VERSION ""

NS_ :

BS_:

BU_: Vector__XXX

BO_ 2566588414 NTEHV: 68 Vector__XXX
SG_ NOxTrackValdNOxLifetmEgRnTmBin1 : 0|32@1+ (1,0) [0|4211081215] "s" Vector__XXX
SG_ NOxTrackValdNOxLifetmEgRnTmBin2 : 32|32@1+ (1,0) [0|4211081215] "s" Vector__XXX
SG_ NOxTrackValdNOxLifetmEgRnTmBin3 : 64|32@1+ (1,0) [0|4211081215] "s" Vector__XXX
SG_ NOxTrackValdNOxLifetmEgRnTmBin4 : 96|32@1+ (1,0) [0|4211081215] "s" Vector__XXX
SG_ NOxTrackValdNOxLifetmEgRnTmBin5 : 128|32@1+ (1,0) [0|4211081215] "s" Vector__XXX
SG_ NOxTrackValdNOxLifetmEgRnTmBin6 : 160|32@1+ (1,0) [0|4211081215] "s" Vector__XXX
SG_ NOxTrackValdNOxLifetmEgRnTmBin7 : 192|32@1+ (1,0) [0|4211081215] "s" Vector__XXX
SG_ NOxTrackValdNOxLifetmEgRnTmBin8 : 224|32@1+ (1,0) [0|4211081215] "s" Vector__XXX
SG_ NOxTrackValdNOxLifetmEgRnTmBin9 : 256|32@1+ (1,0) [0|4211081215] "s" Vector__XXX
SG_ NOxTrackValdNOxLifetmEgRnTmBin10 : 288|32@1+ (1,0) [0|4211081215] "s" Vector__XXX
SG_ NOxTrackValdNOxLifetmEgRnTmBin11 : 320|32@1+ (1,0) [0|4211081215] "s" Vector__XXX
SG_ NOxTrackValdNOxLifetmEgRnTmBin12 : 352|32@1+ (1,0) [0|4211081215] "s" Vector__XXX
SG_ NOxTrackValdNOxLifetmEgRnTmBin13 : 384|32@1+ (1,0) [0|4211081215] "s" Vector__XXX
SG_ NOxTrackValdNOxLifetmEgRnTmBin14 : 416|32@1+ (1,0) [0|4211081215] "s" Vector__XXX
SG_ NOxTrackValdNOxLifetmEgRnTmBin15 : 448|32@1+ (1,0) [0|4211081215] "s" Vector__XXX
SG_ NOxTrackValdNOxLifetmEgRnTmBin16 : 480|32@1+ (1,0) [0|4211081215] "s" Vector__XXX
SG_ NOxTrackValdNOxLifetmEgRnTmBin17 : 512|32@1+ (1,0) [0|4211081215] "s" Vector__XXX

BO_ 2566588670 NTVMV: 68 Vector__XXX
SG_ NOxTrackValdNOxLifetmVhclDstBin1 : 0|32@1+ (5,0) [0|21055406075] "m" Vector__XXX
SG_ NOxTrackValdNOxLifetmVhclDstBin2 : 32|32@1+ (5,0) [0|21055406075] "m" Vector__XXX
SG_ NOxTrackValdNOxLifetmVhclDstBin3 : 64|32@1+ (5,0) [0|21055406075] "m" Vector__XXX
SG_ NOxTrackValdNOxLifetmVhclDstBin4 : 96|32@1+ (5,0) [0|21055406075] "m" Vector__XXX
SG_ NOxTrackValdNOxLifetmVhclDstBin5 : 128|32@1+ (5,0) [0|21055406075] "m" Vector__XXX
SG_ NOxTrackValdNOxLifetmVhclDstBin6 : 160|32@1+ (5,0) [0|21055406075] "m" Vector__XXX
SG_ NOxTrackValdNOxLifetmVhclDstBin7 : 192|32@1+ (5,0) [0|21055406075] "m" Vector__XXX
SG_ NOxTrackValdNOxLifetmVhclDstBin8 : 224|32@1+ (5,0) [0|21055406075] "m" Vector__XXX
SG_ NOxTrackValdNOxLifetmVhclDstBin9 : 256|32@1+ (5,0) [0|21055406075] "m" Vector__XXX
SG_ NOxTrackValNOxLifetmVhclDstBin10 : 288|32@1+ (5,0) [0|21055406075] "m" Vector__XXX
SG_ NOxTrackValNOxLifetmVhclDstBin11 : 320|32@1+ (5,0) [0|21055406075] "m" Vector__XXX
SG_ NOxTrackValNOxLifetmVhclDstBin12 : 352|32@1+ (5,0) [0|21055406075] "m" Vector__XXX
SG_ NOxTrackValNOxLifetmVhclDstBin13 : 384|32@1+ (5,0) [0|21055406075] "m" Vector__XXX
SG_ NOxTrackValNOxLifetmVhclDstBin14 : 416|32@1+ (5,0) [0|21055406075] "m" Vector__XXX
SG_ NOxTrackValNOxLifetmVhclDstBin15 : 448|32@1+ (5,0) [0|21055406075] "m" Vector__XXX
SG_ NOxTrackValNOxLifetmVhclDstBin16 : 480|32@1+ (5,0) [0|21055406075] "m" Vector__XXX
SG_ NOxTrackValNOxLifetmVhclDstBin17 : 512|32@1+ (5,0) [0|21055406075] "m" Vector__XXX

BO_ 2566588926 NTEEV: 68 Vector__XXX
SG_ NOxTrackValNOxLifetmEgOutEgyBin1 : 0|32@1+ (1,0) [0|4211081215] "kWh" Vector__XXX
SG_ NOxTrackValNOxLifetmEgOutEgyBin2 : 32|32@1+ (1,0) [0|4211081215] "kWh" Vector__XXX
SG_ NOxTrackValNOxLifetmEgOutEgyBin3 : 64|32@1+ (1,0) [0|4211081215] "kWh" Vector__XXX
SG_ NOxTrackValNOxLifetmEgOutEgyBin4 : 96|32@1+ (1,0) [0|4211081215] "kWh" Vector__XXX
SG_ NOxTrackValNOxLifetmEgOutEgyBin5 : 128|32@1+ (1,0) [0|4211081215] "kWh" Vector__XXX
SG_ NOxTrackValNOxLifetmEgOutEgyBin6 : 160|32@1+ (1,0) [0|4211081215] "kWh" Vector__XXX
SG_ NOxTrackValNOxLifetmEgOutEgyBin7 : 192|32@1+ (1,0) [0|4211081215] "kWh" Vector__XXX
SG_ NOxTrackValNOxLifetmEgOutEgyBin8 : 224|32@1+ (1,0) [0|4211081215] "kWh" Vector__XXX
SG_ NOxTrackValNOxLifetmEgOutEgyBin9 : 256|32@1+ (1,0) [0|4211081215] "kWh" Vector__XXX
SG_ NOxTrackValNOxLftmEgOutEgyBin10 : 288|32@1+ (1,0) [0|4211081215] "kWh" Vector__XXX
SG_ NOxTrackValNOxLftmEgOutEgyBin11 : 320|32@1+ (1,0) [0|4211081215] "kWh" Vector__XXX
SG_ NOxTrackValNOxLftmEgOutEgyBin12 : 352|32@1+ (1,0) [0|4211081215] "kWh" Vector__XXX
SG_ NOxTrackValNOxLftmEgOutEgyBin13 : 384|32@1+ (1,0) [0|4211081215] "kWh" Vector__XXX
SG_ NOxTrackValNOxLftmEgOutEgyBin14 : 416|32@1+ (1,0) [0|4211081215] "kWh" Vector__XXX
SG_ NOxTrackValNOxLftmEgOutEgyBin15 : 448|32@1+ (1,0) [0|4211081215] "kWh" Vector__XXX
SG_ NOxTrackValNOxLftmEgOutEgyBin16 : 480|32@1+ (1,0) [0|4211081215] "kWh" Vector__XXX
SG_ NOxTrackValNOxLftmEgOutEgyBin17 : 512|32@1+ (1,0) [0|4211081215] "kWh" Vector__XXX

BO_ 2566589182 NTENV: 68 Vector__XXX
SG_ NOxTrckValNOxLftEgOutNOxMassBin1 : 0|32@1+ (1,0) [0|4211081215] "g" Vector__XXX
SG_ NOxTrckValNOxLftEgOutNOxMassBin2 : 32|32@1+ (1,0) [0|4211081215] "g" Vector__XXX
SG_ NOxTrckValNOxLftEgOutNOxMassBin3 : 64|32@1+ (1,0) [0|4211081215] "g" Vector__XXX
SG_ NOxTrckValNOxLftEgOutNOxMassBin4 : 96|32@1+ (1,0) [0|4211081215] "g" Vector__XXX
SG_ NOxTrckValNOxLftEgOutNOxMassBin5 : 128|32@1+ (1,0) [0|4211081215] "g" Vector__XXX
SG_ NOxTrckValNOxLftEgOutNOxMassBin6 : 160|32@1+ (1,0) [0|4211081215] "g" Vector__XXX
SG_ NOxTrckValNOxLftEgOutNOxMassBin7 : 192|32@1+ (1,0) [0|4211081215] "g" Vector__XXX
SG_ NOxTrckValNOxLftEgOutNOxMassBin8 : 224|32@1+ (1,0) [0|4211081215] "g" Vector__XXX
SG_ NOxTrckValNOxLftEgOutNOxMassBin9 : 256|32@1+ (1,0) [0|4211081215] "g" Vector__XXX
SG_ NOxTrckValNOxLftmEgOutNOxMssBn10 : 288|32@1+ (1,0) [0|4211081215] "g" Vector__XXX
SG_ NOxTrckValNOxLftmEgOutNOxMssBn11 : 320|32@1+ (1,0) [0|4211081215] "g" Vector__XXX
SG_ NOxTrckValNOxLftmEgOutNOxMssBn12 : 352|32@1+ (1,0) [0|4211081215] "g" Vector__XXX
SG_ NOxTrckValNOxLftmEgOutNOxMssBn13 : 384|32@1+ (1,0) [0|4211081215] "g" Vector__XXX
SG_ NOxTrckValNOxLftmEgOutNOxMssBn14 : 416|32@1+ (1,0) [0|4211081215] "g" Vector__XXX
SG_ NOxTrckValNOxLftmEgOutNOxMssBn15 : 448|32@1+ (1,0) [0|4211081215] "g" Vector__XXX
SG_ NOxTrckValNOxLftmEgOutNOxMssBn16 : 480|32@1+ (1,0) [0|4211081215] "g" Vector__XXX
SG_ NOxTrckValNOxLftmEgOutNOxMssBn17 : 512|32@1+ (1,0) [0|4211081215] "g" Vector__XXX

BO_ 2566589438 NTSNV: 68 Vector__XXX
SG_ NOxTrckValNOxLftmSysOutNOxMssBn1 : 0|32@1+ (1,0) [0|4211081215] "g" Vector__XXX
SG_ NOxTrckValNOxLftmSysOutNOxMssBn2 : 32|32@1+ (1,0) [0|4211081215] "g" Vector__XXX
SG_ NOxTrckValNOxLftmSysOutNOxMssBn3 : 64|32@1+ (1,0) [0|4211081215] "g" Vector__XXX
SG_ NOxTrckValNOxLftmSysOutNOxMssBn4 : 96|32@1+ (1,0) [0|4211081215] "g" Vector__XXX
SG_ NOxTrckValNOxLftmSysOutNOxMssBn5 : 128|32@1+ (1,0) [0|4211081215] "g" Vector__XXX
SG_ NOxTrckValNOxLftmSysOutNOxMssBn6 : 160|32@1+ (1,0) [0|4211081215] "g" Vector__XXX
SG_ NOxTrckValNOxLftmSysOutNOxMssBn7 : 192|32@1+ (1,0) [0|4211081215] "g" Vector__XXX
SG_ NOxTrckValNOxLftmSysOutNOxMssBn8 : 224|32@1+ (1,0) [0|4211081215] "g" Vector__XXX
SG_ NOxTrckValNOxLftmSysOutNOxMssBn9 : 256|32@1+ (1,0) [0|4211081215] "g" Vector__XXX
SG_ NOxTrckValNOxLftSysOutNOxMssBn10 : 288|32@1+ (1,0) [0|4211081215] "g" Vector__XXX
SG_ NOxTrckValNOxLftSysOutNOxMssBn11 : 320|32@1+ (1,0) [0|4211081215] "g" Vector__XXX
SG_ NOxTrckValNOxLftSysOutNOxMssBn12 : 352|32@1+ (1,0) [0|4211081215] "g" Vector__XXX
SG_ NOxTrckValNOxLftSysOutNOxMssBn13 : 384|32@1+ (1,0) [0|4211081215] "g" Vector__XXX
SG_ NOxTrckValNOxLftSysOutNOxMssBn14 : 416|32@1+ (1,0) [0|4211081215] "g" Vector__XXX
SG_ NOxTrckValNOxLftSysOutNOxMssBn15 : 448|32@1+ (1,0) [0|4211081215] "g" Vector__XXX
SG_ NOxTrckValNOxLftSysOutNOxMssBn16 : 480|32@1+ (1,0) [0|4211081215] "g" Vector__XXX
SG_ NOxTrckValNOxLftSysOutNOxMssBn17 : 512|32@1+ (1,0) [0|4211081215] "g" Vector__XXX

BO_ 2566589694 NTFCS: 34 Vector__XXX
SG_ NOxTrackngStord100HrFlCnsmptnBn1 : 0|16@1+ (0.5,0) [0|32127.5] "l" Vector__XXX
SG_ NOxTrackngStord100HrFlCnsmptnBn2 : 16|16@1+ (0.5,0) [0|32127.5] "l" Vector__XXX
SG_ NOxTrackngStord100HrFlCnsmptnBn3 : 32|16@1+ (0.5,0) [0|32127.5] "l" Vector__XXX
SG_ NOxTrackngStord100HrFlCnsmptnBn4 : 48|16@1+ (0.5,0) [0|32127.5] "l" Vector__XXX
SG_ NOxTrackngStord100HrFlCnsmptnBn5 : 64|16@1+ (0.5,0) [0|32127.5] "l" Vector__XXX
SG_ NOxTrackngStord100HrFlCnsmptnBn6 : 80|16@1+ (0.5,0) [0|32127.5] "l" Vector__XXX
SG_ NOxTrackngStord100HrFlCnsmptnBn7 : 96|16@1+ (0.5,0) [0|32127.5] "l" Vector__XXX
SG_ NOxTrackngStord100HrFlCnsmptnBn8 : 112|16@1+ (0.5,0) [0|32127.5] "l" Vector__XXX
SG_ NOxTrackngStord100HrFlCnsmptnBn9 : 128|16@1+ (0.5,0) [0|32127.5] "l" Vector__XXX
SG_ NOxTrackngStord100HrFlCnsBn10 : 144|16@1+ (0.5,0) [0|32127.5] "l" Vector__XXX
SG_ NOxTrackngStord100HrFlCnsBn11 : 160|16@1+ (0.5,0) [0|32127.5] "l" Vector__XXX
SG_ NOxTrackngStord100HrFlCnsBn12 : 176|16@1+ (0.5,0) [0|32127.5] "l" Vector__XXX
SG_ NOxTrackngStord100HrFlCnsBn13 : 192|16@1+ (0.5,0) [0|32127.5] "l" Vector__XXX
SG_ NOxTrackngStord100HrFlCnsBn14 : 208|16@1+ (0.5,0) [0|32127.5] "l" Vector__XXX
SG_ NOxTrackngStord100HrFlCnsBn15 : 224|16@1+ (0.5,0) [0|32127.5] "l" Vector__XXX
SG_ NOxTrackngStord100HrFlCnsBn16 : 240|16@1+ (0.5,0) [0|32127.5] "l" Vector__XXX
SG_ NOxTrackngStord100HrFlCnsBn17 : 256|16@1+ (0.5,0) [0|32127.5] "l" Vector__XXX

BO_ 2566589950 NTEHS: 34 Vector__XXX
SG_ NOxTrackingStord100HrEngRnTmeBn1 : 0|16@1+ (10,0) [0|642550] "s" Vector__XXX
SG_ NOxTrackingStord100HrEngRnTmeBn2 : 16|16@1+ (10,0) [0|642550] "s" Vector__XXX
SG_ NOxTrackingStord100HrEngRnTmeBn3 : 32|16@1+ (10,0) [0|642550] "s" Vector__XXX
SG_ NOxTrackingStord100HrEngRnTmeBn4 : 48|16@1+ (10,0) [0|642550] "s" Vector__XXX
SG_ NOxTrackingStord100HrEngRnTmeBn5 : 64|16@1+ (10,0) [0|642550] "s" Vector__XXX
SG_ NOxTrackingStord100HrEngRnTmeBn6 : 80|16@1+ (10,0) [0|642550] "s" Vector__XXX
SG_ NOxTrackingStord100HrEngRnTmeBn7 : 96|16@1+ (10,0) [0|642550] "s" Vector__XXX
SG_ NOxTrackingStord100HrEngRnTmeBn8 : 112|16@1+ (10,0) [0|642550] "s" Vector__XXX
SG_ NOxTrackingStord100HrEngRnTmeBn9 : 128|16@1+ (10,0) [0|642550] "s" Vector__XXX
SG_ NOxTrackngStord100HrEngRnTmeBn10 : 144|16@1+ (10,0) [0|642550] "s" Vector__XXX
SG_ NOxTrackngStord100HrEngRnTmeBn11 : 160|16@1+ (10,0) [0|642550] "s" Vector__XXX
SG_ NOxTrackngStord100HrEngRnTmeBn12 : 176|16@1+ (10,0) [0|642550] "s" Vector__XXX
SG_ NOxTrackngStord100HrEngRnTmeBn13 : 192|16@1+ (10,0) [0|642550] "s" Vector__XXX
SG_ NOxTrackngStord100HrEngRnTmeBn14 : 208|16@1+ (10,0) [0|642550] "s" Vector__XXX
SG_ NOxTrackngStord100HrEngRnTmeBn15 : 224|16@1+ (10,0) [0|642550] "s" Vector__XXX
SG_ NOxTrackngStord100HrEngRnTmeBn16 : 240|16@1+ (10,0) [0|642550] "s" Vector__XXX
SG_ NOxTrackngStord100HrEngRnTmeBn17 : 256|16@1+ (10,0) [0|642550] "s" Vector__XXX

BO_ 2566590206 NTVMS: 34 Vector__XXX
SG_ NOxTrackngStord100HrVhclDistBn1 : 0|16@1+ (0.25,0) [0|16063.75] "km" Vector__XXX
SG_ NOxTrackngStord100HrVhclDistBn2 : 16|16@1+ (0.25,0) [0|16063.75] "km" Vector__XXX
SG_ NOxTrackngStord100HrVhclDistBn3 : 32|16@1+ (0.25,0) [0|16063.75] "km" Vector__XXX
SG_ NOxTrackngStord100HrVhclDistBn4 : 48|16@1+ (0.25,0) [0|16063.75] "km" Vector__XXX
SG_ NOxTrackngStord100HrVhclDistBn5 : 64|16@1+ (0.25,0) [0|16063.75] "km" Vector__XXX
SG_ NOxTrackngStord100HrVhclDistBn6 : 80|16@1+ (0.25,0) [0|16063.75] "km" Vector__XXX
SG_ NOxTrackngStord100HrVhclDistBn7 : 96|16@1+ (0.25,0) [0|16063.75] "km" Vector__XXX
SG_ NOxTrackngStord100HrVhclDistBn8 : 112|16@1+ (0.25,0) [0|16063.75] "km" Vector__XXX
SG_ NOxTrackngStord100HrVhclDistBn9 : 128|16@1+ (0.25,0) [0|16063.75] "km" Vector__XXX
SG_ NOxTrackngStord100HrVhclDistBn10 : 144|16@1+ (0.25,0) [0|16063.75] "km" Vector__XXX
SG_ NOxTrackngStord100HrVhclDistBn11 : 160|16@1+ (0.25,0) [0|16063.75] "km" Vector__XXX
SG_ NOxTrackngStord100HrVhclDistBn12 : 176|16@1+ (0.25,0) [0|16063.75] "km" Vector__XXX
SG_ NOxTrackngStord100HrVhclDistBn13 : 192|16@1+ (0.25,0) [0|16063.75] "km" Vector__XXX
SG_ NOxTrackngStord100HrVhclDistBn14 : 208|16@1+ (0.25,0) [0|16063.75] "km" Vector__XXX
SG_ NOxTrackngStord100HrVhclDistBn15 : 224|16@1+ (0.25,0) [0|16063.75] "km" Vector__XXX
SG_ NOxTrackngStord100HrVhclDistBn16 : 240|16@1+ (0.25,0) [0|16063.75] "km" Vector__XXX
SG_ NOxTrackngStord100HrVhclDistBn17 : 256|16@1+ (0.25,0) [0|16063.75] "km" Vector__XXX

BO_ 2566590462 NTEES: 34 Vector__XXX
SG_ NOxTrackngStord100HrEgOutEgyBn1 : 0|16@1+ (1,0) [0|64255] "kWh" Vector__XXX
SG_ NOxTrackngStord100HrEgOutEgyBn2 : 16|16@1+ (1,0) [0|64255] "kWh" Vector__XXX
SG_ NOxTrackngStord100HrEgOutEgyBn3 : 32|16@1+ (1,0) [0|64255] "kWh" Vector__XXX
SG_ NOxTrackngStord100HrEgOutEgyBn4 : 48|16@1+ (1,0) [0|64255] "kWh" Vector__XXX
SG_ NOxTrackngStord100HrEgOutEgyBn5 : 64|16@1+ (1,0) [0|64255] "kWh" Vector__XXX
SG_ NOxTrackngStord100HrEgOutEgyBn6 : 80|16@1+ (1,0) [0|64255] "kWh" Vector__XXX
SG_ NOxTrackngStord100HrEgOutEgyBn7 : 96|16@1+ (1,0) [0|64255] "kWh" Vector__XXX
SG_ NOxTrackngStord100HrEgOutEgyBn8 : 112|16@1+ (1,0) [0|64255] "kWh" Vector__XXX
SG_ NOxTrackngStord100HrEgOutEgyBn9 : 128|16@1+ (1,0) [0|64255] "kWh" Vector__XXX
SG_ NOxTrackngStord100HrEgOutEgyBn10 : 144|16@1+ (1,0) [0|64255] "kWh" Vector__XXX
SG_ NOxTrackngStord100HrEgOutEgyBn11 : 160|16@1+ (1,0) [0|64255] "kWh" Vector__XXX
SG_ NOxTrackngStord100HrEgOutEgyBn12 : 176|16@1+ (1,0) [0|64255] "kWh" Vector__XXX
SG_ NOxTrackngStord100HrEgOutEgyBn13 : 192|16@1+ (1,0) [0|64255] "kWh" Vector__XXX
SG_ NOxTrackngStord100HrEgOutEgyBn14 : 208|16@1+ (1,0) [0|64255] "kWh" Vector__XXX
SG_ NOxTrackngStord100HrEgOutEgyBn15 : 224|16@1+ (1,0) [0|64255] "kWh" Vector__XXX
SG_ NOxTrackngStord100HrEgOutEgyBn16 : 240|16@1+ (1,0) [0|64255] "kWh" Vector__XXX
SG_ NOxTrackngStord100HrEgOutEgyBn17 : 256|16@1+ (1,0) [0|64255] "kWh" Vector__XXX

BO_ 2566590718 NTENS: 68 Vector__XXX
SG_ NOxTrackStrd100HrEgOutNOxMssBn1 : 0|32@1+ (0.0005,0) [0|2105540.6075] "g" Vector__XXX
SG_ NOxTrackStrd100HrEgOutNOxMssBn2 : 32|32@1+ (0.0005,0) [0|2105540.6075] "g" Vector__XXX
SG_ NOxTrackStrd100HrEgOutNOxMssBn3 : 64|32@1+ (0.0005,0) [0|2105540.6075] "g" Vector__XXX
SG_ NOxTrackStrd100HrEgOutNOxMssBn4 : 96|32@1+ (0.0005,0) [0|2105540.6075] "g" Vector__XXX
SG_ NOxTrackStrd100HrEgOutNOxMssBn5 : 128|32@1+ (0.0005,0) [0|2105540.6075] "g" Vector__XXX
SG_ NOxTrackStrd100HrEgOutNOxMssBn6 : 160|32@1+ (0.0005,0) [0|2105540.6075] "g" Vector__XXX
SG_ NOxTrackStrd100HrEgOutNOxMssBn7 : 192|32@1+ (0.0005,0) [0|2105540.6075] "g" Vector__XXX
SG_ NOxTrackStrd100HrEgOutNOxMssBn8 : 224|32@1+ (0.0005,0) [0|2105540.6075] "g" Vector__XXX
SG_ NOxTrackStrd100HrEgOutNOxMssBn9 : 256|32@1+ (0.0005,0) [0|2105540.6075] "g" Vector__XXX
SG_ NOxTrackStrd100HrEgOutNOxMssBn10 : 288|32@1+ (0.0005,0) [0|2105540.6075] "g" Vector__XXX
SG_ NOxTrackStrd100HrEgOutNOxMssBn11 : 320|32@1+ (0.0005,0) [0|2105540.6075] "g" Vector__XXX
SG_ NOxTrackStrd100HrEgOutNOxMssBn12 : 352|32@1+ (0.0005,0) [0|2105540.6075] "g" Vector__XXX
SG_ NOxTrackStrd100HrEgOutNOxMssBn13 : 384|32@1+ (0.0005,0) [0|2105540.6075] "g" Vector__XXX
SG_ NOxTrackStrd100HrEgOutNOxMssBn14 : 416|32@1+ (0.0005,0) [0|2105540.6075] "g" Vector__XXX
SG_ NOxTrackStrd100HrEgOutNOxMssBn15 : 448|32@1+ (0.0005,0) [0|2105540.6075] "g" Vector__XXX
SG_ NOxTrackStrd100HrEgOutNOxMssBn16 : 480|32@1+ (0.0005,0) [0|2105540.6075] "g" Vector__XXX
SG_ NOxTrackStrd100HrEgOutNOxMssBn17 : 512|32@1+ (0.0005,0) [0|2105540.6075] "g" Vector__XXX

BO_ 2566590974 NTSNS: 68 Vector__XXX
SG_ NOxTrackStrd100HrSysOutNOxMssBn1 : 0|32@1+ (0.0002,0) [0|842216.243] "g" Vector__XXX
SG_ NOxTrackStrd100HrSysOutNOxMssBn2 : 32|32@1+ (0.0002,0) [0|842216.243] "g" Vector__XXX
SG_ NOxTrackStrd100HrSysOutNOxMssBn3 : 64|32@1+ (0.0002,0) [0|842216.243] "g" Vector__XXX
SG_ NOxTrackStrd100HrSysOutNOxMssBn4 : 96|32@1+ (0.0002,0) [0|842216.243] "g" Vector__XXX
SG_ NOxTrackStrd100HrSysOutNOxMssBn5 : 128|32@1+ (0.0002,0) [0|842216.243] "g" Vector__XXX
SG_ NOxTrackStrd100HrSysOutNOxMssBn6 : 160|32@1+ (0.0002,0) [0|842216.243] "g" Vector__XXX
SG_ NOxTrackStrd100HrSysOutNOxMssBn7 : 192|32@1+ (0.0002,0) [0|842216.243] "g" Vector__XXX
SG_ NOxTrackStrd100HrSysOutNOxMssBn8 : 224|32@1+ (0.0002,0) [0|842216.243] "g" Vector__XXX
SG_ NOxTrackStrd100HrSysOutNOxMssBn9 : 256|32@1+ (0.0002,0) [0|842216.243] "g" Vector__XXX
SG_ NOxTrckStrd100HrSysOutNOxMssBn10 : 288|32@1+ (0.0002,0) [0|842216.243] "g" Vector__XXX
SG_ NOxTrckStrd100HrSysOutNOxMssBn11 : 320|32@1+ (0.0002,0) [0|842216.243] "g" Vector__XXX
SG_ NOxTrckStrd100HrSysOutNOxMssBn12 : 352|32@1+ (0.0002,0) [0|842216.243] "g" Vector__XXX
SG_ NOxTrckStrd100HrSysOutNOxMssBn13 : 384|32@1+ (0.0002,0) [0|842216.243] "g" Vector__XXX
SG_ NOxTrckStrd100HrSysOutNOxMssBn14 : 416|32@1+ (0.0002,0) [0|842216.243] "g" Vector__XXX
SG_ NOxTrckStrd100HrSysOutNOxMssBn15 : 448|32@1+ (0.0002,0) [0|842216.243] "g" Vector__XXX
SG_ NOxTrckStrd100HrSysOutNOxMssBn16 : 480|32@1+ (0.0002,0) [0|842216.243] "g" Vector__XXX
SG_ NOxTrckStrd100HrSysOutNOxMssBn17 : 512|32@1+ (0.0002,0) [0|842216.243] "g" Vector__XXX

BO_ 2566591230 NTFCA: 34 Vector__XXX
SG_ NOxTrackingActv100HrFlCnsmptnBn1 : 0|16@1+ (0.5,0) [0|32127.5] "l" Vector__XXX
SG_ NOxTrackingActv100HrFlCnsmptnBn2 : 16|16@1+ (0.5,0) [0|32127.5] "l" Vector__XXX
SG_ NOxTrackingActv100HrFlCnsmptnBn3 : 32|16@1+ (0.5,0) [0|32127.5] "l" Vector__XXX
SG_ NOxTrackingActv100HrFlCnsmptnBn4 : 48|16@1+ (0.5,0) [0|32127.5] "l" Vector__XXX
SG_ NOxTrackingActv100HrFlCnsmptnBn5 : 64|16@1+ (0.5,0) [0|32127.5] "l" Vector__XXX
SG_ NOxTrackingActv100HrFlCnsmptnBn6 : 80|16@1+ (0.5,0) [0|32127.5] "l" Vector__XXX
SG_ NOxTrackingActv100HrFlCnsmptnBn7 : 96|16@1+ (0.5,0) [0|32127.5] "l" Vector__XXX
SG_ NOxTrackingActv100HrFlCnsmptnBn8 : 112|16@1+ (0.5,0) [0|32127.5] "l" Vector__XXX
SG_ NOxTrackingActv100HrFlCnsmptnBn9 : 128|16@1+ (0.5,0) [0|32127.5] "l" Vector__XXX
SG_ NOxTrackngActv100HrFlCnsmptnBn10 : 144|16@1+ (0.5,0) [0|32127.5] "l" Vector__XXX
SG_ NOxTrackngActv100HrFlCnsmptnBn11 : 160|16@1+ (0.5,0) [0|32127.5] "l" Vector__XXX
SG_ NOxTrackngActv100HrFlCnsmptnBn12 : 176|16@1+ (0.5,0) [0|32127.5] "l" Vector__XXX
SG_ NOxTrackngActv100HrFlCnsmptnBn13 : 192|16@1+ (0.5,0) [0|32127.5] "l" Vector__XXX
SG_ NOxTrackngActv100HrFlCnsmptnBn14 : 208|16@1+ (0.5,0) [0|32127.5] "l" Vector__XXX
SG_ NOxTrackngActv100HrFlCnsmptnBn15 : 224|16@1+ (0.5,0) [0|32127.5] "l" Vector__XXX
SG_ NOxTrackngActv100HrFlCnsmptnBn16 : 240|16@1+ (0.5,0) [0|32127.5] "l" Vector__XXX
SG_ NOxTrackngActv100HrFlCnsmptnBn17 : 256|16@1+ (0.5,0) [0|32127.5] "l" Vector__XXX

BO_ 2566591486 NTEHA: 34 Vector__XXX
SG_ NOxTrackingActv100HrEngRnTimeBn1 : 0|16@1+ (10,0) [0|642550] "s" Vector__XXX
SG_ NOxTrackingActv100HrEngRnTimeBn2 : 16|16@1+ (10,0) [0|642550] "s" Vector__XXX
SG_ NOxTrackingActv100HrEngRnTimeBn3 : 32|16@1+ (10,0) [0|642550] "s" Vector__XXX
SG_ NOxTrackingActv100HrEngRnTimeBn4 : 48|16@1+ (10,0) [0|642550] "s" Vector__XXX
SG_ NOxTrackingActv100HrEngRnTimeBn5 : 64|16@1+ (10,0) [0|642550] "s" Vector__XXX
SG_ NOxTrackingActv100HrEngRnTimeBn6 : 80|16@1+ (10,0) [0|642550] "s" Vector__XXX
SG_ NOxTrackingActv100HrEngRnTimeBn7 : 96|16@1+ (10,0) [0|642550] "s" Vector__XXX
SG_ NOxTrackingActv100HrEngRnTimeBn8 : 112|16@1+ (10,0) [0|642550] "s" Vector__XXX
SG_ NOxTrackingActv100HrEngRnTimeBn9 : 128|16@1+ (10,0) [0|642550] "s" Vector__XXX
SG_ NOxTrackingActv100HrEngRnTmeBn10 : 144|16@1+ (10,0) [0|642550] "s" Vector__XXX
SG_ NOxTrackingActv100HrEngRnTmeBn11 : 160|16@1+ (10,0) [0|642550] "s" Vector__XXX
SG_ NOxTrackingActv100HrEngRnTmeBn12 : 176|16@1+ (10,0) [0|642550] "s" Vector__XXX
SG_ NOxTrackingActv100HrEngRnTmeBn13 : 192|16@1+ (10,0) [0|642550] "s" Vector__XXX
SG_ NOxTrackingActv100HrEngRnTmeBn14 : 208|16@1+ (10,0) [0|642550] "s" Vector__XXX
SG_ NOxTrackingActv100HrEngRnTmeBn15 : 224|16@1+ (10,0) [0|642550] "s" Vector__XXX
SG_ NOxTrackingActv100HrEngRnTmeBn16 : 240|16@1+ (10,0) [0|642550] "s" Vector__XXX
SG_ NOxTrackingActv100HrEngRnTmeBn17 : 256|16@1+ (10,0) [0|642550] "s" Vector__XXX

BO_ 2566591742 NTVMA: 34 Vector__XXX
SG_ NOxTrackngActv100HrVhclDistBn1 : 0|16@1+ (0.25,0) [0|16063.75] "km" Vector__XXX
SG_ NOxTrackngActv100HrVhclDistBn2 : 16|16@1+ (0.25,0) [0|16063.75] "km" Vector__XXX
SG_ NOxTrackngActv100HrVhclDistBn3 : 32|16@1+ (0.25,0) [0|16063.75] "km" Vector__XXX
SG_ NOxTrackngActv100HrVhclDistBn4 : 48|16@1+ (0.25,0) [0|16063.75] "km" Vector__XXX
SG_ NOxTrackngActv100HrVhclDistBn5 : 64|16@1+ (0.25,0) [0|16063.75] "km" Vector__XXX
SG_ NOxTrackngActv100HrVhclDistBn6 : 80|16@1+ (0.25,0) [0|16063.75] "km" Vector__XXX
SG_ NOxTrackngActv100HrVhclDistBn7 : 96|16@1+ (0.25,0) [0|16063.75] "km" Vector__XXX
SG_ NOxTrackngActv100HrVhclDistBn8 : 112|16@1+ (0.25,0) [0|16063.75] "km" Vector__XXX
SG_ NOxTrackngActv100HrVhclDistBn9 : 128|16@1+ (0.25,0) [0|16063.75] "km" Vector__XXX
SG_ NOxTrackngActv100HrVhclDistBn10 : 144|16@1+ (0.25,0) [0|16063.75] "km" Vector__XXX
SG_ NOxTrackngActv100HrVhclDistBn11 : 160|16@1+ (0.25,0) [0|16063.75] "km" Vector__XXX
SG_ NOxTrackngActv100HrVhclDistBn12 : 176|16@1+ (0.25,0) [0|16063.75] "km" Vector__XXX
SG_ NOxTrackngActv100HrVhclDistBn13 : 192|16@1+ (0.25,0) [0|16063.75] "km" Vector__XXX
SG_ NOxTrackngActv100HrVhclDistBn14 : 208|16@1+ (0.25,0) [0|16063.75] "km" Vector__XXX
SG_ NOxTrackngActv100HrVhclDistBn15 : 224|16@1+ (0.25,0) [0|16063.75] "km" Vector__XXX
SG_ NOxTrackngActv100HrVhclDistBn16 : 240|16@1+ (0.25,0) [0|16063.75] "km" Vector__XXX
SG_ NOxTrackngActv100HrVhclDistBn17 : 256|16@1+ (0.25,0) [0|16063.75] "km" Vector__XXX

BO_ 2566591998 NTEEA: 34 Vector__XXX
SG_ NOxTrackngAct100HrEgOutptEngyBn1 : 0|16@1+ (1,0) [0|64255] "kWh" Vector__XXX
SG_ NOxTrackngAct100HrEgOutptEngyBn2 : 16|16@1+ (1,0) [0|64255] "kWh" Vector__XXX
SG_ NOxTrackngAct100HrEgOutptEngyBn3 : 32|16@1+ (1,0) [0|64255] "kWh" Vector__XXX
SG_ NOxTrackngAct100HrEgOutptEngyBn4 : 48|16@1+ (1,0) [0|64255] "kWh" Vector__XXX
SG_ NOxTrackngAct100HrEgOutptEngyBn5 : 64|16@1+ (1,0) [0|64255] "kWh" Vector__XXX
SG_ NOxTrackngAct100HrEgOutptEngyBn6 : 80|16@1+ (1,0) [0|64255] "kWh" Vector__XXX
SG_ NOxTrackngAct100HrEgOutptEngyBn7 : 96|16@1+ (1,0) [0|64255] "kWh" Vector__XXX
SG_ NOxTrackngAct100HrEgOutptEngyBn8 : 112|16@1+ (1,0) [0|64255] "kWh" Vector__XXX
SG_ NOxTrackngAct100HrEgOutptEngyBn9 : 128|16@1+ (1,0) [0|64255] "kWh" Vector__XXX
SG_ NOxTrackngAct100HrEgOutptEgyBn10 : 144|16@1+ (1,0) [0|64255] "kWh" Vector__XXX
SG_ NOxTrackngAct100HrEgOutptEgyBn11 : 160|16@1+ (1,0) [0|64255] "kWh" Vector__XXX
SG_ NOxTrackngAct100HrEgOutptEgyBn12 : 176|16@1+ (1,0) [0|64255] "kWh" Vector__XXX
SG_ NOxTrackngAct100HrEgOutptEgyBn13 : 192|16@1+ (1,0) [0|64255] "kWh" Vector__XXX
SG_ NOxTrackngAct100HrEgOutptEgyBn14 : 208|16@1+ (1,0) [0|64255] "kWh" Vector__XXX
SG_ NOxTrackngAct100HrEgOutptEgyBn15 : 224|16@1+ (1,0) [0|64255] "kWh" Vector__XXX
SG_ NOxTrackngAct100HrEgOutptEgyBn16 : 240|16@1+ (1,0) [0|64255] "kWh" Vector__XXX
SG_ NOxTrackngAct100HrEgOutptEgyBn17 : 256|16@1+ (1,0) [0|64255] "kWh" Vector__XXX

BO_ 2566592254 NTENA: 68 Vector__XXX
SG_ NOxTrackngAct100HrEgOutNOxMssBn1 : 0|32@1+ (0.0005,0) [0|2105540.6075] "g" Vector__XXX
SG_ NOxTrackngAct100HrEgOutNOxMssBn2 : 32|32@1+ (0.0005,0) [0|2105540.6075] "g" Vector__XXX
SG_ NOxTrackngAct100HrEgOutNOxMssBn3 : 64|32@1+ (0.0005,0) [0|2105540.6075] "g" Vector__XXX
SG_ NOxTrackngAct100HrEgOutNOxMssBn4 : 96|32@1+ (0.0005,0) [0|2105540.6075] "g" Vector__XXX
SG_ NOxTrackngAct100HrEgOutNOxMssBn5 : 128|32@1+ (0.0005,0) [0|2105540.6075] "g" Vector__XXX
SG_ NOxTrackngAct100HrEgOutNOxMssBn6 : 160|32@1+ (0.0005,0) [0|2105540.6075] "g" Vector__XXX
SG_ NOxTrackngAct100HrEgOutNOxMssBn7 : 192|32@1+ (0.0005,0) [0|2105540.6075] "g" Vector__XXX
SG_ NOxTrackngAct100HrEgOutNOxMssBn8 : 224|32@1+ (0.0005,0) [0|2105540.6075] "g" Vector__XXX
SG_ NOxTrackngAct100HrEgOutNOxMssBn9 : 256|32@1+ (0.0005,0) [0|2105540.6075] "g" Vector__XXX
SG_ NOxTrackAct100HrEgOutNOxMssBn10 : 288|32@1+ (0.0005,0) [0|2105540.6075] "g" Vector__XXX
SG_ NOxTrackAct100HrEgOutNOxMssBn11 : 320|32@1+ (0.0005,0) [0|2105540.6075] "g" Vector__XXX
SG_ NOxTrackAct100HrEgOutNOxMssBn12 : 352|32@1+ (0.0005,0) [0|2105540.6075] "g" Vector__XXX
SG_ NOxTrackAct100HrEgOutNOxMssBn13 : 384|32@1+ (0.0005,0) [0|2105540.6075] "g" Vector__XXX
SG_ NOxTrackAct100HrEgOutNOxMssBn14 : 416|32@1+ (0.0005,0) [0|2105540.6075] "g" Vector__XXX
SG_ NOxTrackAct100HrEgOutNOxMssBn15 : 448|32@1+ (0.0005,0) [0|2105540.6075] "g" Vector__XXX
SG_ NOxTrackAct100HrEgOutNOxMssBn16 : 480|32@1+ (0.0005,0) [0|2105540.6075] "g" Vector__XXX
SG_ NOxTrackAct100HrEgOutNOxMssBn17 : 512|32@1+ (0.0005,0) [0|2105540.6075] "g" Vector__XXX

BO_ 2566592510 NTSNA: 68 Vector__XXX
SG_ NOxTrackAct100HrSysOutNOxMssBn1 : 0|32@1+ (0.0002,0) [0|842216.243] "g" Vector__XXX
SG_ NOxTrackAct100HrSysOutNOxMssBn2 : 32|32@1+ (0.0002,0) [0|842216.243] "g" Vector__XXX
SG_ NOxTrackAct100HrSysOutNOxMssBn3 : 64|32@1+ (0.0002,0) [0|842216.243] "g" Vector__XXX
SG_ NOxTrackAct100HrSysOutNOxMssBn4 : 96|32@1+ (0.0002,0) [0|842216.243] "g" Vector__XXX
SG_ NOxTrackAct100HrSysOutNOxMssBn5 : 128|32@1+ (0.0002,0) [0|842216.243] "g" Vector__XXX
SG_ NOxTrackAct100HrSysOutNOxMssBn6 : 160|32@1+ (0.0002,0) [0|842216.243] "g" Vector__XXX
SG_ NOxTrackAct100HrSysOutNOxMssBn7 : 192|32@1+ (0.0002,0) [0|842216.243] "g" Vector__XXX
SG_ NOxTrackAct100HrSysOutNOxMssBn8 : 224|32@1+ (0.0002,0) [0|842216.243] "g" Vector__XXX
SG_ NOxTrackAct100HrSysOutNOxMssBn9 : 256|32@1+ (0.0002,0) [0|842216.243] "g" Vector__XXX
SG_ NOxTrackAct100HrSysOutNOxMssBn10 : 288|32@1+ (0.0002,0) [0|842216.243] "g" Vector__XXX
SG_ NOxTrackAct100HrSysOutNOxMssBn11 : 320|32@1+ (0.0002,0) [0|842216.243] "g" Vector__XXX
SG_ NOxTrackAct100HrSysOutNOxMssBn12 : 352|32@1+ (0.0002,0) [0|842216.243] "g" Vector__XXX
SG_ NOxTrackAct100HrSysOutNOxMssBn13 : 384|32@1+ (0.0002,0) [0|842216.243] "g" Vector__XXX
SG_ NOxTrackAct100HrSysOutNOxMssBn14 : 416|32@1+ (0.0002,0) [0|842216.243] "g" Vector__XXX
SG_ NOxTrackAct100HrSysOutNOxMssBn15 : 448|32@1+ (0.0002,0) [0|842216.243] "g" Vector__XXX
SG_ NOxTrackAct100HrSysOutNOxMssBn16 : 480|32@1+ (0.0002,0) [0|842216.243] "g" Vector__XXX
SG_ NOxTrackAct100HrSysOutNOxMssBn17 : 512|32@1+ (0.0002,0) [0|842216.243] "g" Vector__XXX

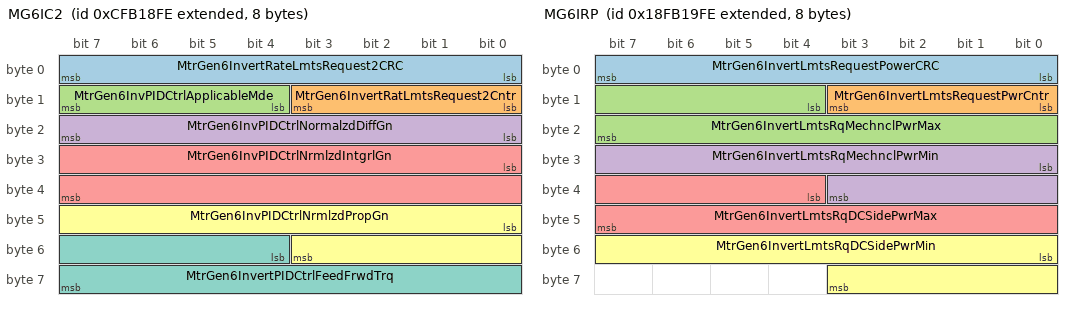
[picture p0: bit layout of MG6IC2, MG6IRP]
BO_ 2365266174 MG6IC2: 8 Vector__XXX
SG_ MtrGen6InvertRateLmtsRequest2CRC : 0|8@1+ (1,0) [0|255] "" Vector__XXX
SG_ MtrGen6InvertRatLmtsRequest2Cntr : 8|4@1+ (1,0) [0|15] "" Vector__XXX
SG_ MtrGen6InvPIDCtrlApplicableMde : 12|4@1+ (1,0) [0|15] "" Vector__XXX
SG_ MtrGen6InvPIDCtrlNormalzdDiffGn : 16|8@1+ (0.03125,0) [0|7.8125] "%/(%/s)" Vector__XXX
SG_ MtrGen6InvPIDCtrlNrmlzdIntgrlGn : 24|16@1+ (0.015625,0) [0|1003.984375] "%/(%*s)" Vector__XXX
SG_ MtrGen6InvPIDCtrlNrmlzdPropGn : 40|12@1+ (0.0625,0) [0|250.9375] "%/%" Vector__XXX
SG_ MtrGen6InvertPIDCtrlFeedFrwdTrq : 52|12@1+ (0.0625,-125) [-125|125.9375] "%" Vector__XXX

BO_ 2566593022 MG6IRP: 8 Vector__XXX
SG_ MtrGen6InvertLmtsRequestPowerCRC : 0|8@1+ (1,0) [0|255] "" Vector__XXX
SG_ MtrGen6InvertLmtsRequestPwrCntr : 8|4@1+ (1,0) [0|15] "" Vector__XXX
SG_ MtrGen6InvertLmtsRqMechnclPwrMax : 12|12@1+ (0.0625,-125) [-125|125.9375] "%" Vector__XXX
SG_ MtrGen6InvertLmtsRqMechnclPwrMin : 24|12@1+ (0.0625,-125) [-125|125.9375] "%" Vector__XXX
SG_ MtrGen6InvertLmtsRqDCSidePwrMax : 36|12@1+ (0.0625,-125) [-125|125.9375] "%" Vector__XXX
SG_ MtrGen6InvertLmtsRqDCSidePwrMin : 48|12@1+ (0.0625,-125) [-125|125.9375] "%" Vector__XXX

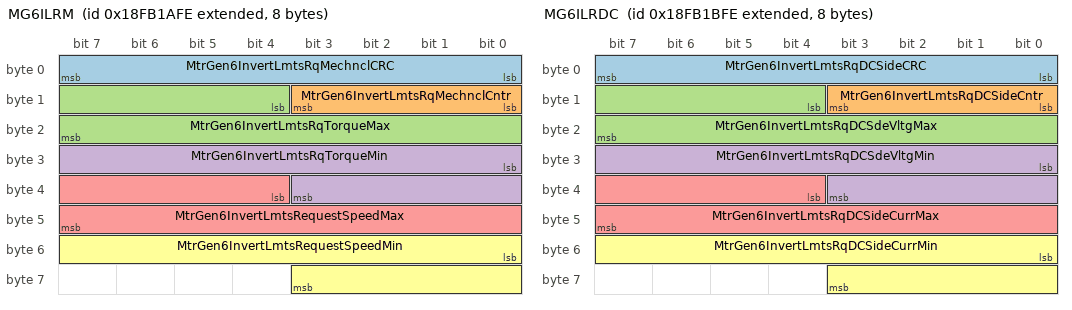
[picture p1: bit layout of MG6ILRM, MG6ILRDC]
BO_ 2566593278 MG6ILRM: 8 Vector__XXX
SG_ MtrGen6InvertLmtsRqMechnclCRC : 0|8@1+ (1,0) [0|255] "" Vector__XXX
SG_ MtrGen6InvertLmtsRqMechnclCntr : 8|4@1+ (1,0) [0|15] "" Vector__XXX
SG_ MtrGen6InvertLmtsRqTorqueMax : 12|12@1+ (0.0625,-125) [-125|125.9375] "%" Vector__XXX
SG_ MtrGen6InvertLmtsRqTorqueMin : 24|12@1+ (0.0625,-125) [-125|125.9375] "%" Vector__XXX
SG_ MtrGen6InvertLmtsRequestSpeedMax : 36|12@1+ (0.0625,-125) [-125|125.9375] "%" Vector__XXX
SG_ MtrGen6InvertLmtsRequestSpeedMin : 48|12@1+ (0.0625,-125) [-125|125.9375] "%" Vector__XXX

BO_ 2566593534 MG6ILRDC: 8 Vector__XXX
SG_ MtrGen6InvertLmtsRqDCSideCRC : 0|8@1+ (1,0) [0|255] "" Vector__XXX
SG_ MtrGen6InvertLmtsRqDCSideCntr : 8|4@1+ (1,0) [0|15] "" Vector__XXX
SG_ MtrGen6InvertLmtsRqDCSdeVltgMax : 12|12@1+ (0.0625,-125) [-125|125.9375] "%" Vector__XXX
SG_ MtrGen6InvertLmtsRqDCSdeVltgMin : 24|12@1+ (0.0625,-125) [-125|125.9375] "%" Vector__XXX
SG_ MtrGen6InvertLmtsRqDCSideCurrMax : 36|12@1+ (0.0625,-125) [-125|125.9375] "%" Vector__XXX
SG_ MtrGen6InvertLmtsRqDCSideCurrMin : 48|12@1+ (0.0625,-125) [-125|125.9375] "%" Vector__XXX

BO_ 2566593790 MG6IIR: 8 Vector__XXX
SG_ MtrGen6InvHiVBusActIsoltnTtCmd : 0|2@1+ (1,0) [0|3] "" Vector__XXX
SG_ MtrGen6InvHiVBusPassIsoltnTtCmd : 2|2@1+ (1,0) [0|3] "" Vector__XXX
SG_ MtrGen6InvHVBusHiSdeRsstrCnnctRq : 4|2@1+ (1,0) [0|3] "" Vector__XXX
SG_ MtrGen6InvHVBusLoSdeRsstrCnnctRq : 6|2@1+ (1,0) [0|3] "" Vector__XXX

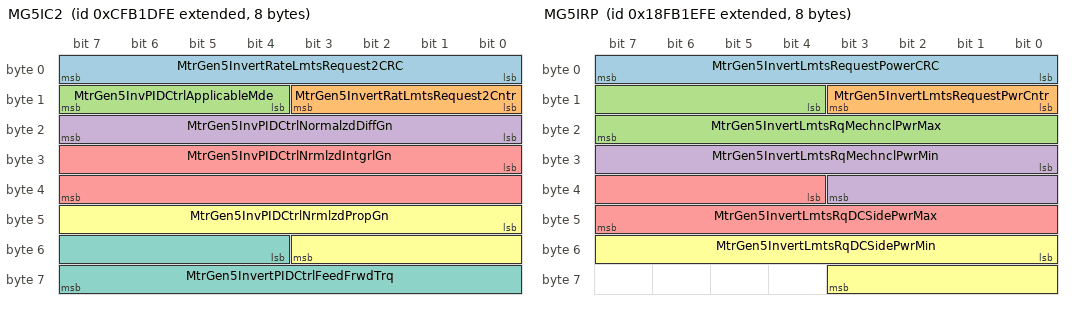
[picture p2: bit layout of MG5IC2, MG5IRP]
BO_ 2365267454 MG5IC2: 8 Vector__XXX
SG_ MtrGen5InvertRateLmtsRequest2CRC : 0|8@1+ (1,0) [0|255] "" Vector__XXX
SG_ MtrGen5InvertRatLmtsRequest2Cntr : 8|4@1+ (1,0) [0|15] "" Vector__XXX
SG_ MtrGen5InvPIDCtrlApplicableMde : 12|4@1+ (1,0) [0|15] "" Vector__XXX
SG_ MtrGen5InvPIDCtrlNormalzdDiffGn : 16|8@1+ (0.03125,0) [0|7.8125] "%/(%/s)" Vector__XXX
SG_ MtrGen5InvPIDCtrlNrmlzdIntgrlGn : 24|16@1+ (0.015625,0) [0|1003.984375] "%/(%*s)" Vector__XXX
SG_ MtrGen5InvPIDCtrlNrmlzdPropGn : 40|12@1+ (0.0625,0) [0|250.9375] "%/%" Vector__XXX
SG_ MtrGen5InvertPIDCtrlFeedFrwdTrq : 52|12@1+ (0.0625,-125) [-125|125.9375] "%" Vector__XXX

BO_ 2566594302 MG5IRP: 8 Vector__XXX
SG_ MtrGen5InvertLmtsRequestPowerCRC : 0|8@1+ (1,0) [0|255] "" Vector__XXX
SG_ MtrGen5InvertLmtsRequestPwrCntr : 8|4@1+ (1,0) [0|15] "" Vector__XXX
SG_ MtrGen5InvertLmtsRqMechnclPwrMax : 12|12@1+ (0.0625,-125) [-125|125.9375] "%" Vector__XXX
SG_ MtrGen5InvertLmtsRqMechnclPwrMin : 24|12@1+ (0.0625,-125) [-125|125.9375] "%" Vector__XXX
SG_ MtrGen5InvertLmtsRqDCSidePwrMax : 36|12@1+ (0.0625,-125) [-125|125.9375] "%" Vector__XXX
SG_ MtrGen5InvertLmtsRqDCSidePwrMin : 48|12@1+ (0.0625,-125) [-125|125.9375] "%" Vector__XXX

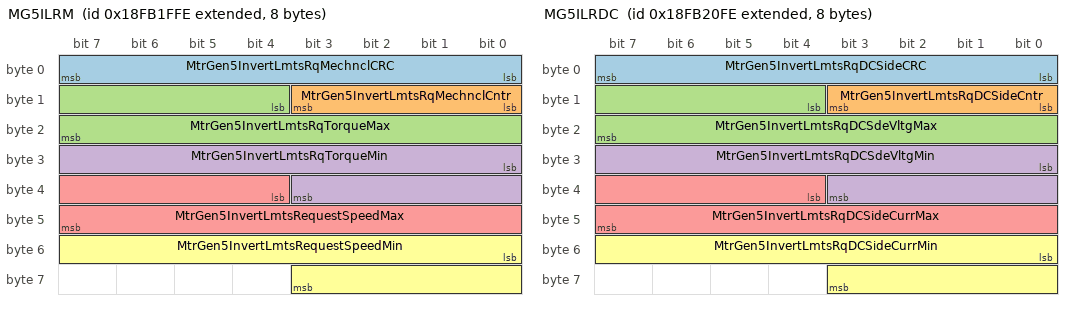
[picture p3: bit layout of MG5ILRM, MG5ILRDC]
BO_ 2566594558 MG5ILRM: 8 Vector__XXX
SG_ MtrGen5InvertLmtsRqMechnclCRC : 0|8@1+ (1,0) [0|255] "" Vector__XXX
SG_ MtrGen5InvertLmtsRqMechnclCntr : 8|4@1+ (1,0) [0|15] "" Vector__XXX
SG_ MtrGen5InvertLmtsRqTorqueMax : 12|12@1+ (0.0625,-125) [-125|125.9375] "%" Vector__XXX
SG_ MtrGen5InvertLmtsRqTorqueMin : 24|12@1+ (0.0625,-125) [-125|125.9375] "%" Vector__XXX
SG_ MtrGen5InvertLmtsRequestSpeedMax : 36|12@1+ (0.0625,-125) [-125|125.9375] "%" Vector__XXX
SG_ MtrGen5InvertLmtsRequestSpeedMin : 48|12@1+ (0.0625,-125) [-125|125.9375] "%" Vector__XXX

BO_ 2566594814 MG5ILRDC: 8 Vector__XXX
SG_ MtrGen5InvertLmtsRqDCSideCRC : 0|8@1+ (1,0) [0|255] "" Vector__XXX
SG_ MtrGen5InvertLmtsRqDCSideCntr : 8|4@1+ (1,0) [0|15] "" Vector__XXX
SG_ MtrGen5InvertLmtsRqDCSdeVltgMax : 12|12@1+ (0.0625,-125) [-125|125.9375] "%" Vector__XXX
SG_ MtrGen5InvertLmtsRqDCSdeVltgMin : 24|12@1+ (0.0625,-125) [-125|125.9375] "%" Vector__XXX
SG_ MtrGen5InvertLmtsRqDCSideCurrMax : 36|12@1+ (0.0625,-125) [-125|125.9375] "%" Vector__XXX
SG_ MtrGen5InvertLmtsRqDCSideCurrMin : 48|12@1+ (0.0625,-125) [-125|125.9375] "%" Vector__XXX

BO_ 2566595070 MG5IIR: 8 Vector__XXX
SG_ MtrGen5InvHiVBusActIsoltnTtCmd : 0|2@1+ (1,0) [0|3] "" Vector__XXX
SG_ MtrGen5InvHiVBusPassIsoltnTtCmd : 2|2@1+ (1,0) [0|3] "" Vector__XXX
SG_ MtrGen5InvHVBusHiSdeRsstrCnnctRq : 4|2@1+ (1,0) [0|3] "" Vector__XXX
SG_ MtrGen5InvHVBusLoSdeRsstrCnnctRq : 6|2@1+ (1,0) [0|3] "" Vector__XXX

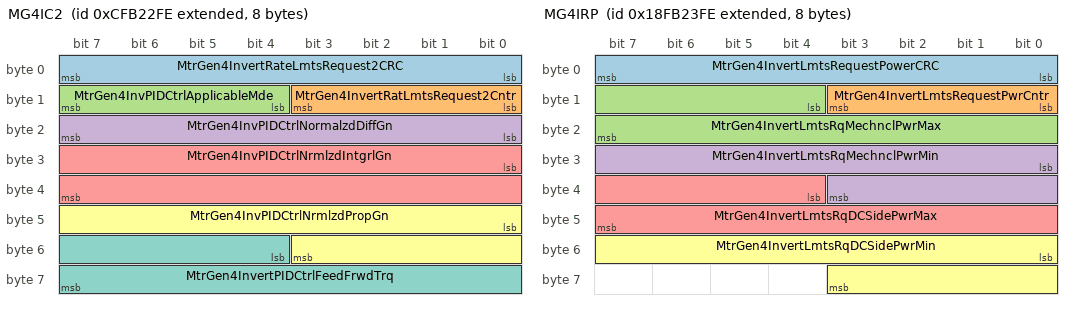
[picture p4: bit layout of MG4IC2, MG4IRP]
BO_ 2365268734 MG4IC2: 8 Vector__XXX
SG_ MtrGen4InvertRateLmtsRequest2CRC : 0|8@1+ (1,0) [0|255] "" Vector__XXX
SG_ MtrGen4InvertRatLmtsRequest2Cntr : 8|4@1+ (1,0) [0|15] "" Vector__XXX
SG_ MtrGen4InvPIDCtrlApplicableMde : 12|4@1+ (1,0) [0|15] "" Vector__XXX
SG_ MtrGen4InvPIDCtrlNormalzdDiffGn : 16|8@1+ (0.03125,0) [0|7.8125] "%/(%/s)" Vector__XXX
SG_ MtrGen4InvPIDCtrlNrmlzdIntgrlGn : 24|16@1+ (0.015625,0) [0|1003.984375] "%/(%*s)" Vector__XXX
SG_ MtrGen4InvPIDCtrlNrmlzdPropGn : 40|12@1+ (0.0625,0) [0|250.9375] "%/%" Vector__XXX
SG_ MtrGen4InvertPIDCtrlFeedFrwdTrq : 52|12@1+ (0.0625,-125) [-125|125.9375] "%" Vector__XXX

BO_ 2566595582 MG4IRP: 8 Vector__XXX
SG_ MtrGen4InvertLmtsRequestPowerCRC : 0|8@1+ (1,0) [0|255] "" Vector__XXX
SG_ MtrGen4InvertLmtsRequestPwrCntr : 8|4@1+ (1,0) [0|15] "" Vector__XXX
SG_ MtrGen4InvertLmtsRqMechnclPwrMax : 12|12@1+ (0.0625,-125) [-125|125.9375] "%" Vector__XXX
SG_ MtrGen4InvertLmtsRqMechnclPwrMin : 24|12@1+ (0.0625,-125) [-125|125.9375] "%" Vector__XXX
SG_ MtrGen4InvertLmtsRqDCSidePwrMax : 36|12@1+ (0.0625,-125) [-125|125.9375] "%" Vector__XXX
SG_ MtrGen4InvertLmtsRqDCSidePwrMin : 48|12@1+ (0.0625,-125) [-125|125.9375] "%" Vector__XXX

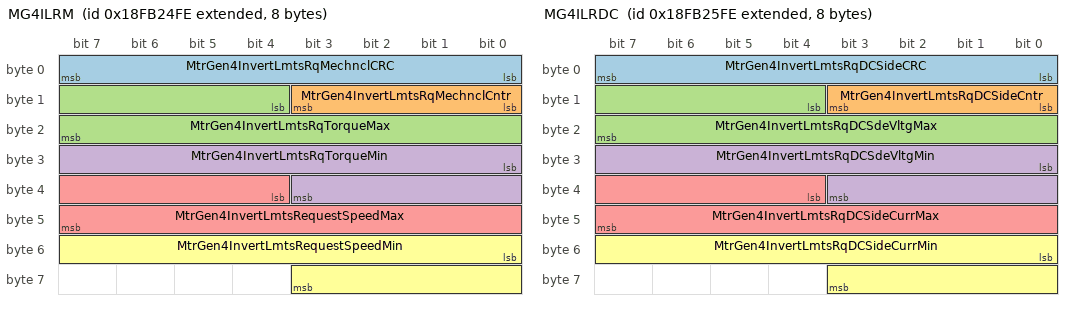
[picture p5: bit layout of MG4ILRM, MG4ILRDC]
BO_ 2566595838 MG4ILRM: 8 Vector__XXX
SG_ MtrGen4InvertLmtsRqMechnclCRC : 0|8@1+ (1,0) [0|255] "" Vector__XXX
SG_ MtrGen4InvertLmtsRqMechnclCntr : 8|4@1+ (1,0) [0|15] "" Vector__XXX
SG_ MtrGen4InvertLmtsRqTorqueMax : 12|12@1+ (0.0625,-125) [-125|125.9375] "%" Vector__XXX
SG_ MtrGen4InvertLmtsRqTorqueMin : 24|12@1+ (0.0625,-125) [-125|125.9375] "%" Vector__XXX
SG_ MtrGen4InvertLmtsRequestSpeedMax : 36|12@1+ (0.0625,-125) [-125|125.9375] "%" Vector__XXX
SG_ MtrGen4InvertLmtsRequestSpeedMin : 48|12@1+ (0.0625,-125) [-125|125.9375] "%" Vector__XXX

BO_ 2566596094 MG4ILRDC: 8 Vector__XXX
SG_ MtrGen4InvertLmtsRqDCSideCRC : 0|8@1+ (1,0) [0|255] "" Vector__XXX
SG_ MtrGen4InvertLmtsRqDCSideCntr : 8|4@1+ (1,0) [0|15] "" Vector__XXX
SG_ MtrGen4InvertLmtsRqDCSdeVltgMax : 12|12@1+ (0.0625,-125) [-125|125.9375] "%" Vector__XXX
SG_ MtrGen4InvertLmtsRqDCSdeVltgMin : 24|12@1+ (0.0625,-125) [-125|125.9375] "%" Vector__XXX
SG_ MtrGen4InvertLmtsRqDCSideCurrMax : 36|12@1+ (0.0625,-125) [-125|125.9375] "%" Vector__XXX
SG_ MtrGen4InvertLmtsRqDCSideCurrMin : 48|12@1+ (0.0625,-125) [-125|125.9375] "%" Vector__XXX

BO_ 2566596350 MG4IIR: 8 Vector__XXX
SG_ MtrGen4InvHiVBusActIsoltnTtCmd : 0|2@1+ (1,0) [0|3] "" Vector__XXX
SG_ MtrGen4InvHiVBusPassIsoltnTtCmd : 2|2@1+ (1,0) [0|3] "" Vector__XXX
SG_ MtrGen4InvHVBusHiSdeRsstrCnnctRq : 4|2@1+ (1,0) [0|3] "" Vector__XXX
SG_ MtrGen4InvHVBusLoSdeRsstrCnnctRq : 6|2@1+ (1,0) [0|3] "" Vector__XXX

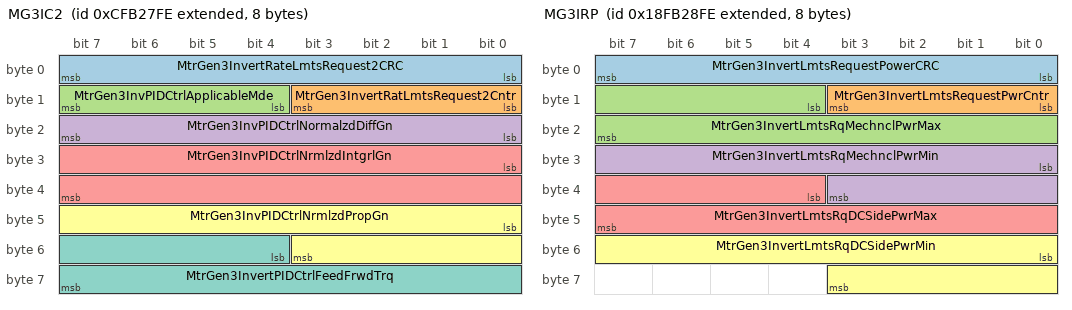
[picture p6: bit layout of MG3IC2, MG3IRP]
BO_ 2365270014 MG3IC2: 8 Vector__XXX
SG_ MtrGen3InvertRateLmtsRequest2CRC : 0|8@1+ (1,0) [0|255] "" Vector__XXX
SG_ MtrGen3InvertRatLmtsRequest2Cntr : 8|4@1+ (1,0) [0|15] "" Vector__XXX
SG_ MtrGen3InvPIDCtrlApplicableMde : 12|4@1+ (1,0) [0|15] "" Vector__XXX
SG_ MtrGen3InvPIDCtrlNormalzdDiffGn : 16|8@1+ (0.03125,0) [0|7.8125] "%/(%/s)" Vector__XXX
SG_ MtrGen3InvPIDCtrlNrmlzdIntgrlGn : 24|16@1+ (0.015625,0) [0|1003.984375] "%/(%*s)" Vector__XXX
SG_ MtrGen3InvPIDCtrlNrmlzdPropGn : 40|12@1+ (0.0625,0) [0|250.9375] "%/%" Vector__XXX
SG_ MtrGen3InvertPIDCtrlFeedFrwdTrq : 52|12@1+ (0.0625,-125) [-125|125.9375] "%" Vector__XXX

BO_ 2566596862 MG3IRP: 8 Vector__XXX
SG_ MtrGen3InvertLmtsRequestPowerCRC : 0|8@1+ (1,0) [0|255] "" Vector__XXX
SG_ MtrGen3InvertLmtsRequestPwrCntr : 8|4@1+ (1,0) [0|15] "" Vector__XXX
SG_ MtrGen3InvertLmtsRqMechnclPwrMax : 12|12@1+ (0.0625,-125) [-125|125.9375] "%" Vector__XXX
SG_ MtrGen3InvertLmtsRqMechnclPwrMin : 24|12@1+ (0.0625,-125) [-125|125.9375] "%" Vector__XXX
SG_ MtrGen3InvertLmtsRqDCSidePwrMax : 36|12@1+ (0.0625,-125) [-125|125.9375] "%" Vector__XXX
SG_ MtrGen3InvertLmtsRqDCSidePwrMin : 48|12@1+ (0.0625,-125) [-125|125.9375] "%" Vector__XXX

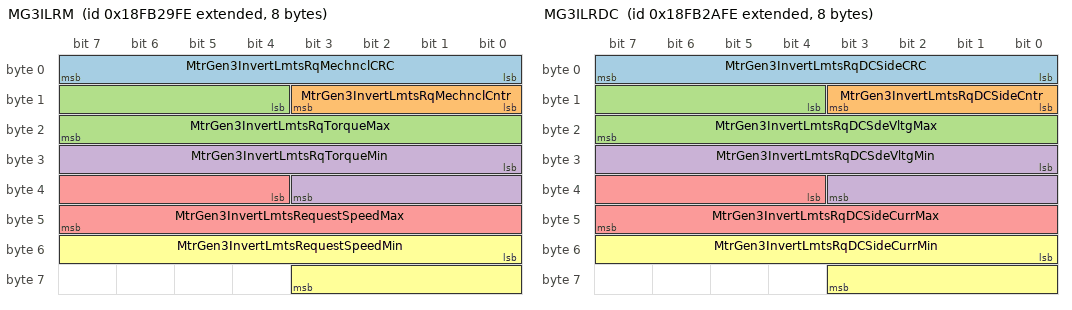
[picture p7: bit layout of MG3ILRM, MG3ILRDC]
BO_ 2566597118 MG3ILRM: 8 Vector__XXX
SG_ MtrGen3InvertLmtsRqMechnclCRC : 0|8@1+ (1,0) [0|255] "" Vector__XXX
SG_ MtrGen3InvertLmtsRqMechnclCntr : 8|4@1+ (1,0) [0|15] "" Vector__XXX
SG_ MtrGen3InvertLmtsRqTorqueMax : 12|12@1+ (0.0625,-125) [-125|125.9375] "%" Vector__XXX
SG_ MtrGen3InvertLmtsRqTorqueMin : 24|12@1+ (0.0625,-125) [-125|125.9375] "%" Vector__XXX
SG_ MtrGen3InvertLmtsRequestSpeedMax : 36|12@1+ (0.0625,-125) [-125|125.9375] "%" Vector__XXX
SG_ MtrGen3InvertLmtsRequestSpeedMin : 48|12@1+ (0.0625,-125) [-125|125.9375] "%" Vector__XXX

BO_ 2566597374 MG3ILRDC: 8 Vector__XXX
SG_ MtrGen3InvertLmtsRqDCSideCRC : 0|8@1+ (1,0) [0|255] "" Vector__XXX
SG_ MtrGen3InvertLmtsRqDCSideCntr : 8|4@1+ (1,0) [0|15] "" Vector__XXX
SG_ MtrGen3InvertLmtsRqDCSdeVltgMax : 12|12@1+ (0.0625,-125) [-125|125.9375] "%" Vector__XXX
SG_ MtrGen3InvertLmtsRqDCSdeVltgMin : 24|12@1+ (0.0625,-125) [-125|125.9375] "%" Vector__XXX
SG_ MtrGen3InvertLmtsRqDCSideCurrMax : 36|12@1+ (0.0625,-125) [-125|125.9375] "%" Vector__XXX
SG_ MtrGen3InvertLmtsRqDCSideCurrMin : 48|12@1+ (0.0625,-125) [-125|125.9375] "%" Vector__XXX

BO_ 2566597630 MG3IIR: 8 Vector__XXX
SG_ MtrGen3InvHiVBusActIsoltnTtCmd : 0|2@1+ (1,0) [0|3] "" Vector__XXX
SG_ MtrGen3InvHiVBusPassIsoltnTtCmd : 2|2@1+ (1,0) [0|3] "" Vector__XXX
SG_ MtrGen3InvHVBusHiSdeRsstrCnnctRq : 4|2@1+ (1,0) [0|3] "" Vector__XXX
SG_ MtrGen3InvHVBusLoSdeRsstrCnnctRq : 6|2@1+ (1,0) [0|3] "" Vector__XXX

BO_ 2566597886 DM59: 0 Vector__XXX

BO_ 2566598142 TCI8: 8 Vector__XXX
SG_ EngineTurbocharger5Speed : 0|16@1+ (4,0) [0|257020] "rpm" Vector__XXX
SG_ EngineTurbocharger6Speed : 16|16@1+ (4,0) [0|257020] "rpm" Vector__XXX
SG_ EngTurbo5CmprssorIntkPress : 32|16@1+ (0.0078125,-250) [-250|251.99] "kPa" Vector__XXX
SG_ EngTurbo6CmprssorIntkPress : 48|16@1+ (0.0078125,-250) [-250|251.99] "kPa" Vector__XXX

BO_ 2566598398 WINCH2: 8 Vector__XXX
SG_ WinchLifetimeRevolutionCounter : 0|32@1+ (1,0) [0|4211081215] "" Vector__XXX

BO_ 2365272062 MG6IR1: 8 Vector__XXX
SG_ MotorGen6InverterReference1CRC : 0|8@1+ (1,0) [0|255] "" Vector__XXX
SG_ MotorGen6InverterReference1Cntr : 8|4@1+ (1,0) [0|15] "" Vector__XXX
SG_ MotorGen6InverterReferenceTorque : 16|16@1+ (0.5,0) [0|32127.5] "Nm" Vector__XXX
SG_ MotorGen6InverterReferenceSpeed : 32|16@1+ (4,0) [0|257020] "rpm" Vector__XXX
SG_ MotorGen6InverterReferencePower : 48|16@1+ (0.0625,0) [0|4015.9375] "kW" Vector__XXX

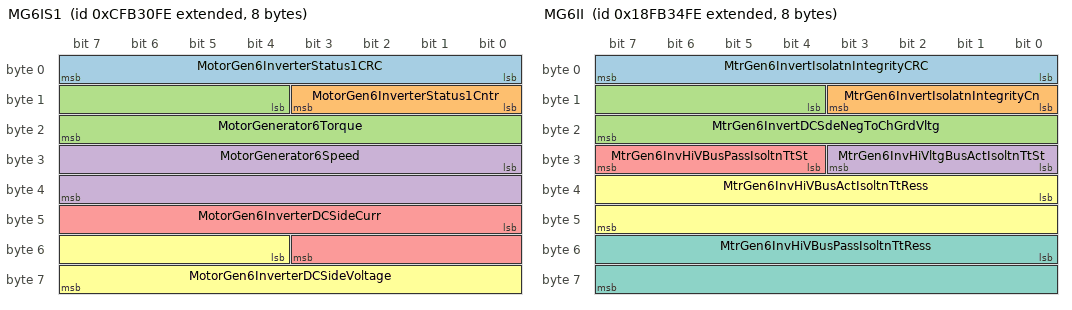
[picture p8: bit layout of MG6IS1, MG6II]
BO_ 2365272318 MG6IS1: 8 Vector__XXX
SG_ MotorGen6InverterStatus1CRC : 0|8@1+ (1,0) [0|255] "" Vector__XXX
SG_ MotorGen6InverterStatus1Cntr : 8|4@1+ (1,0) [0|15] "" Vector__XXX
SG_ MotorGenerator6Torque : 12|12@1+ (0.0625,-125) [-125|125.9375] "%" Vector__XXX
SG_ MotorGenerator6Speed : 24|16@1+ (0.00390625,-125) [-125|125.99609375] "%" Vector__XXX
SG_ MotorGen6InverterDCSideCurr : 40|12@1+ (0.0625,-125) [-125|125.9375] "%" Vector__XXX
SG_ MotorGen6InverterDCSideVoltage : 52|12@1+ (0.0625,-125) [-125|125.9375] "%" Vector__XXX

BO_ 2365272574 MG6IR2: 8 Vector__XXX
SG_ MotorGen6InverterReference2CRC : 0|8@1+ (1,0) [0|255] "" Vector__XXX
SG_ MotorGen6InverterReference2Cntr : 8|4@1+ (1,0) [0|15] "" Vector__XXX
SG_ MotorGen6InverterReferenceCurr : 32|16@1+ (0.125,0) [0|8031.875] "A" Vector__XXX
SG_ MotorGen6InvertReferenceVoltage : 48|16@1+ (0.125,0) [0|8031.875] "V" Vector__XXX

BO_ 2566599422 MG6IT: 8 Vector__XXX
SG_ MotorGen6InverterTemperature1 : 0|8@1+ (1,-40) [-40|210] "deg C" Vector__XXX
SG_ MotorGen6InverterTemperature2 : 8|8@1+ (1,-40) [-40|210] "deg C" Vector__XXX
SG_ MotorGen6InverterTemperature3 : 16|8@1+ (1,-40) [-40|210] "deg C" Vector__XXX
SG_ MotorGen6InverterTemperature4 : 24|8@1+ (1,-40) [-40|210] "deg C" Vector__XXX

BO_ 2566599678 MG6IMT: 8 Vector__XXX
SG_ MotorGenerator6Temperature1 : 0|8@1+ (1,-40) [-40|210] "deg C" Vector__XXX
SG_ MotorGenerator6Temperature2 : 8|8@1+ (1,-40) [-40|210] "deg C" Vector__XXX
SG_ MotorGenerator6Temperature3 : 16|8@1+ (1,-40) [-40|210] "deg C" Vector__XXX
SG_ MotorGenerator6Temperature4 : 24|8@1+ (1,-40) [-40|210] "deg C" Vector__XXX

BO_ 2566599934 MG6II: 8 Vector__XXX
SG_ MtrGen6InvertIsolatnIntegrityCRC : 0|8@1+ (1,0) [0|255] "" Vector__XXX
SG_ MtrGen6InvertIsolatnIntegrityCn : 8|4@1+ (1,0) [0|15] "" Vector__XXX
SG_ MtrGen6InvertDCSdeNegToChGrdVltg : 12|12@1+ (0.0625,-125) [-125|125.9375] "%" Vector__XXX
SG_ MtrGen6InvHiVltgBusActIsoltnTtSt : 24|4@1+ (1,0) [0|15] "" Vector__XXX
SG_ MtrGen6InvHiVBusPassIsoltnTtSt : 28|4@1+ (1,0) [0|15] "" Vector__XXX
SG_ MtrGen6InvHiVBusActIsoltnTtRess : 32|16@1+ (0.1,0) [0|6425.5] "ohm/V" Vector__XXX
SG_ MtrGen6InvHiVBusPassIsoltnTtRess : 48|16@1+ (0.1,0) [0|6425.5] "ohm/V" Vector__XXX

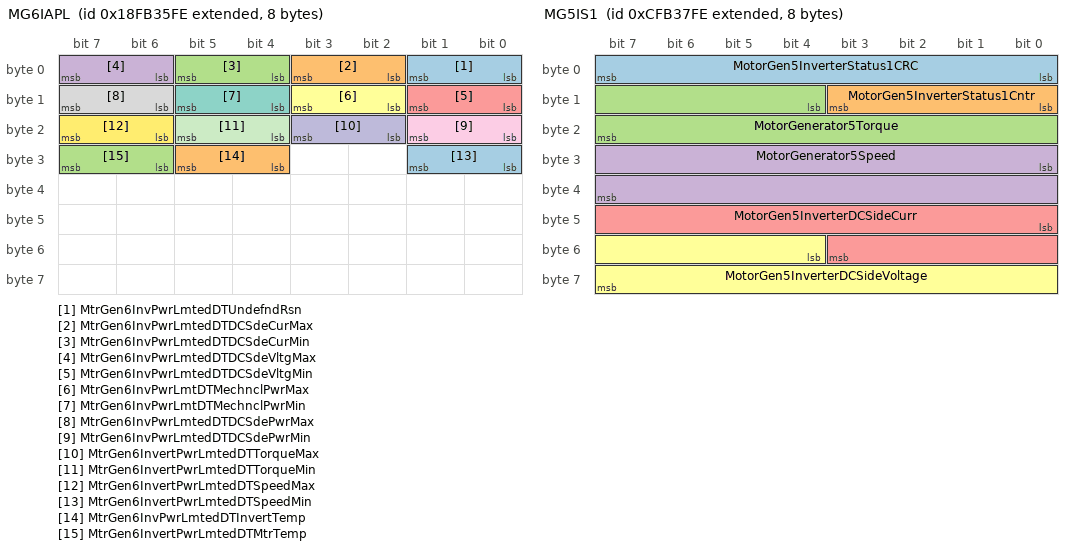
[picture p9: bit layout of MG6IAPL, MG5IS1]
BO_ 2566600190 MG6IAPL: 8 Vector__XXX
SG_ MtrGen6InvPwrLmtedDTUndefndRsn : 0|2@1+ (1,0) [0|3] "" Vector__XXX
SG_ MtrGen6InvPwrLmtedDTDCSdeCurMax : 2|2@1+ (1,0) [0|3] "" Vector__XXX
SG_ MtrGen6InvPwrLmtedDTDCSdeCurMin : 4|2@1+ (1,0) [0|3] "" Vector__XXX
SG_ MtrGen6InvPwrLmtedDTDCSdeVltgMax : 6|2@1+ (1,0) [0|3] "" Vector__XXX
SG_ MtrGen6InvPwrLmtedDTDCSdeVltgMin : 8|2@1+ (1,0) [0|3] "" Vector__XXX
SG_ MtrGen6InvPwrLmtDTMechnclPwrMax : 10|2@1+ (1,0) [0|3] "" Vector__XXX
SG_ MtrGen6InvPwrLmtDTMechnclPwrMin : 12|2@1+ (1,0) [0|3] "" Vector__XXX
SG_ MtrGen6InvPwrLmtedDTDCSdePwrMax : 14|2@1+ (1,0) [0|3] "" Vector__XXX
SG_ MtrGen6InvPwrLmtedDTDCSdePwrMin : 16|2@1+ (1,0) [0|3] "" Vector__XXX
SG_ MtrGen6InvertPwrLmtedDTTorqueMax : 18|2@1+ (1,0) [0|3] "" Vector__XXX
SG_ MtrGen6InvertPwrLmtedDTTorqueMin : 20|2@1+ (1,0) [0|3] "" Vector__XXX
SG_ MtrGen6InvertPwrLmtedDTSpeedMax : 22|2@1+ (1,0) [0|3] "" Vector__XXX
SG_ MtrGen6InvertPwrLmtedDTSpeedMin : 24|2@1+ (1,0) [0|3] "" Vector__XXX
SG_ MtrGen6InvPwrLmtedDTInvertTemp : 28|2@1+ (1,0) [0|3] "" Vector__XXX
SG_ MtrGen6InvertPwrLmtedDTMtrTemp : 30|2@1+ (1,0) [0|3] "" Vector__XXX

BO_ 2365273854 MG5IR1: 8 Vector__XXX
SG_ MotorGen5InverterReference1CRC : 0|8@1+ (1,0) [0|255] "" Vector__XXX
SG_ MotorGen5InverterReference1Cntr : 8|4@1+ (1,0) [0|15] "" Vector__XXX
SG_ MotorGen5InverterReferenceTorque : 16|16@1+ (0.5,0) [0|32127.5] "Nm" Vector__XXX
SG_ MotorGen5InverterReferenceSpeed : 32|16@1+ (4,0) [0|257020] "rpm" Vector__XXX
SG_ MotorGen5InverterReferencePower : 48|16@1+ (0.0625,0) [0|4015.9375] "kW" Vector__XXX

BO_ 2365274110 MG5IS1: 8 Vector__XXX
SG_ MotorGen5InverterStatus1CRC : 0|8@1+ (1,0) [0|255] "" Vector__XXX
SG_ MotorGen5InverterStatus1Cntr : 8|4@1+ (1,0) [0|15] "" Vector__XXX
SG_ MotorGenerator5Torque : 12|12@1+ (0.0625,-125) [-125|125.9375] "%" Vector__XXX
SG_ MotorGenerator5Speed : 24|16@1+ (0.00390625,-125) [-125|125.99609375] "%" Vector__XXX
SG_ MotorGen5InverterDCSideCurr : 40|12@1+ (0.0625,-125) [-125|125.9375] "%" Vector__XXX
SG_ MotorGen5InverterDCSideVoltage : 52|12@1+ (0.0625,-125) [-125|125.9375] "%" Vector__XXX

BO_ 2365274366 MG5IR2: 8 Vector__XXX
SG_ MotorGen5InverterReference2CRC : 0|8@1+ (1,0) [0|255] "" Vector__XXX
SG_ MotorGen5InverterReference2Cntr : 8|4@1+ (1,0) [0|15] "" Vector__XXX
SG_ MotorGen5InverterReferenceCurr : 32|16@1+ (0.125,0) [0|8031.875] "A" Vector__XXX
SG_ MotorGen5InvertReferenceVoltage : 48|16@1+ (0.125,0) [0|8031.875] "V" Vector__XXX

BO_ 2566601214 MG5IT: 8 Vector__XXX
SG_ MotorGen5InverterTemperature1 : 0|8@1+ (1,-40) [-40|210] "deg C" Vector__XXX
SG_ MotorGen5InverterTemperature2 : 8|8@1+ (1,-40) [-40|210] "deg C" Vector__XXX
SG_ MotorGen5InverterTemperature3 : 16|8@1+ (1,-40) [-40|210] "deg C" Vector__XXX
SG_ MotorGen5InverterTemperature4 : 24|8@1+ (1,-40) [-40|210] "deg C" Vector__XXX

BO_ 2566601470 MG5IMT: 8 Vector__XXX
SG_ MotorGenerator5Temperature1 : 0|8@1+ (1,-40) [-40|210] "deg C" Vector__XXX
SG_ MotorGenerator5Temperature2 : 8|8@1+ (1,-40) [-40|210] "deg C" Vector__XXX
SG_ MotorGenerator5Temperature3 : 16|8@1+ (1,-40) [-40|210] "deg C" Vector__XXX
SG_ MotorGenerator5Temperature4 : 24|8@1+ (1,-40) [-40|210] "deg C" Vector__XXX

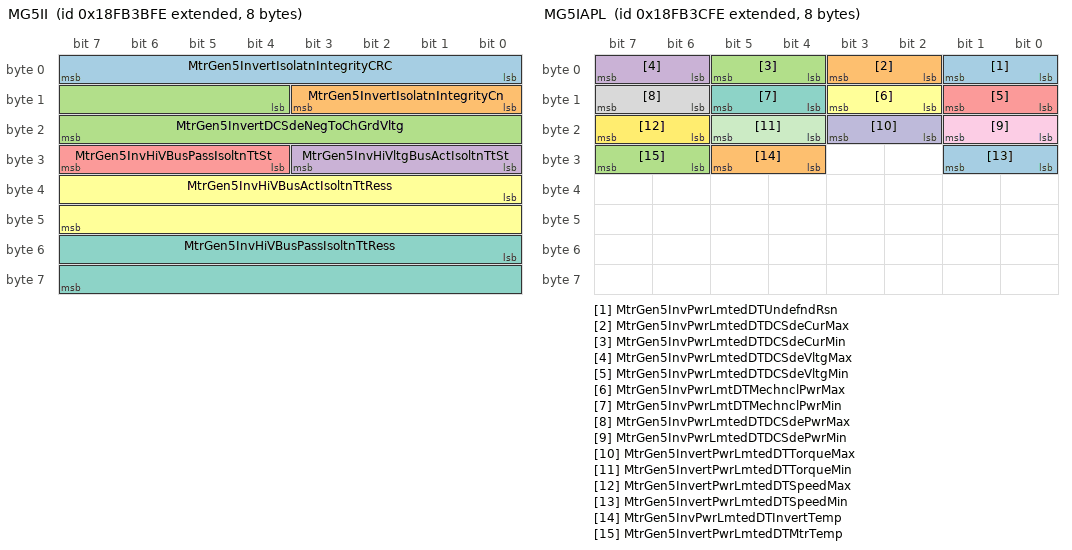
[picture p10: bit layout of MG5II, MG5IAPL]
BO_ 2566601726 MG5II: 8 Vector__XXX
SG_ MtrGen5InvertIsolatnIntegrityCRC : 0|8@1+ (1,0) [0|255] "" Vector__XXX
SG_ MtrGen5InvertIsolatnIntegrityCn : 8|4@1+ (1,0) [0|15] "" Vector__XXX
SG_ MtrGen5InvertDCSdeNegToChGrdVltg : 12|12@1+ (0.0625,-125) [-125|125.9375] "%" Vector__XXX
SG_ MtrGen5InvHiVltgBusActIsoltnTtSt : 24|4@1+ (1,0) [0|15] "" Vector__XXX
SG_ MtrGen5InvHiVBusPassIsoltnTtSt : 28|4@1+ (1,0) [0|15] "" Vector__XXX
SG_ MtrGen5InvHiVBusActIsoltnTtRess : 32|16@1+ (0.1,0) [0|6425.5] "ohm/V" Vector__XXX
SG_ MtrGen5InvHiVBusPassIsoltnTtRess : 48|16@1+ (0.1,0) [0|6425.5] "ohm/V" Vector__XXX

BO_ 2566601982 MG5IAPL: 8 Vector__XXX
SG_ MtrGen5InvPwrLmtedDTUndefndRsn : 0|2@1+ (1,0) [0|3] "" Vector__XXX
SG_ MtrGen5InvPwrLmtedDTDCSdeCurMax : 2|2@1+ (1,0) [0|3] "" Vector__XXX
SG_ MtrGen5InvPwrLmtedDTDCSdeCurMin : 4|2@1+ (1,0) [0|3] "" Vector__XXX
SG_ MtrGen5InvPwrLmtedDTDCSdeVltgMax : 6|2@1+ (1,0) [0|3] "" Vector__XXX
SG_ MtrGen5InvPwrLmtedDTDCSdeVltgMin : 8|2@1+ (1,0) [0|3] "" Vector__XXX
SG_ MtrGen5InvPwrLmtDTMechnclPwrMax : 10|2@1+ (1,0) [0|3] "" Vector__XXX
SG_ MtrGen5InvPwrLmtDTMechnclPwrMin : 12|2@1+ (1,0) [0|3] "" Vector__XXX
SG_ MtrGen5InvPwrLmtedDTDCSdePwrMax : 14|2@1+ (1,0) [0|3] "" Vector__XXX
SG_ MtrGen5InvPwrLmtedDTDCSdePwrMin : 16|2@1+ (1,0) [0|3] "" Vector__XXX
SG_ MtrGen5InvertPwrLmtedDTTorqueMax : 18|2@1+ (1,0) [0|3] "" Vector__XXX
SG_ MtrGen5InvertPwrLmtedDTTorqueMin : 20|2@1+ (1,0) [0|3] "" Vector__XXX
SG_ MtrGen5InvertPwrLmtedDTSpeedMax : 22|2@1+ (1,0) [0|3] "" Vector__XXX
SG_ MtrGen5InvertPwrLmtedDTSpeedMin : 24|2@1+ (1,0) [0|3] "" Vector__XXX
SG_ MtrGen5InvPwrLmtedDTInvertTemp : 28|2@1+ (1,0) [0|3] "" Vector__XXX
SG_ MtrGen5InvertPwrLmtedDTMtrTemp : 30|2@1+ (1,0) [0|3] "" Vector__XXX

BO_ 2365275646 MG4IR1: 8 Vector__XXX
SG_ MotorGen4InverterReference1CRC : 0|8@1+ (1,0) [0|255] "" Vector__XXX
SG_ MotorGen4InverterReference1Cntr : 8|4@1+ (1,0) [0|15] "" Vector__XXX
SG_ MotorGen4InverterReferenceTorque : 16|16@1+ (0.5,0) [0|32127.5] "Nm" Vector__XXX
SG_ MotorGen4InverterReferenceSpeed : 32|16@1+ (4,0) [0|257020] "rpm" Vector__XXX
SG_ MotorGen4InverterReferencePower : 48|16@1+ (0.0625,0) [0|4015.9375] "kW" Vector__XXX

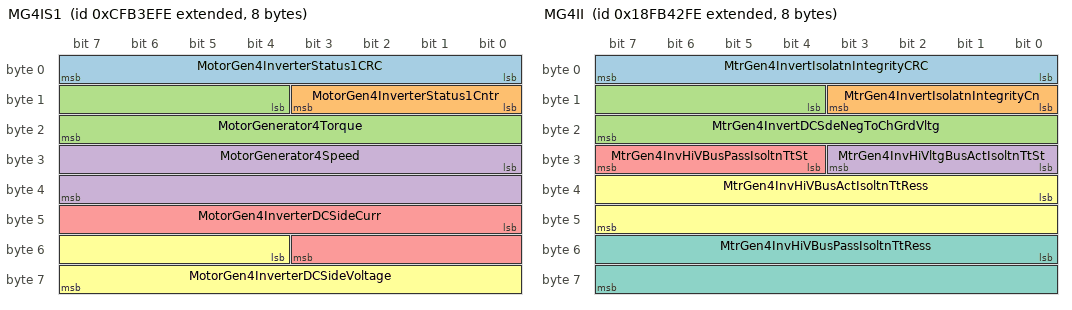
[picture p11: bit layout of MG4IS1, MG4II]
BO_ 2365275902 MG4IS1: 8 Vector__XXX
SG_ MotorGen4InverterStatus1CRC : 0|8@1+ (1,0) [0|255] "" Vector__XXX
SG_ MotorGen4InverterStatus1Cntr : 8|4@1+ (1,0) [0|15] "" Vector__XXX
SG_ MotorGenerator4Torque : 12|12@1+ (0.0625,-125) [-125|125.9375] "%" Vector__XXX
SG_ MotorGenerator4Speed : 24|16@1+ (0.00390625,-125) [-125|125.99609375] "%" Vector__XXX
SG_ MotorGen4InverterDCSideCurr : 40|12@1+ (0.0625,-125) [-125|125.9375] "%" Vector__XXX
SG_ MotorGen4InverterDCSideVoltage : 52|12@1+ (0.0625,-125) [-125|125.9375] "%" Vector__XXX

BO_ 2365276158 MG4IR2: 8 Vector__XXX
SG_ MotorGen4InverterReference2CRC : 0|8@1+ (1,0) [0|255] "" Vector__XXX
SG_ MotorGen4InverterReference2Cntr : 8|4@1+ (1,0) [0|15] "" Vector__XXX
SG_ MotorGen4InverterReferenceCurr : 32|16@1+ (0.125,0) [0|8031.875] "A" Vector__XXX
SG_ MotorGen4InvertReferenceVoltage : 48|16@1+ (0.125,0) [0|8031.875] "V" Vector__XXX

BO_ 2566603006 MG4IT: 8 Vector__XXX
SG_ MotorGen4InverterTemperature1 : 0|8@1+ (1,-40) [-40|210] "deg C" Vector__XXX
SG_ MotorGen4InverterTemperature2 : 8|8@1+ (1,-40) [-40|210] "deg C" Vector__XXX
SG_ MotorGen4InverterTemperature3 : 16|8@1+ (1,-40) [-40|210] "deg C" Vector__XXX
SG_ MotorGen4InverterTemperature4 : 24|8@1+ (1,-40) [-40|210] "deg C" Vector__XXX

BO_ 2566603262 MG4IMT: 8 Vector__XXX
SG_ MotorGenerator4Temperature1 : 0|8@1+ (1,-40) [-40|210] "deg C" Vector__XXX
SG_ MotorGenerator4Temperature2 : 8|8@1+ (1,-40) [-40|210] "deg C" Vector__XXX
SG_ MotorGenerator4Temperature3 : 16|8@1+ (1,-40) [-40|210] "deg C" Vector__XXX
SG_ MotorGenerator4Temperature4 : 24|8@1+ (1,-40) [-40|210] "deg C" Vector__XXX

BO_ 2566603518 MG4II: 8 Vector__XXX
SG_ MtrGen4InvertIsolatnIntegrityCRC : 0|8@1+ (1,0) [0|255] "" Vector__XXX
SG_ MtrGen4InvertIsolatnIntegrityCn : 8|4@1+ (1,0) [0|15] "" Vector__XXX
SG_ MtrGen4InvertDCSdeNegToChGrdVltg : 12|12@1+ (0.0625,-125) [-125|125.9375] "%" Vector__XXX
SG_ MtrGen4InvHiVltgBusActIsoltnTtSt : 24|4@1+ (1,0) [0|15] "" Vector__XXX
SG_ MtrGen4InvHiVBusPassIsoltnTtSt : 28|4@1+ (1,0) [0|15] "" Vector__XXX
SG_ MtrGen4InvHiVBusActIsoltnTtRess : 32|16@1+ (0.1,0) [0|6425.5] "ohm/V" Vector__XXX
SG_ MtrGen4InvHiVBusPassIsoltnTtRess : 48|16@1+ (0.1,0) [0|6425.5] "ohm/V" Vector__XXX

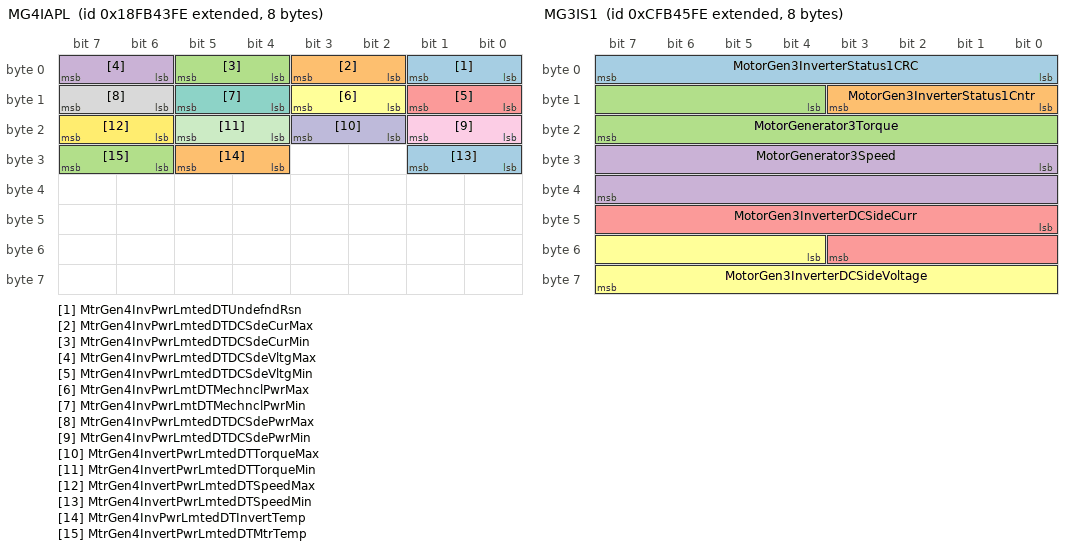
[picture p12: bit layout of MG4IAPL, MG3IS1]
BO_ 2566603774 MG4IAPL: 8 Vector__XXX
SG_ MtrGen4InvPwrLmtedDTUndefndRsn : 0|2@1+ (1,0) [0|3] "" Vector__XXX
SG_ MtrGen4InvPwrLmtedDTDCSdeCurMax : 2|2@1+ (1,0) [0|3] "" Vector__XXX
SG_ MtrGen4InvPwrLmtedDTDCSdeCurMin : 4|2@1+ (1,0) [0|3] "" Vector__XXX
SG_ MtrGen4InvPwrLmtedDTDCSdeVltgMax : 6|2@1+ (1,0) [0|3] "" Vector__XXX
SG_ MtrGen4InvPwrLmtedDTDCSdeVltgMin : 8|2@1+ (1,0) [0|3] "" Vector__XXX
SG_ MtrGen4InvPwrLmtDTMechnclPwrMax : 10|2@1+ (1,0) [0|3] "" Vector__XXX
SG_ MtrGen4InvPwrLmtDTMechnclPwrMin : 12|2@1+ (1,0) [0|3] "" Vector__XXX
SG_ MtrGen4InvPwrLmtedDTDCSdePwrMax : 14|2@1+ (1,0) [0|3] "" Vector__XXX
SG_ MtrGen4InvPwrLmtedDTDCSdePwrMin : 16|2@1+ (1,0) [0|3] "" Vector__XXX
SG_ MtrGen4InvertPwrLmtedDTTorqueMax : 18|2@1+ (1,0) [0|3] "" Vector__XXX
SG_ MtrGen4InvertPwrLmtedDTTorqueMin : 20|2@1+ (1,0) [0|3] "" Vector__XXX
SG_ MtrGen4InvertPwrLmtedDTSpeedMax : 22|2@1+ (1,0) [0|3] "" Vector__XXX
SG_ MtrGen4InvertPwrLmtedDTSpeedMin : 24|2@1+ (1,0) [0|3] "" Vector__XXX
SG_ MtrGen4InvPwrLmtedDTInvertTemp : 28|2@1+ (1,0) [0|3] "" Vector__XXX
SG_ MtrGen4InvertPwrLmtedDTMtrTemp : 30|2@1+ (1,0) [0|3] "" Vector__XXX

BO_ 2365277438 MG3IR1: 8 Vector__XXX
SG_ MotorGen3InverterReference1CRC : 0|8@1+ (1,0) [0|255] "" Vector__XXX
SG_ MotorGen3InverterReference1Cntr : 8|4@1+ (1,0) [0|15] "" Vector__XXX
SG_ MotorGen3InverterReferenceTorque : 16|16@1+ (0.5,0) [0|32127.5] "Nm" Vector__XXX
SG_ MotorGen3InverterReferenceSpeed : 32|16@1+ (4,0) [0|257020] "rpm" Vector__XXX
SG_ MotorGen3InverterReferencePower : 48|16@1+ (0.0625,0) [0|4015.9375] "kW" Vector__XXX

BO_ 2365277694 MG3IS1: 8 Vector__XXX
SG_ MotorGen3InverterStatus1CRC : 0|8@1+ (1,0) [0|255] "" Vector__XXX
SG_ MotorGen3InverterStatus1Cntr : 8|4@1+ (1,0) [0|15] "" Vector__XXX
SG_ MotorGenerator3Torque : 12|12@1+ (0.0625,-125) [-125|125.9375] "%" Vector__XXX
SG_ MotorGenerator3Speed : 24|16@1+ (0.00390625,-125) [-125|125.99609375] "%" Vector__XXX
SG_ MotorGen3InverterDCSideCurr : 40|12@1+ (0.0625,-125) [-125|125.9375] "%" Vector__XXX
SG_ MotorGen3InverterDCSideVoltage : 52|12@1+ (0.0625,-125) [-125|125.9375] "%" Vector__XXX

BO_ 2365277950 MG3IR2: 8 Vector__XXX
SG_ MotorGen3InverterReference2CRC : 0|8@1+ (1,0) [0|255] "" Vector__XXX
SG_ MotorGen3InverterReference2Cntr : 8|4@1+ (1,0) [0|15] "" Vector__XXX
SG_ MotorGen3InverterReferenceCurr : 32|16@1+ (0.125,0) [0|8031.875] "A" Vector__XXX
SG_ MotorGen3InvertReferenceVoltage : 48|16@1+ (0.125,0) [0|8031.875] "V" Vector__XXX

BO_ 2566604798 MG3IT: 8 Vector__XXX
SG_ MotorGen3InverterTemperature1 : 0|8@1+ (1,-40) [-40|210] "deg C" Vector__XXX
SG_ MotorGen3InverterTemperature2 : 8|8@1+ (1,-40) [-40|210] "deg C" Vector__XXX
SG_ MotorGen3InverterTemperature3 : 16|8@1+ (1,-40) [-40|210] "deg C" Vector__XXX
SG_ MotorGen3InverterTemperature4 : 24|8@1+ (1,-40) [-40|210] "deg C" Vector__XXX

BO_ 2566605054 MG3IMT: 8 Vector__XXX
SG_ MotorGenerator3Temperature1 : 0|8@1+ (1,-40) [-40|210] "deg C" Vector__XXX
SG_ MotorGenerator3Temperature2 : 8|8@1+ (1,-40) [-40|210] "deg C" Vector__XXX
SG_ MotorGenerator3Temperature3 : 16|8@1+ (1,-40) [-40|210] "deg C" Vector__XXX
SG_ MotorGenerator3Temperature4 : 24|8@1+ (1,-40) [-40|210] "deg C" Vector__XXX

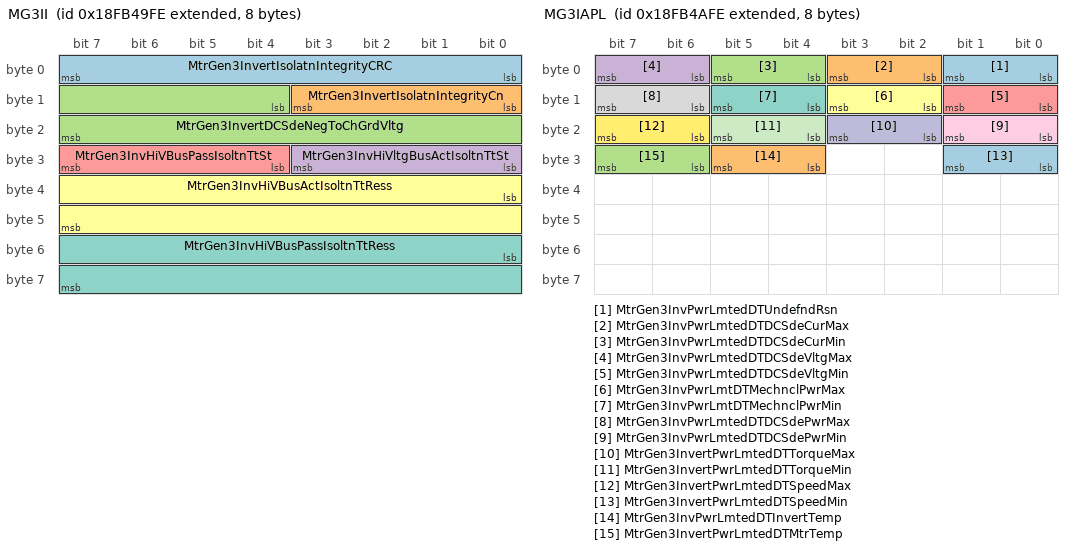
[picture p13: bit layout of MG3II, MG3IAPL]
BO_ 2566605310 MG3II: 8 Vector__XXX
SG_ MtrGen3InvertIsolatnIntegrityCRC : 0|8@1+ (1,0) [0|255] "" Vector__XXX
SG_ MtrGen3InvertIsolatnIntegrityCn : 8|4@1+ (1,0) [0|15] "" Vector__XXX
SG_ MtrGen3InvertDCSdeNegToChGrdVltg : 12|12@1+ (0.0625,-125) [-125|125.9375] "%" Vector__XXX
SG_ MtrGen3InvHiVltgBusActIsoltnTtSt : 24|4@1+ (1,0) [0|15] "" Vector__XXX
SG_ MtrGen3InvHiVBusPassIsoltnTtSt : 28|4@1+ (1,0) [0|15] "" Vector__XXX
SG_ MtrGen3InvHiVBusActIsoltnTtRess : 32|16@1+ (0.1,0) [0|6425.5] "ohm/V" Vector__XXX
SG_ MtrGen3InvHiVBusPassIsoltnTtRess : 48|16@1+ (0.1,0) [0|6425.5] "ohm/V" Vector__XXX

BO_ 2566605566 MG3IAPL: 8 Vector__XXX
SG_ MtrGen3InvPwrLmtedDTUndefndRsn : 0|2@1+ (1,0) [0|3] "" Vector__XXX
SG_ MtrGen3InvPwrLmtedDTDCSdeCurMax : 2|2@1+ (1,0) [0|3] "" Vector__XXX
SG_ MtrGen3InvPwrLmtedDTDCSdeCurMin : 4|2@1+ (1,0) [0|3] "" Vector__XXX
SG_ MtrGen3InvPwrLmtedDTDCSdeVltgMax : 6|2@1+ (1,0) [0|3] "" Vector__XXX
SG_ MtrGen3InvPwrLmtedDTDCSdeVltgMin : 8|2@1+ (1,0) [0|3] "" Vector__XXX
SG_ MtrGen3InvPwrLmtDTMechnclPwrMax : 10|2@1+ (1,0) [0|3] "" Vector__XXX
SG_ MtrGen3InvPwrLmtDTMechnclPwrMin : 12|2@1+ (1,0) [0|3] "" Vector__XXX
SG_ MtrGen3InvPwrLmtedDTDCSdePwrMax : 14|2@1+ (1,0) [0|3] "" Vector__XXX
SG_ MtrGen3InvPwrLmtedDTDCSdePwrMin : 16|2@1+ (1,0) [0|3] "" Vector__XXX
SG_ MtrGen3InvertPwrLmtedDTTorqueMax : 18|2@1+ (1,0) [0|3] "" Vector__XXX
SG_ MtrGen3InvertPwrLmtedDTTorqueMin : 20|2@1+ (1,0) [0|3] "" Vector__XXX
SG_ MtrGen3InvertPwrLmtedDTSpeedMax : 22|2@1+ (1,0) [0|3] "" Vector__XXX
SG_ MtrGen3InvertPwrLmtedDTSpeedMin : 24|2@1+ (1,0) [0|3] "" Vector__XXX
SG_ MtrGen3InvPwrLmtedDTInvertTemp : 28|2@1+ (1,0) [0|3] "" Vector__XXX
SG_ MtrGen3InvertPwrLmtedDTMtrTemp : 30|2@1+ (1,0) [0|3] "" Vector__XXX

BO_ 2566605822 ADSF: 8 Vector__XXX
SG_ SrcAddrCtlngDevTSC1CtrlPurposeP7 : 0|8@1+ (1,0) [0|255] "" Vector__XXX
SG_ TSC1CtrlPurposeP7ReadinessStatus : 8|2@1+ (1,0) [0|3] "" Vector__XXX

BO_ 2566606078 CCSI2: 8 Vector__XXX
SG_ CabHeaterPower : 0|16@1+ (2,0) [0|128510] "W" Vector__XXX

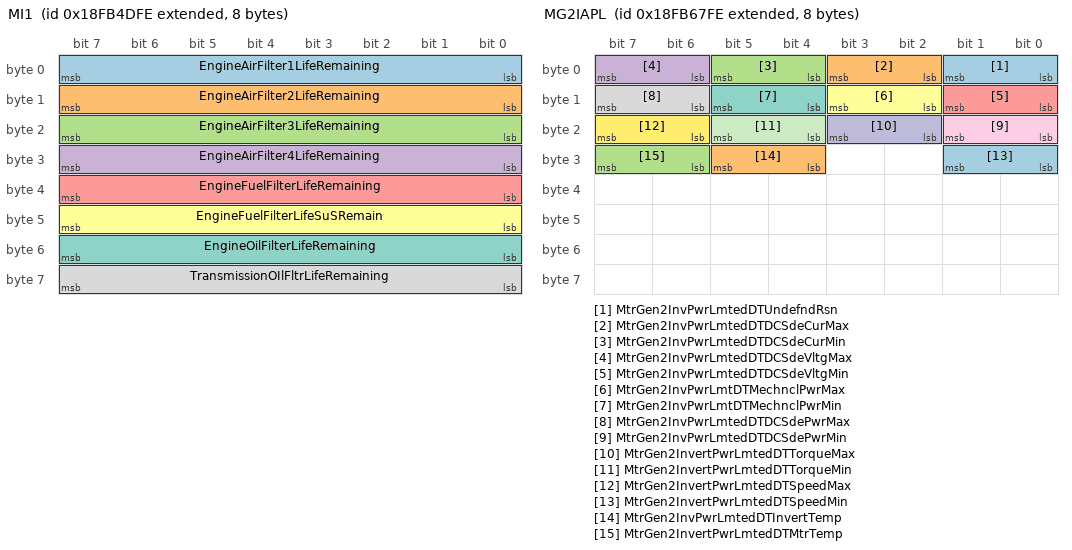
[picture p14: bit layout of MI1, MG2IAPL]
BO_ 2566606334 MI1: 8 Vector__XXX
SG_ EngineAirFilter1LifeRemaining : 0|8@1+ (0.4,0) [0|100] "%" Vector__XXX
SG_ EngineAirFilter2LifeRemaining : 8|8@1+ (0.4,0) [0|100] "%" Vector__XXX
SG_ EngineAirFilter3LifeRemaining : 16|8@1+ (0.4,0) [0|100] "%" Vector__XXX
SG_ EngineAirFilter4LifeRemaining : 24|8@1+ (0.4,0) [0|100] "%" Vector__XXX
SG_ EngineFuelFilterLifeRemaining : 32|8@1+ (0.4,0) [0|100] "%" Vector__XXX
SG_ EngineFuelFilterLifeSuSRemain : 40|8@1+ (0.4,0) [0|100] "%" Vector__XXX
SG_ EngineOilFilterLifeRemaining : 48|8@1+ (0.4,0) [0|100] "%" Vector__XXX
SG_ TransmissionOIlFltrLifeRemaining : 56|8@1+ (0.4,0) [0|100] "%" Vector__XXX

BO_ 2499497726 HCI1: 8 Vector__XXX
SG_ HoistLeverPosition : 0|16@1+ (0.005,-150) [-150|171.275] "%" Vector__XXX
SG_ HoistLeverDetentPositionStatus : 16|2@1+ (1,0) [0|3] "" Vector__XXX

BO_ 2633715710 HVESP6HIST: 11 Vector__XXX
SG_ HVESP6StateOfHealth : 0|8@1+ (0.4,0) [0|100] "%" Vector__XXX
SG_ HVESP6ContactorOpenUnderLoadCnt : 8|16@1+ (1,0) [0|64255] "" Vector__XXX
SG_ HVESP6TotalEnergyThroughput : 24|32@1+ (100,0) [0|421108121500] "Watt-hour" Vector__XXX
SG_ HVESP6TotalAccumulatedCharge : 56|32@1+ (100,0) [0|421108121500] "Ah" Vector__XXX

BO_ 2566607102 HVESP6CFG: 16 Vector__XXX
SG_ HVESP6NominalVoltage : 0|16@1+ (0.05,0) [0|3212.75] "V" Vector__XXX
SG_ HVESP6RecmmndedMinOprtngVoltage : 16|16@1+ (0.05,0) [0|3212.75] "V" Vector__XXX
SG_ HVESP6RecmmndedMaxOprtngVoltage : 32|16@1+ (0.05,0) [0|3212.75] "V" Vector__XXX
SG_ HVESP6RecommendedMinStateChrg : 48|16@1+ (0.0015625,0) [0|100.3984375] "%" Vector__XXX
SG_ HVESP6RecommendedMaxStateChrg : 64|16@1+ (0.0015625,0) [0|100.3984375] "%" Vector__XXX
SG_ HVESP6RecmmndedMaxOprtngTemp : 80|16@1+ (0.03125,-273) [-273|1734.96875] "deg C" Vector__XXX
SG_ HVESP6RecmmndedMinOprtngTemp : 96|16@1+ (0.03125,-273) [-273|1734.96875] "deg C" Vector__XXX
SG_ HVESP6CellMaximumVoltageLimit : 112|8@1+ (0.02044,0) [0|5.11] "V" Vector__XXX
SG_ HVESP6CellMinimumVoltageLimit : 120|8@1+ (0.02044,0) [0|5.11] "V" Vector__XXX

BO_ 2633716222 HVESP5HIST: 11 Vector__XXX
SG_ HVESP5StateOfHealth : 0|8@1+ (0.4,0) [0|100] "%" Vector__XXX
SG_ HVESP5ContactorOpenUnderLoadCnt : 8|16@1+ (1,0) [0|64255] "" Vector__XXX
SG_ HVESP5TotalEnergyThroughput : 24|32@1+ (100,0) [0|421108121500] "Watt-hour" Vector__XXX
SG_ HVESP5TotalAccumulatedCharge : 56|32@1+ (100,0) [0|421108121500] "Ah" Vector__XXX

BO_ 2566607614 HVESP5CFG: 16 Vector__XXX
SG_ HVESP5NominalVoltage : 0|16@1+ (0.05,0) [0|3212.75] "V" Vector__XXX
SG_ HVESP5RecmmndedMinOprtngVoltage : 16|16@1+ (0.05,0) [0|3212.75] "V" Vector__XXX
SG_ HVESP5RecmmndedMaxOprtngVoltage : 32|16@1+ (0.05,0) [0|3212.75] "V" Vector__XXX
SG_ HVESP5RecommendedMinStateChrg : 48|16@1+ (0.0015625,0) [0|100.3984375] "%" Vector__XXX
SG_ HVESP5RecommendedMaxStateChrg : 64|16@1+ (0.0015625,0) [0|100.3984375] "%" Vector__XXX
SG_ HVESP5RecmmndedMaxOprtngTemp : 80|16@1+ (0.03125,-273) [-273|1734.96875] "deg C" Vector__XXX
SG_ HVESP5RecmmndedMinOprtngTemp : 96|16@1+ (0.03125,-273) [-273|1734.96875] "deg C" Vector__XXX
SG_ HVESP5CellMaximumVoltageLimit : 112|8@1+ (0.02044,0) [0|5.11] "V" Vector__XXX
SG_ HVESP5CellMinimumVoltageLimit : 120|8@1+ (0.02044,0) [0|5.11] "V" Vector__XXX

BO_ 2633716734 HVESP4HIST: 11 Vector__XXX
SG_ HVESP4StateOfHealth : 0|8@1+ (0.4,0) [0|100] "%" Vector__XXX
SG_ HVESP4ContactorOpenUnderLoadCnt : 8|16@1+ (1,0) [0|64255] "" Vector__XXX
SG_ HVESP4TotalEnergyThroughput : 24|32@1+ (100,0) [0|421108121500] "Watt-hour" Vector__XXX
SG_ HVESP4TotalAccumulatedCharge : 56|32@1+ (100,0) [0|421108121500] "Ah" Vector__XXX

BO_ 2566608126 HVESP4CFG: 16 Vector__XXX
SG_ HVESP4NominalVoltage : 0|16@1+ (0.05,0) [0|3212.75] "V" Vector__XXX
SG_ HVESP4RecmmndedMinOprtngVoltage : 16|16@1+ (0.05,0) [0|3212.75] "V" Vector__XXX
SG_ HVESP4RecmmndedMaxOprtngVoltage : 32|16@1+ (0.05,0) [0|3212.75] "V" Vector__XXX
SG_ HVESP4RecommendedMinStateChrg : 48|16@1+ (0.0015625,0) [0|100.3984375] "%" Vector__XXX
SG_ HVESP4RecommendedMaxStateChrg : 64|16@1+ (0.0015625,0) [0|100.3984375] "%" Vector__XXX
SG_ HVESP4RecmmndedMaxOprtngTemp : 80|16@1+ (0.03125,-273) [-273|1734.96875] "deg C" Vector__XXX
SG_ HVESP4RecmmndedMinOprtngTemp : 96|16@1+ (0.03125,-273) [-273|1734.96875] "deg C" Vector__XXX
SG_ HVESP4CellMaximumVoltageLimit : 112|8@1+ (0.02044,0) [0|5.11] "V" Vector__XXX
SG_ HVESP4CellMinimumVoltageLimit : 120|8@1+ (0.02044,0) [0|5.11] "V" Vector__XXX

BO_ 2633717246 HVESP3HIST: 11 Vector__XXX
SG_ HVESP3StateOfHealth : 0|8@1+ (0.4,0) [0|100] "%" Vector__XXX
SG_ HVESP3ContactorOpenUnderLoadCnt : 8|16@1+ (1,0) [0|64255] "" Vector__XXX
SG_ HVESP3TotalEnergyThroughput : 24|32@1+ (100,0) [0|421108121500] "Watt-hour" Vector__XXX
SG_ HVESP3TotalAccumulatedCharge : 56|32@1+ (100,0) [0|421108121500] "Ah" Vector__XXX

BO_ 2566608638 HVESP3CFG: 16 Vector__XXX
SG_ HVESP3NominalVoltage : 0|16@1+ (0.05,0) [0|3212.75] "V" Vector__XXX
SG_ HVESP3RecmmndedMinOprtngVoltage : 16|16@1+ (0.05,0) [0|3212.75] "V" Vector__XXX
SG_ HVESP3RecmmndedMaxOprtngVoltage : 32|16@1+ (0.05,0) [0|3212.75] "V" Vector__XXX
SG_ HVESP3RecommendedMinStateChrg : 48|16@1+ (0.0015625,0) [0|100.3984375] "%" Vector__XXX
SG_ HVESP3RecommendedMaxStateChrg : 64|16@1+ (0.0015625,0) [0|100.3984375] "%" Vector__XXX
SG_ HVESP3RecmmndedMaxOprtngTemp : 80|16@1+ (0.03125,-273) [-273|1734.96875] "deg C" Vector__XXX
SG_ HVESP3RecmmndedMinOprtngTemp : 96|16@1+ (0.03125,-273) [-273|1734.96875] "deg C" Vector__XXX
SG_ HVESP3CellMaximumVoltageLimit : 112|8@1+ (0.02044,0) [0|5.11] "V" Vector__XXX
SG_ HVESP3CellMinimumVoltageLimit : 120|8@1+ (0.02044,0) [0|5.11] "V" Vector__XXX

BO_ 2633717758 HVESP2HIST: 11 Vector__XXX
SG_ HVESP2StateOfHealth : 0|8@1+ (0.4,0) [0|100] "%" Vector__XXX
SG_ HVESP2ContactorOpenUnderLoadCnt : 8|16@1+ (1,0) [0|64255] "" Vector__XXX
SG_ HVESP2TotalEnergyThroughput : 24|32@1+ (100,0) [0|421108121500] "Watt-hour" Vector__XXX
SG_ HVESP2TotalAccumulatedCharge : 56|32@1+ (100,0) [0|421108121500] "Ah" Vector__XXX

BO_ 2566609150 HVESP2CFG: 16 Vector__XXX
SG_ HVESP2NominalVoltage : 0|16@1+ (0.05,0) [0|3212.75] "V" Vector__XXX
SG_ HVESP2RecmmndedMinOprtngVoltage : 16|16@1+ (0.05,0) [0|3212.75] "V" Vector__XXX
SG_ HVESP2RecmmndedMaxOprtngVoltage : 32|16@1+ (0.05,0) [0|3212.75] "V" Vector__XXX
SG_ HVESP2RecommendedMinStateChrg : 48|16@1+ (0.0015625,0) [0|100.3984375] "%" Vector__XXX
SG_ HVESP2RecommendedMaxStateChrg : 64|16@1+ (0.0015625,0) [0|100.3984375] "%" Vector__XXX
SG_ HVESP2RecmmndedMaxOprtngTemp : 80|16@1+ (0.03125,-273) [-273|1734.96875] "deg C" Vector__XXX
SG_ HVESP2RecmmndedMinOprtngTemp : 96|16@1+ (0.03125,-273) [-273|1734.96875] "deg C" Vector__XXX
SG_ HVESP2CellMaximumVoltageLimit : 112|8@1+ (0.02044,0) [0|5.11] "V" Vector__XXX
SG_ HVESP2CellMinimumVoltageLimit : 120|8@1+ (0.02044,0) [0|5.11] "V" Vector__XXX

BO_ 2633718270 HVESP1HIST: 11 Vector__XXX
SG_ HVESP1StateOfHealth : 0|8@1+ (0.4,0) [0|100] "%" Vector__XXX
SG_ HVESP1ContactorOpenUnderLoadCnt : 8|16@1+ (1,0) [0|64255] "" Vector__XXX
SG_ HVESP1TotalEnergyThroughput : 24|32@1+ (100,0) [0|421108121500] "Watt-hour" Vector__XXX
SG_ HVESP1TotalAccumulatedCharge : 56|32@1+ (100,0) [0|421108121500] "Ah" Vector__XXX

BO_ 2566609662 HVESP1CFG: 16 Vector__XXX
SG_ HVESP1NominalVoltage : 0|16@1+ (0.05,0) [0|3212.75] "V" Vector__XXX
SG_ HVESP1RecmmndedMinOprtngVoltage : 16|16@1+ (0.05,0) [0|3212.75] "V" Vector__XXX
SG_ HVESP1RecmmndedMaxOprtngVoltage : 32|16@1+ (0.05,0) [0|3212.75] "V" Vector__XXX
SG_ HVESP1RecommendedMinStateChrg : 48|16@1+ (0.0015625,0) [0|100.3984375] "%" Vector__XXX
SG_ HVESP1RecommendedMaxStateChrg : 64|16@1+ (0.0015625,0) [0|100.3984375] "%" Vector__XXX
SG_ HVESP1RecmmndedMaxOprtngTemp : 80|16@1+ (0.03125,-273) [-273|1734.96875] "deg C" Vector__XXX
SG_ HVESP1RecmmndedMinOprtngTemp : 96|16@1+ (0.03125,-273) [-273|1734.96875] "deg C" Vector__XXX
SG_ HVESP1CellMaximumVoltageLimit : 112|8@1+ (0.02044,0) [0|5.11] "V" Vector__XXX
SG_ HVESP1CellMinimumVoltageLimit : 120|8@1+ (0.02044,0) [0|5.11] "V" Vector__XXX

BO_ 2633718782 VFSSM1DET: 24 Vector__XXX
SG_ VFSSModule1Detector1DetectorType : 0|4@1+ (1,0) [0|15] "" Vector__XXX
SG_ VFSSModule1Detctr1DetctrDatSLOT : 4|4@1+ (1,0) [0|15] "" Vector__XXX
SG_ VFSSModule1Detector1Data : 8|16@1+ (1,0) [0|65535] "" Vector__XXX
SG_ VFSSModule1Detector2DetectorType : 24|4@1+ (1,0) [0|15] "" Vector__XXX
SG_ VFSSModule1Detctr2DetctrDatSLOT : 28|4@1+ (1,0) [0|15] "" Vector__XXX
SG_ VFSSModule1Detector2Data : 32|16@1+ (1,0) [0|65535] "" Vector__XXX
SG_ VFSSModule1Detector3DetectorType : 48|4@1+ (1,0) [0|15] "" Vector__XXX
SG_ VFSSModule1Detctr3DetctrDatSLOT : 52|4@1+ (1,0) [0|15] "" Vector__XXX
SG_ VFSSModule1Detector3Data : 56|16@1+ (1,0) [0|65535] "" Vector__XXX
SG_ VFSSModule1Detector4DetectorType : 72|4@1+ (1,0) [0|15] "" Vector__XXX
SG_ VFSSModule1Detctr4DetctrDatSLOT : 76|4@1+ (1,0) [0|15] "" Vector__XXX
SG_ VFSSModule1Detector4Data : 80|16@1+ (1,0) [0|65535] "" Vector__XXX
SG_ VFSSModule1Detector5DetectorType : 96|4@1+ (1,0) [0|15] "" Vector__XXX
SG_ VFSSModule1Detctr5DetctrDatSLOT : 100|4@1+ (1,0) [0|15] "" Vector__XXX
SG_ VFSSModule1Detector5Data : 104|16@1+ (1,0) [0|65535] "" Vector__XXX
SG_ VFSSModule1Detector6DetectorType : 120|4@1+ (1,0) [0|15] "" Vector__XXX
SG_ VFSSModule1Detctr6DetctrDatSLOT : 124|4@1+ (1,0) [0|15] "" Vector__XXX
SG_ VFSSModule1Detector6Data : 128|16@1+ (1,0) [0|65535] "" Vector__XXX
SG_ VFSSModule1Detector7DetectorType : 144|4@1+ (1,0) [0|15] "" Vector__XXX
SG_ VFSSModule1Detctr7DetctrDatSLOT : 148|4@1+ (1,0) [0|15] "" Vector__XXX
SG_ VFSSModule1Detector7Data : 152|16@1+ (1,0) [0|65535] "" Vector__XXX
SG_ VFSSModule1Detector8DetectorType : 168|4@1+ (1,0) [0|15] "" Vector__XXX
SG_ VFSSModule1Detctr8DetctrDatSLOT : 172|4@1+ (1,0) [0|15] "" Vector__XXX
SG_ VFSSModule1Detector8Data : 176|16@1+ (1,0) [0|65535] "" Vector__XXX

BO_ 2633719038 VFSSM2DET: 24 Vector__XXX
SG_ VFSSModule2Detector1DetectorType : 0|4@1+ (1,0) [0|15] "" Vector__XXX
SG_ VFSSModule2Detctr1DetctrDatSLOT : 4|4@1+ (1,0) [0|15] "" Vector__XXX
SG_ VFSSModule2Detector1Data : 8|16@1+ (1,0) [0|65535] "" Vector__XXX
SG_ VFSSModule2Detector2DetectorType : 24|4@1+ (1,0) [0|15] "" Vector__XXX
SG_ VFSSModule2Detctr2DetctrDatSLOT : 28|4@1+ (1,0) [0|15] "" Vector__XXX
SG_ VFSSModule2Detector2Data : 32|16@1+ (1,0) [0|65535] "" Vector__XXX
SG_ VFSSModule2Detector3DetectorType : 48|4@1+ (1,0) [0|15] "" Vector__XXX
SG_ VFSSModule2Detctr3DetctrDatSLOT : 52|4@1+ (1,0) [0|15] "" Vector__XXX
SG_ VFSSModule2Detector3Data : 56|16@1+ (1,0) [0|65535] "" Vector__XXX
SG_ VFSSModule2Detector4DetectorType : 72|4@1+ (1,0) [0|15] "" Vector__XXX
SG_ VFSSModule2Detctr4DetctrDatSLOT : 76|4@1+ (1,0) [0|15] "" Vector__XXX
SG_ VFSSModule2Detector4Data : 80|16@1+ (1,0) [0|65535] "" Vector__XXX
SG_ VFSSModule2Detector5DetectorType : 96|4@1+ (1,0) [0|15] "" Vector__XXX
SG_ VFSSModule2Detctr5DetctrDatSLOT : 100|4@1+ (1,0) [0|15] "" Vector__XXX
SG_ VFSSModule2Detector5Data : 104|16@1+ (1,0) [0|65535] "" Vector__XXX
SG_ VFSSModule2Detector6DetectorType : 120|4@1+ (1,0) [0|15] "" Vector__XXX
SG_ VFSSModule2Detctr6DetctrDatSLOT : 124|4@1+ (1,0) [0|15] "" Vector__XXX
SG_ VFSSModule2Detector6Data : 128|16@1+ (1,0) [0|65535] "" Vector__XXX
SG_ VFSSModule2Detector7DetectorType : 144|4@1+ (1,0) [0|15] "" Vector__XXX
SG_ VFSSModule2Detctr7DetctrDatSLOT : 148|4@1+ (1,0) [0|15] "" Vector__XXX
SG_ VFSSModule2Detector7Data : 152|16@1+ (1,0) [0|65535] "" Vector__XXX
SG_ VFSSModule2Detector8DetectorType : 168|4@1+ (1,0) [0|15] "" Vector__XXX
SG_ VFSSModule2Detctr8DetctrDatSLOT : 172|4@1+ (1,0) [0|15] "" Vector__XXX
SG_ VFSSModule2Detector8Data : 176|16@1+ (1,0) [0|65535] "" Vector__XXX

BO_ 2633719294 VFSSM3DET: 24 Vector__XXX
SG_ VFSSModule3Detector1DetectorType : 0|4@1+ (1,0) [0|15] "" Vector__XXX
SG_ VFSSModule3Detctr1DetctrDatSLOT : 4|4@1+ (1,0) [0|15] "" Vector__XXX
SG_ VFSSModule3Detector1Data : 8|16@1+ (1,0) [0|65535] "" Vector__XXX
SG_ VFSSModule3Detector2DetectorType : 24|4@1+ (1,0) [0|15] "" Vector__XXX
SG_ VFSSModule3Detctr2DetctrDatSLOT : 28|4@1+ (1,0) [0|15] "" Vector__XXX
SG_ VFSSModule3Detector2Data : 32|16@1+ (1,0) [0|65535] "" Vector__XXX
SG_ VFSSModule3Detector3DetectorType : 48|4@1+ (1,0) [0|15] "" Vector__XXX
SG_ VFSSModule3Detctr3DetctrDatSLOT : 52|4@1+ (1,0) [0|15] "" Vector__XXX
SG_ VFSSModule3Detector3Data : 56|16@1+ (1,0) [0|65535] "" Vector__XXX
SG_ VFSSModule3Detector4DetectorType : 72|4@1+ (1,0) [0|15] "" Vector__XXX
SG_ VFSSModule3Detctr4DetctrDatSLOT : 76|4@1+ (1,0) [0|15] "" Vector__XXX
SG_ VFSSModule3Detector4Data : 80|16@1+ (1,0) [0|65535] "" Vector__XXX
SG_ VFSSModule3Detector5DetectorType : 96|4@1+ (1,0) [0|15] "" Vector__XXX
SG_ VFSSModule3Detctr5DetctrDatSLOT : 100|4@1+ (1,0) [0|15] "" Vector__XXX
SG_ VFSSModule3Detector5Data : 104|16@1+ (1,0) [0|65535] "" Vector__XXX
SG_ VFSSModule3Detector6DetectorType : 120|4@1+ (1,0) [0|15] "" Vector__XXX
SG_ VFSSModule3Detctr6DetctrDatSLOT : 124|4@1+ (1,0) [0|15] "" Vector__XXX
SG_ VFSSModule3Detector6Data : 128|16@1+ (1,0) [0|65535] "" Vector__XXX
SG_ VFSSModule3Detector7DetectorType : 144|4@1+ (1,0) [0|15] "" Vector__XXX
SG_ VFSSModule3Detctr7DetctrDatSLOT : 148|4@1+ (1,0) [0|15] "" Vector__XXX
SG_ VFSSModule3Detector7Data : 152|16@1+ (1,0) [0|65535] "" Vector__XXX
SG_ VFSSModule3Detector8DetectorType : 168|4@1+ (1,0) [0|15] "" Vector__XXX
SG_ VFSSModule3Detctr8DetctrDatSLOT : 172|4@1+ (1,0) [0|15] "" Vector__XXX
SG_ VFSSModule3Detector8Data : 176|16@1+ (1,0) [0|65535] "" Vector__XXX

BO_ 2633719550 VFSSM4DET: 24 Vector__XXX
SG_ VFSSModule4Detector1DetectorType : 0|4@1+ (1,0) [0|15] "" Vector__XXX
SG_ VFSSModule4Detctr1DetctrDatSLOT : 4|4@1+ (1,0) [0|15] "" Vector__XXX
SG_ VFSSModule4Detector1Data : 8|16@1+ (1,0) [0|65535] "" Vector__XXX
SG_ VFSSModule4Detector2DetectorType : 24|4@1+ (1,0) [0|15] "" Vector__XXX
SG_ VFSSModule4Detctr2DetctrDatSLOT : 28|4@1+ (1,0) [0|15] "" Vector__XXX
SG_ VFSSModule4Detector2Data : 32|16@1+ (1,0) [0|65535] "" Vector__XXX
SG_ VFSSModule4Detector3DetectorType : 48|4@1+ (1,0) [0|15] "" Vector__XXX
SG_ VFSSModule4Detctr3DetctrDatSLOT : 52|4@1+ (1,0) [0|15] "" Vector__XXX
SG_ VFSSModule4Detector3Data : 56|16@1+ (1,0) [0|65535] "" Vector__XXX
SG_ VFSSModule4Detector4DetectorType : 72|4@1+ (1,0) [0|15] "" Vector__XXX
SG_ VFSSModule4Detctr4DetctrDatSLOT : 76|4@1+ (1,0) [0|15] "" Vector__XXX
SG_ VFSSModule4Detector4Data : 80|16@1+ (1,0) [0|65535] "" Vector__XXX
SG_ VFSSModule4Detector5DetectorType : 96|4@1+ (1,0) [0|15] "" Vector__XXX
SG_ VFSSModule4Detctr5DetctrDatSLOT : 100|4@1+ (1,0) [0|15] "" Vector__XXX
SG_ VFSSModule4Detector5Data : 104|16@1+ (1,0) [0|65535] "" Vector__XXX
SG_ VFSSModule4Detector6DetectorType : 120|4@1+ (1,0) [0|15] "" Vector__XXX
SG_ VFSSModule4Detctr6DetctrDatSLOT : 124|4@1+ (1,0) [0|15] "" Vector__XXX
SG_ VFSSModule4Detector6Data : 128|16@1+ (1,0) [0|65535] "" Vector__XXX
SG_ VFSSModule4Detector7DetectorType : 144|4@1+ (1,0) [0|15] "" Vector__XXX
SG_ VFSSModule4Detctr7DetctrDatSLOT : 148|4@1+ (1,0) [0|15] "" Vector__XXX
SG_ VFSSModule4Detector7Data : 152|16@1+ (1,0) [0|65535] "" Vector__XXX
SG_ VFSSModule4Detector8DetectorType : 168|4@1+ (1,0) [0|15] "" Vector__XXX
SG_ VFSSModule4Detctr8DetctrDatSLOT : 172|4@1+ (1,0) [0|15] "" Vector__XXX
SG_ VFSSModule4Detector8Data : 176|16@1+ (1,0) [0|65535] "" Vector__XXX

BO_ 2633719806 VFSSM1AUX: 16 Vector__XXX
SG_ VFSSModule1HeatZone1Data : 0|16@1+ (0.01,0) [0|642.55] "V" Vector__XXX
SG_ VFSSModule1HeatZone2Data : 16|16@1+ (0.01,0) [0|642.55] "V" Vector__XXX
SG_ VFSSModule1ReleaseZone1Data : 32|16@1+ (0.01,0) [0|642.55] "V" Vector__XXX
SG_ VFSSModule1ReleaseZone2Data : 48|16@1+ (0.01,0) [0|642.55] "V" Vector__XXX
SG_ VFSSModule1PressureSwitch1Data : 64|16@1+ (0.01,0) [0|642.55] "V" Vector__XXX
SG_ VFSSModule1PressureSwitch2Data : 80|16@1+ (0.01,0) [0|642.55] "V" Vector__XXX
SG_ VFSSModule1PrimaryPowerVoltage : 96|16@1+ (0.01,0) [0|642.55] "V" Vector__XXX
SG_ VFSSModule1SecondaryPowerVoltage : 112|16@1+ (0.01,0) [0|642.55] "V" Vector__XXX

BO_ 2633720062 VFSSM2AUX: 16 Vector__XXX
SG_ VFSSModule2HeatZone1Data : 0|16@1+ (0.01,0) [0|642.55] "V" Vector__XXX
SG_ VFSSModule2HeatZone2Data : 16|16@1+ (0.01,0) [0|642.55] "V" Vector__XXX
SG_ VFSSModule2ReleaseZone1Data : 32|16@1+ (0.01,0) [0|642.55] "V" Vector__XXX
SG_ VFSSModule2ReleaseZone2Data : 48|16@1+ (0.01,0) [0|642.55] "V" Vector__XXX
SG_ VFSSModule2PressureSwitch1Data : 64|16@1+ (0.01,0) [0|642.55] "V" Vector__XXX
SG_ VFSSModule2PressureSwitch2Data : 80|16@1+ (0.01,0) [0|642.55] "V" Vector__XXX
SG_ VFSSModule2PrimaryPowerVoltage : 96|16@1+ (0.01,0) [0|642.55] "V" Vector__XXX
SG_ VFSSModule2SecondaryPowerVoltage : 112|16@1+ (0.01,0) [0|642.55] "V" Vector__XXX

BO_ 2633720318 VFSSM3AUX: 16 Vector__XXX
SG_ VFSSModule3HeatZone1Data : 0|16@1+ (0.01,0) [0|642.55] "V" Vector__XXX
SG_ VFSSModule3HeatZone2Data : 16|16@1+ (0.01,0) [0|642.55] "V" Vector__XXX
SG_ VFSSModule3ReleaseZone1Data : 32|16@1+ (0.01,0) [0|642.55] "V" Vector__XXX
SG_ VFSSModule3ReleaseZone2Data : 48|16@1+ (0.01,0) [0|642.55] "V" Vector__XXX
SG_ VFSSModule3PressureSwitch1Data : 64|16@1+ (0.01,0) [0|642.55] "V" Vector__XXX
SG_ VFSSModule3PressureSwitch2Data : 80|16@1+ (0.01,0) [0|642.55] "V" Vector__XXX
SG_ VFSSModule3PrimaryPowerVoltage : 96|16@1+ (0.01,0) [0|642.55] "V" Vector__XXX
SG_ VFSSModule3SecondaryPowerVoltage : 112|16@1+ (0.01,0) [0|642.55] "V" Vector__XXX

BO_ 2633720574 VFSSM4AUX: 16 Vector__XXX
SG_ VFSSModule4HeatZone1Data : 0|16@1+ (0.01,0) [0|642.55] "V" Vector__XXX
SG_ VFSSModule4HeatZone2Data : 16|16@1+ (0.01,0) [0|642.55] "V" Vector__XXX
SG_ VFSSModule4ReleaseZone1Data : 32|16@1+ (0.01,0) [0|642.55] "V" Vector__XXX
SG_ VFSSModule4ReleaseZone2Data : 48|16@1+ (0.01,0) [0|642.55] "V" Vector__XXX
SG_ VFSSModule4PressureSwitch1Data : 64|16@1+ (0.01,0) [0|642.55] "V" Vector__XXX
SG_ VFSSModule4PressureSwitch2Data : 80|16@1+ (0.01,0) [0|642.55] "V" Vector__XXX
SG_ VFSSModule4PrimaryPowerVoltage : 96|16@1+ (0.01,0) [0|642.55] "V" Vector__XXX
SG_ VFSSModule4SecondaryPowerVoltage : 112|16@1+ (0.01,0) [0|642.55] "V" Vector__XXX

BO_ 2633720830 VFSSM1NAMES: 104 Vector__XXX
SG_ VFSSModule1Name : 7|64@0+ (1,0) [0|0] "ASCII" Vector__XXX
SG_ VFSSModule1DetectorZone1Name : 71|64@0+ (1,0) [0|0] "ASCII" Vector__XXX
SG_ VFSSModule1DetectorZone2Name : 135|64@0+ (1,0) [0|0] "ASCII" Vector__XXX
SG_ VFSSModule1DetectorZone3Name : 199|64@0+ (1,0) [0|0] "ASCII" Vector__XXX
SG_ VFSSModule1DetectorZone4Name : 263|64@0+ (1,0) [0|0] "ASCII" Vector__XXX
SG_ VFSSModule1DetectorZone5Name : 327|64@0+ (1,0) [0|0] "ASCII" Vector__XXX
SG_ VFSSModule1DetectorZone6Name : 391|64@0+ (1,0) [0|0] "ASCII" Vector__XXX
SG_ VFSSModule1DetectorZone7Name : 455|64@0+ (1,0) [0|0] "ASCII" Vector__XXX
SG_ VFSSModule1DetectorZone8Name : 519|64@0+ (1,0) [0|0] "ASCII" Vector__XXX
SG_ VFSSModule1HeatZone1Name : 583|64@0+ (1,0) [0|0] "ASCII" Vector__XXX
SG_ VFSSModule1HeatZone2Name : 647|64@0+ (1,0) [0|0] "ASCII" Vector__XXX
SG_ VFSSModule1ReleaseZone1Name : 711|64@0+ (1,0) [0|0] "ASCII" Vector__XXX
SG_ VFSSModule1ReleaseZone2Name : 775|64@0+ (1,0) [0|0] "ASCII" Vector__XXX

BO_ 2633721086 VFSSM2NAMES: 104 Vector__XXX
SG_ VFSSModule2Name : 7|64@0+ (1,0) [0|0] "ASCII" Vector__XXX
SG_ VFSSModule2DetectorZone1Name : 71|64@0+ (1,0) [0|0] "ASCII" Vector__XXX
SG_ VFSSModule2DetectorZone2Name : 135|64@0+ (1,0) [0|0] "ASCII" Vector__XXX
SG_ VFSSModule2DetectorZone3Name : 199|64@0+ (1,0) [0|0] "ASCII" Vector__XXX
SG_ VFSSModule2DetectorZone4Name : 263|64@0+ (1,0) [0|0] "ASCII" Vector__XXX
SG_ VFSSModule2DetectorZone5Name : 327|64@0+ (1,0) [0|0] "ASCII" Vector__XXX
SG_ VFSSModule2DetectorZone6Name : 391|64@0+ (1,0) [0|0] "ASCII" Vector__XXX
SG_ VFSSModule2DetectorZone7Name : 455|64@0+ (1,0) [0|0] "ASCII" Vector__XXX
SG_ VFSSModule2DetectorZone8Name : 519|64@0+ (1,0) [0|0] "ASCII" Vector__XXX
SG_ VFSSModule2HeatZone1Name : 583|64@0+ (1,0) [0|0] "ASCII" Vector__XXX
SG_ VFSSModule2HeatZone2Name : 647|64@0+ (1,0) [0|0] "ASCII" Vector__XXX
SG_ VFSSModule2ReleaseZone1Name : 711|64@0+ (1,0) [0|0] "ASCII" Vector__XXX
SG_ VFSSModule2ReleaseZone2Name : 775|64@0+ (1,0) [0|0] "ASCII" Vector__XXX

BO_ 2633721342 VFSSM3NAMES: 104 Vector__XXX
SG_ VFSSModule3Name : 7|64@0+ (1,0) [0|0] "ASCII" Vector__XXX
SG_ VFSSModule3DetectorZone1Name : 71|64@0+ (1,0) [0|0] "ASCII" Vector__XXX
SG_ VFSSModule3DetectorZone2Name : 135|64@0+ (1,0) [0|0] "ASCII" Vector__XXX
SG_ VFSSModule3DetectorZone3Name : 199|64@0+ (1,0) [0|0] "ASCII" Vector__XXX
SG_ VFSSModule3DetectorZone4Name : 263|64@0+ (1,0) [0|0] "ASCII" Vector__XXX
SG_ VFSSModule3DetectorZone5Name : 327|64@0+ (1,0) [0|0] "ASCII" Vector__XXX
SG_ VFSSModule3DetectorZone6Name : 391|64@0+ (1,0) [0|0] "ASCII" Vector__XXX
SG_ VFSSModule3DetectorZone7Name : 455|64@0+ (1,0) [0|0] "ASCII" Vector__XXX
SG_ VFSSModule3DetectorZone8Name : 519|64@0+ (1,0) [0|0] "ASCII" Vector__XXX
SG_ VFSSModule3HeatZone1Name : 583|64@0+ (1,0) [0|0] "ASCII" Vector__XXX
SG_ VFSSModule3HeatZone2Name : 647|64@0+ (1,0) [0|0] "ASCII" Vector__XXX
SG_ VFSSModule3ReleaseZone1Name : 711|64@0+ (1,0) [0|0] "ASCII" Vector__XXX
SG_ VFSSModule3ReleaseZone2Name : 775|64@0+ (1,0) [0|0] "ASCII" Vector__XXX

BO_ 2633721598 VFSSM4NAMES: 104 Vector__XXX
SG_ VFSSModule4Name : 7|64@0+ (1,0) [0|0] "ASCII" Vector__XXX
SG_ VFSSModule4DetectorZone1Name : 71|64@0+ (1,0) [0|0] "ASCII" Vector__XXX
SG_ VFSSModule4DetectorZone2Name : 135|64@0+ (1,0) [0|0] "ASCII" Vector__XXX
SG_ VFSSModule4DetectorZone3Name : 199|64@0+ (1,0) [0|0] "ASCII" Vector__XXX
SG_ VFSSModule4DetectorZone4Name : 263|64@0+ (1,0) [0|0] "ASCII" Vector__XXX
SG_ VFSSModule4DetectorZone5Name : 327|64@0+ (1,0) [0|0] "ASCII" Vector__XXX
SG_ VFSSModule4DetectorZone6Name : 391|64@0+ (1,0) [0|0] "ASCII" Vector__XXX
SG_ VFSSModule4DetectorZone7Name : 455|64@0+ (1,0) [0|0] "ASCII" Vector__XXX
SG_ VFSSModule4DetectorZone8Name : 519|64@0+ (1,0) [0|0] "ASCII" Vector__XXX
SG_ VFSSModule4HeatZone1Name : 583|64@0+ (1,0) [0|0] "ASCII" Vector__XXX
SG_ VFSSModule4HeatZone2Name : 647|64@0+ (1,0) [0|0] "ASCII" Vector__XXX
SG_ VFSSModule4ReleaseZone1Name : 711|64@0+ (1,0) [0|0] "ASCII" Vector__XXX
SG_ VFSSModule4ReleaseZone2Name : 775|64@0+ (1,0) [0|0] "ASCII" Vector__XXX

BO_ 2566612990 MG2IAPL: 8 Vector__XXX
SG_ MtrGen2InvPwrLmtedDTUndefndRsn : 0|2@1+ (1,0) [0|3] "" Vector__XXX
SG_ MtrGen2InvPwrLmtedDTDCSdeCurMax : 2|2@1+ (1,0) [0|3] "" Vector__XXX
SG_ MtrGen2InvPwrLmtedDTDCSdeCurMin : 4|2@1+ (1,0) [0|3] "" Vector__XXX
SG_ MtrGen2InvPwrLmtedDTDCSdeVltgMax : 6|2@1+ (1,0) [0|3] "" Vector__XXX
SG_ MtrGen2InvPwrLmtedDTDCSdeVltgMin : 8|2@1+ (1,0) [0|3] "" Vector__XXX
SG_ MtrGen2InvPwrLmtDTMechnclPwrMax : 10|2@1+ (1,0) [0|3] "" Vector__XXX
SG_ MtrGen2InvPwrLmtDTMechnclPwrMin : 12|2@1+ (1,0) [0|3] "" Vector__XXX
SG_ MtrGen2InvPwrLmtedDTDCSdePwrMax : 14|2@1+ (1,0) [0|3] "" Vector__XXX
SG_ MtrGen2InvPwrLmtedDTDCSdePwrMin : 16|2@1+ (1,0) [0|3] "" Vector__XXX
SG_ MtrGen2InvertPwrLmtedDTTorqueMax : 18|2@1+ (1,0) [0|3] "" Vector__XXX
SG_ MtrGen2InvertPwrLmtedDTTorqueMin : 20|2@1+ (1,0) [0|3] "" Vector__XXX
SG_ MtrGen2InvertPwrLmtedDTSpeedMax : 22|2@1+ (1,0) [0|3] "" Vector__XXX
SG_ MtrGen2InvertPwrLmtedDTSpeedMin : 24|2@1+ (1,0) [0|3] "" Vector__XXX
SG_ MtrGen2InvPwrLmtedDTInvertTemp : 28|2@1+ (1,0) [0|3] "" Vector__XXX
SG_ MtrGen2InvertPwrLmtedDTMtrTemp : 30|2@1+ (1,0) [0|3] "" Vector__XXX

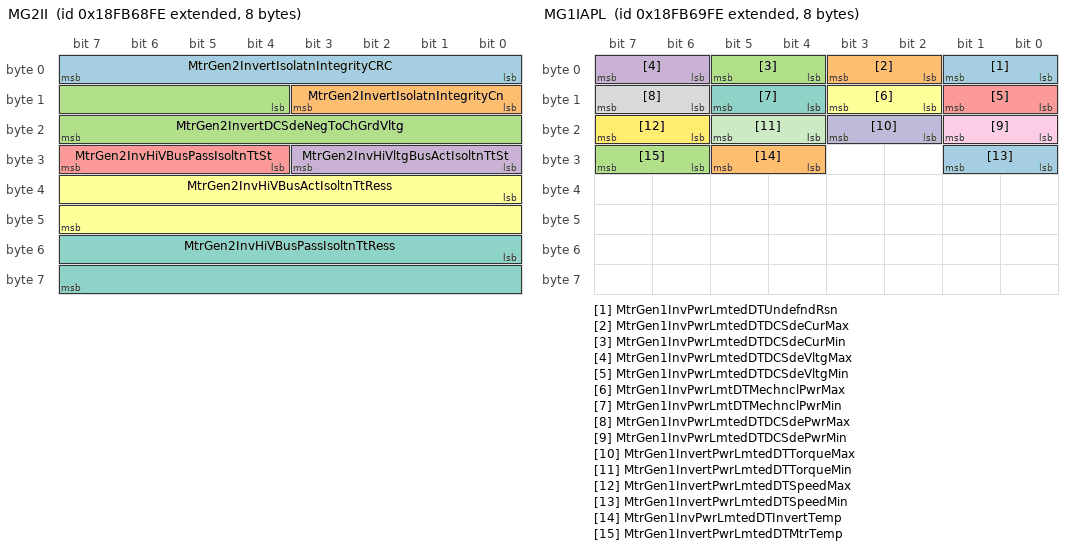
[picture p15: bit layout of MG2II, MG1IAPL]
BO_ 2566613246 MG2II: 8 Vector__XXX
SG_ MtrGen2InvertIsolatnIntegrityCRC : 0|8@1+ (1,0) [0|255] "" Vector__XXX
SG_ MtrGen2InvertIsolatnIntegrityCn : 8|4@1+ (1,0) [0|15] "" Vector__XXX
SG_ MtrGen2InvertDCSdeNegToChGrdVltg : 12|12@1+ (0.0625,-125) [-125|125.9375] "%" Vector__XXX
SG_ MtrGen2InvHiVltgBusActIsoltnTtSt : 24|4@1+ (1,0) [0|15] "" Vector__XXX
SG_ MtrGen2InvHiVBusPassIsoltnTtSt : 28|4@1+ (1,0) [0|15] "" Vector__XXX
SG_ MtrGen2InvHiVBusActIsoltnTtRess : 32|16@1+ (0.1,0) [0|6425.5] "ohm/V" Vector__XXX
SG_ MtrGen2InvHiVBusPassIsoltnTtRess : 48|16@1+ (0.1,0) [0|6425.5] "ohm/V" Vector__XXX

BO_ 2566613502 MG1IAPL: 8 Vector__XXX
SG_ MtrGen1InvPwrLmtedDTUndefndRsn : 0|2@1+ (1,0) [0|3] "" Vector__XXX
SG_ MtrGen1InvPwrLmtedDTDCSdeCurMax : 2|2@1+ (1,0) [0|3] "" Vector__XXX
SG_ MtrGen1InvPwrLmtedDTDCSdeCurMin : 4|2@1+ (1,0) [0|3] "" Vector__XXX
SG_ MtrGen1InvPwrLmtedDTDCSdeVltgMax : 6|2@1+ (1,0) [0|3] "" Vector__XXX
SG_ MtrGen1InvPwrLmtedDTDCSdeVltgMin : 8|2@1+ (1,0) [0|3] "" Vector__XXX
SG_ MtrGen1InvPwrLmtDTMechnclPwrMax : 10|2@1+ (1,0) [0|3] "" Vector__XXX
SG_ MtrGen1InvPwrLmtDTMechnclPwrMin : 12|2@1+ (1,0) [0|3] "" Vector__XXX
SG_ MtrGen1InvPwrLmtedDTDCSdePwrMax : 14|2@1+ (1,0) [0|3] "" Vector__XXX
SG_ MtrGen1InvPwrLmtedDTDCSdePwrMin : 16|2@1+ (1,0) [0|3] "" Vector__XXX
SG_ MtrGen1InvertPwrLmtedDTTorqueMax : 18|2@1+ (1,0) [0|3] "" Vector__XXX
SG_ MtrGen1InvertPwrLmtedDTTorqueMin : 20|2@1+ (1,0) [0|3] "" Vector__XXX
SG_ MtrGen1InvertPwrLmtedDTSpeedMax : 22|2@1+ (1,0) [0|3] "" Vector__XXX
SG_ MtrGen1InvertPwrLmtedDTSpeedMin : 24|2@1+ (1,0) [0|3] "" Vector__XXX
SG_ MtrGen1InvPwrLmtedDTInvertTemp : 28|2@1+ (1,0) [0|3] "" Vector__XXX
SG_ MtrGen1InvertPwrLmtedDTMtrTemp : 30|2@1+ (1,0) [0|3] "" Vector__XXX

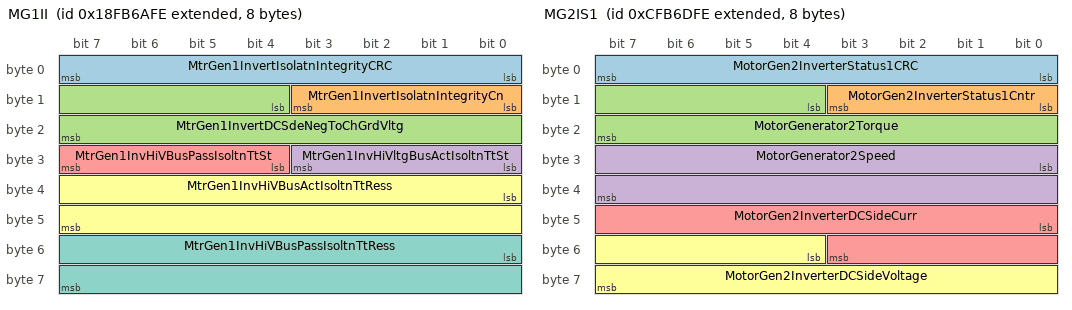
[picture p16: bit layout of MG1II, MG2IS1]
BO_ 2566613758 MG1II: 8 Vector__XXX
SG_ MtrGen1InvertIsolatnIntegrityCRC : 0|8@1+ (1,0) [0|255] "" Vector__XXX
SG_ MtrGen1InvertIsolatnIntegrityCn : 8|4@1+ (1,0) [0|15] "" Vector__XXX
SG_ MtrGen1InvertDCSdeNegToChGrdVltg : 12|12@1+ (0.0625,-125) [-125|125.9375] "%" Vector__XXX
SG_ MtrGen1InvHiVltgBusActIsoltnTtSt : 24|4@1+ (1,0) [0|15] "" Vector__XXX
SG_ MtrGen1InvHiVBusPassIsoltnTtSt : 28|4@1+ (1,0) [0|15] "" Vector__XXX
SG_ MtrGen1InvHiVBusActIsoltnTtRess : 32|16@1+ (0.1,0) [0|6425.5] "ohm/V" Vector__XXX
SG_ MtrGen1InvHiVBusPassIsoltnTtRess : 48|16@1+ (0.1,0) [0|6425.5] "ohm/V" Vector__XXX

BO_ 2566614014 HVBI: 8 Vector__XXX
SG_ HighVoltageDCBusAvailability : 0|4@1+ (1,0) [0|15] "" Vector__XXX

BO_ 2365287678 MG2IR1: 8 Vector__XXX
SG_ MotorGen2InverterReference1CRC : 0|8@1+ (1,0) [0|255] "" Vector__XXX
SG_ MotorGen2InverterReference1Cntr : 8|4@1+ (1,0) [0|15] "" Vector__XXX
SG_ MotorGen2InverterReferenceTorque : 16|16@1+ (0.5,0) [0|32127.5] "Nm" Vector__XXX
SG_ MotorGen2InverterReferenceSpeed : 32|16@1+ (4,0) [0|257020] "rpm" Vector__XXX
SG_ MotorGen2InverterReferencePower : 48|16@1+ (0.0625,0) [0|4015.9375] "kW" Vector__XXX

BO_ 2365287934 MG2IS1: 8 Vector__XXX
SG_ MotorGen2InverterStatus1CRC : 0|8@1+ (1,0) [0|255] "" Vector__XXX
SG_ MotorGen2InverterStatus1Cntr : 8|4@1+ (1,0) [0|15] "" Vector__XXX
SG_ MotorGenerator2Torque : 12|12@1+ (0.0625,-125) [-125|125.9375] "%" Vector__XXX
SG_ MotorGenerator2Speed : 24|16@1+ (0.00390625,-125) [-125|125.99609375] "%" Vector__XXX
SG_ MotorGen2InverterDCSideCurr : 40|12@1+ (0.0625,-125) [-125|125.9375] "%" Vector__XXX
SG_ MotorGen2InverterDCSideVoltage : 52|12@1+ (0.0625,-125) [-125|125.9375] "%" Vector__XXX

BO_ 2365288190 MG2IR2: 8 Vector__XXX
SG_ MotorGen2InverterReference2CRC : 0|8@1+ (1,0) [0|255] "" Vector__XXX
SG_ MotorGen2InverterReference2Cntr : 8|4@1+ (1,0) [0|15] "" Vector__XXX
SG_ MotorGen2InverterReferenceCurr : 32|16@1+ (0.125,0) [0|8031.875] "A" Vector__XXX
SG_ MotorGen2InvertReferenceVoltage : 48|16@1+ (0.125,0) [0|8031.875] "V" Vector__XXX

BO_ 2566615038 MG2IT: 8 Vector__XXX
SG_ MotorGen2InverterTemperature1 : 0|8@1+ (1,-40) [-40|210] "deg C" Vector__XXX
SG_ MotorGen2InverterTemperature2 : 8|8@1+ (1,-40) [-40|210] "deg C" Vector__XXX
SG_ MotorGen2InverterTemperature3 : 16|8@1+ (1,-40) [-40|210] "deg C" Vector__XXX
SG_ MotorGen2InverterTemperature4 : 24|8@1+ (1,-40) [-40|210] "deg C" Vector__XXX

BO_ 2566615294 MG2IMT: 8 Vector__XXX
SG_ MotorGenerator2Temperature1 : 0|8@1+ (1,-40) [-40|210] "deg C" Vector__XXX
SG_ MotorGenerator2Temperature2 : 8|8@1+ (1,-40) [-40|210] "deg C" Vector__XXX
SG_ MotorGenerator2Temperature3 : 16|8@1+ (1,-40) [-40|210] "deg C" Vector__XXX
SG_ MotorGenerator2Temperature4 : 24|8@1+ (1,-40) [-40|210] "deg C" Vector__XXX

BO_ 2566615550 MG1IMT: 8 Vector__XXX
SG_ MotorGenerator1Temperature1 : 0|8@1+ (1,-40) [-40|210] "deg C" Vector__XXX
SG_ MotorGenerator1Temperature2 : 8|8@1+ (1,-40) [-40|210] "deg C" Vector__XXX
SG_ MotorGenerator1Temperature3 : 16|8@1+ (1,-40) [-40|210] "deg C" Vector__XXX
SG_ MotorGenerator1Temperature4 : 24|8@1+ (1,-40) [-40|210] "deg C" Vector__XXX

BO_ 2566615806 MG1IT: 8 Vector__XXX
SG_ MotorGen1InverterTemperature1 : 0|8@1+ (1,-40) [-40|210] "deg C" Vector__XXX
SG_ MotorGen1InverterTemperature2 : 8|8@1+ (1,-40) [-40|210] "deg C" Vector__XXX
SG_ MotorGen1InverterTemperature3 : 16|8@1+ (1,-40) [-40|210] "deg C" Vector__XXX
SG_ MotorGen1InverterTemperature4 : 24|8@1+ (1,-40) [-40|210] "deg C" Vector__XXX

BO_ 2365289470 MG1IR2: 8 Vector__XXX
SG_ MotorGen1InverterReference2CRC : 0|8@1+ (1,0) [0|255] "" Vector__XXX
SG_ MotorGen1InverterReference2Cntr : 8|4@1+ (1,0) [0|15] "" Vector__XXX
SG_ MotorGen1InverterReferenceCurr : 32|16@1+ (0.125,0) [0|8031.875] "A" Vector__XXX
SG_ MotorGen1InvertReferenceVoltage : 48|16@1+ (0.125,0) [0|8031.875] "V" Vector__XXX

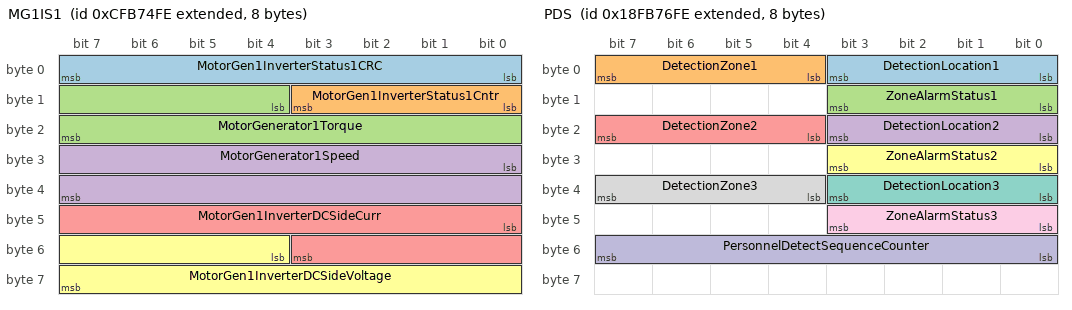
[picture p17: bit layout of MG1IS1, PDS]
BO_ 2365289726 MG1IS1: 8 Vector__XXX
SG_ MotorGen1InverterStatus1CRC : 0|8@1+ (1,0) [0|255] "" Vector__XXX
SG_ MotorGen1InverterStatus1Cntr : 8|4@1+ (1,0) [0|15] "" Vector__XXX
SG_ MotorGenerator1Torque : 12|12@1+ (0.0625,-125) [-125|125.9375] "%" Vector__XXX
SG_ MotorGenerator1Speed : 24|16@1+ (0.00390625,-125) [-125|125.99609375] "%" Vector__XXX
SG_ MotorGen1InverterDCSideCurr : 40|12@1+ (0.0625,-125) [-125|125.9375] "%" Vector__XXX
SG_ MotorGen1InverterDCSideVoltage : 52|12@1+ (0.0625,-125) [-125|125.9375] "%" Vector__XXX

BO_ 2365289982 MG1IR1: 8 Vector__XXX
SG_ MotorGen1InverterReference1CRC : 0|8@1+ (1,0) [0|255] "" Vector__XXX
SG_ MotorGen1InverterReference1Cntr : 8|4@1+ (1,0) [0|15] "" Vector__XXX
SG_ MotorGen1InverterReferenceTorque : 16|16@1+ (0.5,0) [0|32127.5] "Nm" Vector__XXX
SG_ MotorGen1InverterReferenceSpeed : 32|16@1+ (4,0) [0|257020] "rpm" Vector__XXX
SG_ MotorGen1InverterReferencePower : 48|16@1+ (0.0625,0) [0|4015.9375] "kW" Vector__XXX

BO_ 2566616830 PDS: 8 Vector__XXX
SG_ DetectionLocation1 : 0|4@1+ (1,0) [0|13] "" Vector__XXX
SG_ DetectionZone1 : 4|4@1+ (1,0) [0|13] "" Vector__XXX
SG_ ZoneAlarmStatus1 : 8|4@1+ (1,0) [0|15] "" Vector__XXX
SG_ DetectionLocation2 : 16|4@1+ (1,0) [0|13] "" Vector__XXX
SG_ DetectionZone2 : 20|4@1+ (1,0) [0|13] "" Vector__XXX
SG_ ZoneAlarmStatus2 : 24|4@1+ (1,0) [0|15] "" Vector__XXX
SG_ DetectionLocation3 : 32|4@1+ (1,0) [0|13] "" Vector__XXX
SG_ DetectionZone3 : 36|4@1+ (1,0) [0|13] "" Vector__XXX
SG_ ZoneAlarmStatus3 : 40|4@1+ (1,0) [0|15] "" Vector__XXX
SG_ PersonnelDetectSequenceCounter : 48|8@1+ (1,0) [0|255] "" Vector__XXX

BO_ 2566617086 ECPG1: 8 Vector__XXX
SG_ EngineCyl1CompressionGammaRatio : 0|8@1+ (0.004,1) [1|2] "" Vector__XXX
SG_ EngineCyl1ExpansionGammaRatio : 8|8@1+ (0.004,1) [1|2] "" Vector__XXX
SG_ EngineCyl2CompressionGammaRatio : 16|8@1+ (0.004,1) [1|2] "" Vector__XXX
SG_ EngineCyl2ExpansionGammaRatio : 24|8@1+ (0.004,1) [1|2] "" Vector__XXX
SG_ EngineCyl3CompressionGammaRatio : 32|8@1+ (0.004,1) [1|2] "" Vector__XXX
SG_ EngineCyl3ExpansionGammaRatio : 40|8@1+ (0.004,1) [1|2] "" Vector__XXX
SG_ EngineCyl4CompressionGammaRatio : 48|8@1+ (0.004,1) [1|2] "" Vector__XXX
SG_ EngineCyl4ExpansionGammaRatio : 56|8@1+ (0.004,1) [1|2] "" Vector__XXX

BO_ 2566617342 ECPG2: 8 Vector__XXX
SG_ EngineCyl5CompressionGammaRatio : 0|8@1+ (0.004,1) [1|2] "" Vector__XXX
SG_ EngineCyl5ExpansionGammaRatio : 8|8@1+ (0.004,1) [1|2] "" Vector__XXX
SG_ EngineCyl6CompressionGammaRatio : 16|8@1+ (0.004,1) [1|2] "" Vector__XXX
SG_ EngineCyl6ExpansionGammaRatio : 24|8@1+ (0.004,1) [1|2] "" Vector__XXX
SG_ EngineCyl7CompressionGammaRatio : 32|8@1+ (0.004,1) [1|2] "" Vector__XXX
SG_ EngineCyl7ExpansionGammaRatio : 40|8@1+ (0.004,1) [1|2] "" Vector__XXX
SG_ EngineCyl8CompressionGammaRatio : 48|8@1+ (0.004,1) [1|2] "" Vector__XXX
SG_ EngineCyl8ExpansionGammaRatio : 56|8@1+ (0.004,1) [1|2] "" Vector__XXX

BO_ 2566617598 ECPG3: 8 Vector__XXX
SG_ EngineCyl9CompressionGammaRatio : 0|8@1+ (0.004,1) [1|2] "" Vector__XXX
SG_ EngineCyl9ExpansionGammaRatio : 8|8@1+ (0.004,1) [1|2] "" Vector__XXX
SG_ EngineCyl10CompressionGammaRatio : 16|8@1+ (0.004,1) [1|2] "" Vector__XXX
SG_ EngineCyl10ExpansionGammaRatio : 24|8@1+ (0.004,1) [1|2] "" Vector__XXX
SG_ EngineCyl11CompressionGammaRatio : 32|8@1+ (0.004,1) [1|2] "" Vector__XXX
SG_ EngineCyl11ExpansionGammaRatio : 40|8@1+ (0.004,1) [1|2] "" Vector__XXX
SG_ EngineCyl12CompressionGammaRatio : 48|8@1+ (0.004,1) [1|2] "" Vector__XXX
SG_ EngineCyl12ExpansionGammaRatio : 56|8@1+ (0.004,1) [1|2] "" Vector__XXX

BO_ 2566617854 ECPG4: 8 Vector__XXX
SG_ EngineCyl13CompressionGammaRatio : 0|8@1+ (0.004,1) [1|2] "" Vector__XXX
SG_ EngineCyl13ExpansionGammaRatio : 8|8@1+ (0.004,1) [1|2] "" Vector__XXX
SG_ EngineCyl14CompressionGammaRatio : 16|8@1+ (0.004,1) [1|2] "" Vector__XXX
SG_ EngineCyl14ExpansionGammaRatio : 24|8@1+ (0.004,1) [1|2] "" Vector__XXX
SG_ EngineCyl15CompressionGammaRatio : 32|8@1+ (0.004,1) [1|2] "" Vector__XXX
SG_ EngineCyl15ExpansionGammaRatio : 40|8@1+ (0.004,1) [1|2] "" Vector__XXX
SG_ EngineCyl16CompressionGammaRatio : 48|8@1+ (0.004,1) [1|2] "" Vector__XXX
SG_ EngineCyl16ExpansionGammaRatio : 56|8@1+ (0.004,1) [1|2] "" Vector__XXX

BO_ 2566618110 ECPG5: 8 Vector__XXX
SG_ EngineCyl17CompressionGammaRatio : 0|8@1+ (0.004,1) [1|2] "" Vector__XXX
SG_ EngineCyl17ExpansionGammaRatio : 8|8@1+ (0.004,1) [1|2] "" Vector__XXX
SG_ EngineCyl18CompressionGammaRatio : 16|8@1+ (0.004,1) [1|2] "" Vector__XXX
SG_ EngineCyl18ExpansionGammaRatio : 24|8@1+ (0.004,1) [1|2] "" Vector__XXX
SG_ EngineCyl19CompressionGammaRatio : 32|8@1+ (0.004,1) [1|2] "" Vector__XXX
SG_ EngineCyl19ExpansionGammaRatio : 40|8@1+ (0.004,1) [1|2] "" Vector__XXX
SG_ EngineCyl20CompressionGammaRatio : 48|8@1+ (0.004,1) [1|2] "" Vector__XXX
SG_ EngineCyl20ExpansionGammaRatio : 56|8@1+ (0.004,1) [1|2] "" Vector__XXX

BO_ 2566618366 WAKE: 0 Vector__XXX

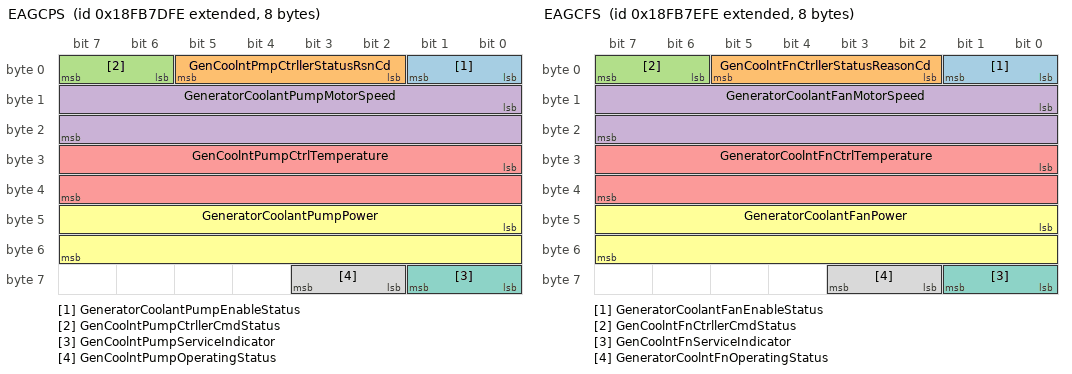
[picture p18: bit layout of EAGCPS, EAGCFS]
BO_ 2566618622 EAGCPS: 8 Vector__XXX
SG_ GeneratorCoolantPumpEnableStatus : 0|2@1+ (1,0) [0|3] "" Vector__XXX
SG_ GenCoolntPmpCtrllerStatusRsnCd : 2|4@1+ (1,0) [0|15] "" Vector__XXX
SG_ GenCoolntPumpCtrllerCmdStatus : 6|2@1+ (1,0) [0|3] "" Vector__XXX
SG_ GeneratorCoolantPumpMotorSpeed : 8|16@1+ (0.5,0) [0|32127.5] "rpm" Vector__XXX
SG_ GenCoolntPumpCtrlTemperature : 24|16@1+ (0.03125,-273) [-273|1734.96875] "deg C" Vector__XXX
SG_ GeneratorCoolantPumpPower : 40|16@1+ (0.5,0) [0|32127.5] "W" Vector__XXX
SG_ GenCoolntPumpServiceIndicator : 56|2@1+ (1,0) [0|3] "" Vector__XXX
SG_ GenCoolntPumpOperatingStatus : 58|2@1+ (1,0) [0|3] "" Vector__XXX

BO_ 2566618878 EAGCFS: 8 Vector__XXX
SG_ GeneratorCoolantFanEnableStatus : 0|2@1+ (1,0) [0|3] "" Vector__XXX
SG_ GenCoolntFnCtrllerStatusReasonCd : 2|4@1+ (1,0) [0|15] "" Vector__XXX
SG_ GenCoolntFnCtrllerCmdStatus : 6|2@1+ (1,0) [0|3] "" Vector__XXX
SG_ GeneratorCoolantFanMotorSpeed : 8|16@1+ (0.5,0) [0|32127.5] "rpm" Vector__XXX
SG_ GeneratorCoolntFnCtrlTemperature : 24|16@1+ (0.03125,-273) [-273|1734.96875] "deg C" Vector__XXX
SG_ GeneratorCoolantFanPower : 40|16@1+ (0.5,0) [0|32127.5] "W" Vector__XXX
SG_ GenCoolntFnServiceIndicator : 56|2@1+ (1,0) [0|3] "" Vector__XXX
SG_ GeneratorCoolntFnOperatingStatus : 58|2@1+ (1,0) [0|3] "" Vector__XXX

BO_ 2566619134 WSPF: 8 Vector__XXX
SG_ WellStimultnPmpOilFltrDiffPress : 0|8@1+ (4,0) [0|1000] "kPa" Vector__XXX
SG_ WellStimultnPmpOilFltrOtltPress : 8|16@1+ (0.1,0) [0|6425.5] "kPa" Vector__XXX
SG_ WllStimultnPmpOilFltrBypssSwStat : 24|2@1+ (1,0) [0|3] "" Vector__XXX

BO_ 2566619390 PTOGC: 22 Vector__XXX
SG_ PreprogrammedPTOGvrnrSetSpeed1 : 0|16@1+ (0.125,0) [0|8031.875] "rpm" Vector__XXX
SG_ PreprogrammedPTOGvrnrSetSpeed2 : 16|16@1+ (0.125,0) [0|8031.875] "rpm" Vector__XXX
SG_ PreprogrammedPTOGvrnrSetSpeed3 : 32|16@1+ (0.125,0) [0|8031.875] "rpm" Vector__XXX
SG_ PreprogrammedPTOGvrnrSetSpeed4 : 48|16@1+ (0.125,0) [0|8031.875] "rpm" Vector__XXX
SG_ PreprogrammedPTOGvrnrSetSpeed5 : 64|16@1+ (0.125,0) [0|8031.875] "rpm" Vector__XXX
SG_ PreprogrammedPTOGvrnrSetSpeed6 : 80|16@1+ (0.125,0) [0|8031.875] "rpm" Vector__XXX
SG_ PreprogrammedPTOGvrnrSetSpeed7 : 96|16@1+ (0.125,0) [0|8031.875] "rpm" Vector__XXX
SG_ PreprogrammedPTOGvrnrSetSpeed8 : 112|16@1+ (0.125,0) [0|8031.875] "rpm" Vector__XXX
SG_ MinimumPTOGovernorSetSpeed : 128|16@1+ (0.125,0) [0|8031.875] "rpm" Vector__XXX
SG_ MaximumPTOGovernorSetSpeed : 144|16@1+ (0.125,0) [0|8031.875] "rpm" Vector__XXX
SG_ PTOGvrnrAcclOverrideMaximumSpeed : 160|16@1+ (0.125,0) [0|8031.875] "rpm" Vector__XXX

BO_ 2566619646 OBP2: 8 Vector__XXX
SG_ OnBoardProgrammingInitECUAddr : 0|8@1+ (1,0) [0|255] "" Vector__XXX
SG_ OnBoardProgrammingInitRequest : 8|2@1+ (1,0) [0|3] "" Vector__XXX
SG_ OnBoardProgrammingInitiateInhbt : 10|2@1+ (1,0) [0|3] "" Vector__XXX

BO_ 2566619902 PFHY: 0 Vector__XXX

BO_ 2566620158 SFHY: 0 Vector__XXX

BO_ 2566620414 OPSTAT: 0 Vector__XXX

BO_ 2566620670 EIMI: 8 Vector__XXX
SG_ EngineIdleManagementStatus : 0|4@1+ (1,0) [0|15] "" Vector__XXX
SG_ EngIdleManagementRestartReason : 4|4@1+ (1,0) [0|15] "" Vector__XXX
SG_ EngIdleManagementShutdownReason : 8|4@1+ (1,0) [0|15] "" Vector__XXX
SG_ IdlMangmntPendngEvntTimeRemain : 16|16@1+ (1,0) [0|64255] "s" Vector__XXX

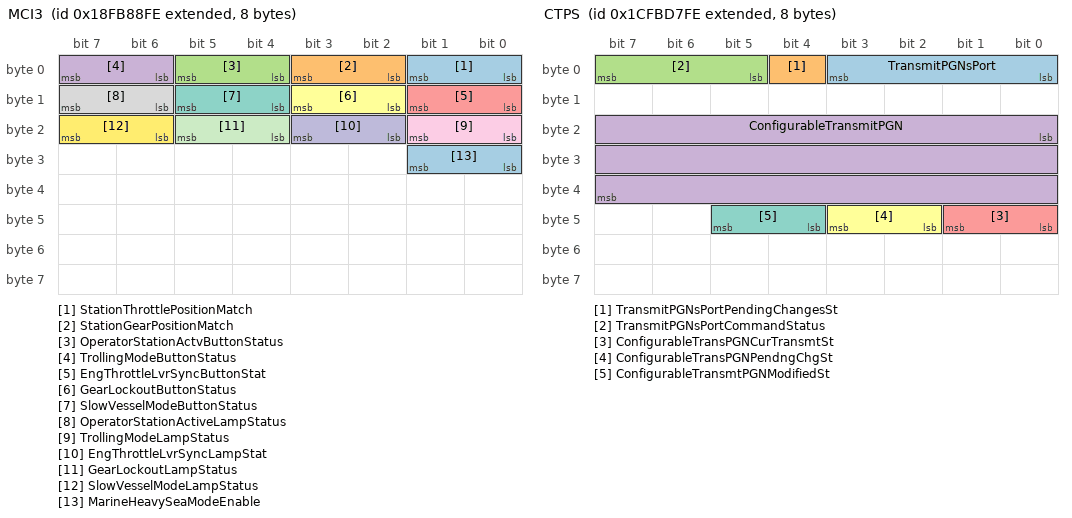
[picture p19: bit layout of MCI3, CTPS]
BO_ 2566621438 MCI3: 8 Vector__XXX
SG_ StationThrottlePositionMatch : 0|2@1+ (1,0) [0|3] "" Vector__XXX
SG_ StationGearPositionMatch : 2|2@1+ (1,0) [0|3] "" Vector__XXX
SG_ OperatorStationActvButtonStatus : 4|2@1+ (1,0) [0|3] "" Vector__XXX
SG_ TrollingModeButtonStatus : 6|2@1+ (1,0) [0|3] "" Vector__XXX
SG_ EngThrottleLvrSyncButtonStat : 8|2@1+ (1,0) [0|3] "" Vector__XXX
SG_ GearLockoutButtonStatus : 10|2@1+ (1,0) [0|3] "" Vector__XXX
SG_ SlowVesselModeButtonStatus : 12|2@1+ (1,0) [0|3] "" Vector__XXX
SG_ OperatorStationActiveLampStatus : 14|2@1+ (1,0) [0|3] "" Vector__XXX
SG_ TrollingModeLampStatus : 16|2@1+ (1,0) [0|3] "" Vector__XXX
SG_ EngThrottleLvrSyncLampStat : 18|2@1+ (1,0) [0|3] "" Vector__XXX
SG_ GearLockoutLampStatus : 20|2@1+ (1,0) [0|3] "" Vector__XXX
SG_ SlowVesselModeLampStatus : 22|2@1+ (1,0) [0|3] "" Vector__XXX
SG_ MarineHeavySeaModeEnable : 24|2@1+ (1,0) [0|3] "" Vector__XXX

BO_ 2566621694 EFL_P13: 8 Vector__XXX
SG_ EngineOilPressure2 : 0|8@1+ (4,0) [0|1000] "kPa" Vector__XXX

BO_ 2365295358 HVESSD11: 8 Vector__XXX
SG_ HVES1BusVltgNegToChssGrndVoltage : 0|16@1+ (0.05,0) [0|3212.75] "V" Vector__XXX
SG_ HVES1VltgLvlNegToChssGrndVoltage : 16|16@1+ (0.05,0) [0|3212.75] "V" Vector__XXX

BO_ 2566622206 EMIH: 8 Vector__XXX
SG_ EconomyModeTotalHoursInactive : 0|32@1+ (0.05,0) [0|210554060.75] "h" Vector__XXX
SG_ EconomyModeTripHoursInactive : 32|32@1+ (0.05,0) [0|210554060.75] "h" Vector__XXX

BO_ 2566622462 EMEIFSR: 8 Vector__XXX
SG_ EconomyMdeEstInstFuelSavingsRate : 0|16@1+ (0.05,0) [0|3212.75] "l/h" Vector__XXX
SG_ EconyMdeEstInstFuelSvngRatePrcnt : 16|16@1+ (0.0025,0) [0|160.6375] "%" Vector__XXX

BO_ 2566622718 EMAH: 8 Vector__XXX
SG_ EconomyModeTotalHoursActive : 0|32@1+ (0.05,0) [0|210554060.75] "h" Vector__XXX
SG_ EconomyModeTripHoursActive : 32|32@1+ (0.05,0) [0|210554060.75] "h" Vector__XXX

BO_ 2566622974 EMFU: 8 Vector__XXX
SG_ EconomyModeTotalFuelUsed : 0|32@1+ (0.5,0) [0|2105540607.5] "l" Vector__XXX
SG_ EconomyModeTripFuelUsed : 32|32@1+ (0.5,0) [0|2105540607.5] "l" Vector__XXX

BO_ 2566623230 EMEFS: 8 Vector__XXX
SG_ EconmyModeTotalEstFuelSaved : 0|32@1+ (0.5,0) [0|2105540607.5] "l" Vector__XXX
SG_ EconmyModeTripEstimatedFuelSaved : 32|32@1+ (0.5,0) [0|2105540607.5] "l" Vector__XXX

BO_ 2365296894 DCDC4V: 8 Vector__XXX
SG_ DCDC4CtrllerInputIgnitionVoltage : 0|16@1+ (0.05,0) [0|3212.75] "V" Vector__XXX
SG_ DCDC4ControllerInputSLIVoltage : 16|16@1+ (0.05,0) [0|3212.75] "V" Vector__XXX

BO_ 2365297150 DCDC3V: 8 Vector__XXX
SG_ DCDC3CtrllerInputIgnitionVoltage : 0|16@1+ (0.05,0) [0|3212.75] "V" Vector__XXX
SG_ DCDC3ControllerInputSLIVoltage : 16|16@1+ (0.05,0) [0|3212.75] "V" Vector__XXX

BO_ 2365297406 DCDC2V: 8 Vector__XXX
SG_ DCDC2CtrllerInputIgnitionVoltage : 0|16@1+ (0.05,0) [0|3212.75] "V" Vector__XXX
SG_ DCDC2ControllerInputSLIVoltage : 16|16@1+ (0.05,0) [0|3212.75] "V" Vector__XXX

BO_ 2365297662 DCDC1V: 8 Vector__XXX
SG_ DCDC1CtrllerInputIgnitionVoltage : 0|16@1+ (0.05,0) [0|3212.75] "V" Vector__XXX
SG_ DCDC1ControllerInputSLIVoltage : 16|16@1+ (0.05,0) [0|3212.75] "V" Vector__XXX

BO_ 2566624510 EEC22: 8 Vector__XXX
SG_ EngExhstGsRecirc1CoolIntkPress : 0|16@1+ (5,0) [0|321275] "kPa" Vector__XXX

BO_ 2566624766 HOURS2: 8 Vector__XXX
SG_ EngIdleManagementActvTotalTime : 0|32@1+ (0.05,0) [0|210554060.75] "h" Vector__XXX

BO_ 2566625022 EI3: 8 Vector__XXX
SG_ InstntnsEstEngPowerRateLimit : 0|16@1+ (0.125,0) [0|8031.875] "kW/s" Vector__XXX

BO_ 2566625278 VEP15: 8 Vector__XXX
SG_ SLIBattPack1Battry1CapacitySttng : 0|16@1+ (1,0) [0|64255] "Ah" Vector__XXX
SG_ SLIBattPack1Battry2CapacitySttng : 16|16@1+ (1,0) [0|64255] "Ah" Vector__XXX
SG_ SLIBattPack1Battry3CapacitySttng : 32|16@1+ (1,0) [0|64255] "Ah" Vector__XXX
SG_ SLIBattPack1Battry4CapacitySttng : 48|16@1+ (1,0) [0|64255] "Ah" Vector__XXX

BO_ 2633734398 EO2: 8 Vector__XXX
SG_ EngineActualExhaust2Oxygen : 0|16@1+ (0.0025,0) [0|160.6375] "%" Vector__XXX

BO_ 2566625790 DCAC_AI1_T: 8 Vector__XXX
SG_ DCACAccssryInvert1CtrllerTemp : 0|8@1+ (1,-40) [-40|210] "deg C" Vector__XXX
SG_ DCACAccryInv1InvertElctrFlTemp : 8|8@1+ (1,-40) [-40|210] "deg C" Vector__XXX
SG_ DCACAccryInvert1PwrElctrncsTemp : 16|8@1+ (1,-40) [-40|210] "deg C" Vector__XXX
SG_ DCACAccssryInvert1CoolntTemp : 24|8@1+ (1,-40) [-40|210] "deg C" Vector__XXX
SG_ DCACAccssryInvert1CoolntOutTemp : 32|8@1+ (1,-40) [-40|210] "deg C" Vector__XXX

BO_ 2365299454 DCAC_AI1_DCL: 8 Vector__XXX
SG_ DCACAccryInv1DCSdeVltgMinLmtRq : 0|16@1+ (0.05,0) [0|3212.75] "V" Vector__XXX
SG_ DCACAccryInvert1DCSdeCurMaxLmtRq : 16|16@1+ (0.05,0) [0|3212.75] "A" Vector__XXX
SG_ DCACAccryInv1DCSdeVltgMaxLmtRq : 32|16@1+ (0.05,0) [0|3212.75] "V" Vector__XXX
SG_ DCACAccryInvert1DCSdeCurMinLmtRq : 48|16@1+ (0.05,-3212.75) [-3212.75|0] "A" Vector__XXX

BO_ 2365299710 DCAC_AI1_ACL: 8 Vector__XXX
SG_ DCACAccInv1ACSdeRMSVltgMaxLmtRq : 0|16@1+ (0.03125,0) [0|2007.96875] "Vrms" Vector__XXX
SG_ DCACAccryInv1ACSdeRMSCurMaxLmtRq : 16|16@1+ (0.03125,0) [0|2007.96875] "Arms" Vector__XXX
SG_ DCACAccryInvert1ACSdeDefltFreqRq : 32|8@1+ (1,0) [0|250] "Hz" Vector__XXX

BO_ 2566626558 DCAC_AI1_CFG1: 13 Vector__XXX
SG_ DCACAccryInv1DCSdeVltgMnLmtSttng : 0|16@1+ (0.05,0) [0|3212.75] "V" Vector__XXX
SG_ DCACAccryInv1DCSdeCurMaxLmtSttng : 16|16@1+ (0.05,0) [0|3212.75] "A" Vector__XXX
SG_ DCACAccInv1ACSdeRMSVltgMaxLmtStt : 32|16@1+ (0.03125,0) [0|2007.96875] "Vrms" Vector__XXX
SG_ DCACAccInv1ACSdeRMSCurMaxLmtStt : 48|16@1+ (0.03125,0) [0|2007.96875] "Arms" Vector__XXX
SG_ DCACAccryInv1DCSdeVltgMaxLmtStt : 64|16@1+ (0.05,0) [0|3212.75] "V" Vector__XXX
SG_ DCACAccryInv1DCSdeCurMinLmtSttng : 80|16@1+ (0.05,-3212.75) [-3212.75|0] "A" Vector__XXX
SG_ DCACAccryInv1ACSdeDefFreqCmdStt : 96|8@1+ (1,0) [0|250] "Hz" Vector__XXX

BO_ 2566626814 DCAC_AI1_LD: 8 Vector__XXX
SG_ DCACAccssryInvert1TtlDCInptChrg : 0|32@1+ (100,0) [0|421108121500] "Ah" Vector__XXX
SG_ DCACAccryInvert1TtlDCInptEnergy : 32|32@1+ (100,0) [0|421108121500] "Watt-hour" Vector__XXX

BO_ 2566627070 DCAC_AI2_T: 8 Vector__XXX
SG_ DCACAccssryInvert2CtrllerTemp : 0|8@1+ (1,-40) [-40|210] "deg C" Vector__XXX
SG_ DCACAccryInv2InvertElctrFlTemp : 8|8@1+ (1,-40) [-40|210] "deg C" Vector__XXX
SG_ DCACAccryInvert2PwrElctrncsTemp : 16|8@1+ (1,-40) [-40|210] "deg C" Vector__XXX
SG_ DCACAccssryInvert2CoolntTemp : 24|8@1+ (1,-40) [-40|210] "deg C" Vector__XXX
SG_ DCACAccssryInvert2CoolntOutTemp : 32|8@1+ (1,-40) [-40|210] "deg C" Vector__XXX

BO_ 2365300734 DCAC_AI2_DCL: 8 Vector__XXX
SG_ DCACAccryInv2DCSdeVltgMinLmtRq : 0|16@1+ (0.05,0) [0|3212.75] "V" Vector__XXX
SG_ DCACAccryInvert2DCSdeCurMaxLmtRq : 16|16@1+ (0.05,0) [0|3212.75] "A" Vector__XXX
SG_ DCACAccryInv2DCSdeVltgMaxLmtRq : 32|16@1+ (0.05,0) [0|3212.75] "V" Vector__XXX
SG_ DCACAccryInvert2DCSdeCurMinLmtRq : 48|16@1+ (0.05,-3212.75) [-3212.75|0] "A" Vector__XXX

BO_ 2365300990 DCAC_AI2_ACL: 8 Vector__XXX
SG_ DCACAccInv2ACSdeRMSVltgMaxLmtRq : 0|16@1+ (0.03125,0) [0|2007.96875] "Vrms" Vector__XXX
SG_ DCACAccryInv2ACSdeRMSCurMaxLmtRq : 16|16@1+ (0.03125,0) [0|2007.96875] "Arms" Vector__XXX
SG_ DCACAccryInvert2ACSdeDefltFreqRq : 32|8@1+ (1,0) [0|250] "Hz" Vector__XXX

BO_ 2566627838 DCAC_AI2_CFG1: 13 Vector__XXX
SG_ DCACAccryInv2DCSdeVltgMnLmtSttng : 0|16@1+ (0.05,0) [0|3212.75] "V" Vector__XXX
SG_ DCACAccryInv2DCSdeCurMaxLmtSttng : 16|16@1+ (0.05,0) [0|3212.75] "A" Vector__XXX
SG_ DCACAccInv2ACSdeRMSVltgMaxLmtStt : 32|16@1+ (0.03125,0) [0|2007.96875] "Vrms" Vector__XXX
SG_ DCACAccInv2ACSdeRMSCurMaxLmtStt : 48|16@1+ (0.03125,0) [0|2007.96875] "Arms" Vector__XXX
SG_ DCACAccryInv2DCSdeVltgMaxLmtStt : 64|16@1+ (0.05,0) [0|3212.75] "V" Vector__XXX
SG_ DCACAccryInv2DCSdeCurMinLmtSttng : 80|16@1+ (0.05,-3212.75) [-3212.75|0] "A" Vector__XXX
SG_ DCACAccryInv2ACSdeDefFreqCmdStt : 96|8@1+ (1,0) [0|250] "Hz" Vector__XXX

BO_ 2566628094 DCAC_AI2_LD: 8 Vector__XXX
SG_ DCACAccssryInvert2TtlDCInptChrg : 0|32@1+ (100,0) [0|421108121500] "Ah" Vector__XXX
SG_ DCACAccryInvert2TtlDCInptEnergy : 32|32@1+ (100,0) [0|421108121500] "Watt-hour" Vector__XXX

BO_ 2566628350 DCAC_AI3_T: 8 Vector__XXX
SG_ DCACAccssryInvert3CtrllerTemp : 0|8@1+ (1,-40) [-40|210] "deg C" Vector__XXX
SG_ DCACAccryInv3InvertElctrFlTemp : 8|8@1+ (1,-40) [-40|210] "deg C" Vector__XXX
SG_ DCACAccryInvert3PwrElctrncsTemp : 16|8@1+ (1,-40) [-40|210] "deg C" Vector__XXX
SG_ DCACAccssryInvert3CoolntTemp : 24|8@1+ (1,-40) [-40|210] "deg C" Vector__XXX
SG_ DCACAccssryInvert3CoolntOutTemp : 32|8@1+ (1,-40) [-40|210] "deg C" Vector__XXX

BO_ 2365302014 DCAC_AI3_DCL: 8 Vector__XXX
SG_ DCACAccryInv3DCSdeVltgMinLmtRq : 0|16@1+ (0.05,0) [0|3212.75] "V" Vector__XXX
SG_ DCACAccryInvert3DCSdeCurMaxLmtRq : 16|16@1+ (0.05,0) [0|3212.75] "A" Vector__XXX
SG_ DCACAccryInv3DCSdeVltgMaxLmtRq : 32|16@1+ (0.05,0) [0|3212.75] "V" Vector__XXX
SG_ DCACAccryInvert3DCSdeCurMinLmtRq : 48|16@1+ (0.05,-3212.75) [-3212.75|0] "A" Vector__XXX

BO_ 2365302270 DCAC_AI3_ACL: 8 Vector__XXX
SG_ DCACAccInv3ACSdeRMSVltgMaxLmtRq : 0|16@1+ (0.03125,0) [0|2007.96875] "Vrms" Vector__XXX
SG_ DCACAccryInv3ACSdeRMSCurMaxLmtRq : 16|16@1+ (0.03125,0) [0|2007.96875] "Arms" Vector__XXX
SG_ DCACAccryInvert3ACSdeDefltFreqRq : 32|8@1+ (1,0) [0|250] "Hz" Vector__XXX

BO_ 2566629118 DCAC_AI3_CFG1: 13 Vector__XXX
SG_ DCACAccryInv3DCSdeVltgMnLmtSttng : 0|16@1+ (0.05,0) [0|3212.75] "V" Vector__XXX
SG_ DCACAccryInv3DCSdeCurMaxLmtSttng : 16|16@1+ (0.05,0) [0|3212.75] "A" Vector__XXX
SG_ DCACAccInv3ACSdeRMSVltgMaxLmtStt : 32|16@1+ (0.03125,0) [0|2007.96875] "Vrms" Vector__XXX
SG_ DCACAccInv3ACSdeRMSCurMaxLmtStt : 48|16@1+ (0.03125,0) [0|2007.96875] "Arms" Vector__XXX
SG_ DCACAccryInv3DCSdeVltgMaxLmtStt : 64|16@1+ (0.05,0) [0|3212.75] "V" Vector__XXX
SG_ DCACAccryInv3DCSdeCurMinLmtSttng : 80|16@1+ (0.05,-3212.75) [-3212.75|0] "A" Vector__XXX
SG_ DCACAccryInv3ACSdeDefFreqCmdStt : 96|8@1+ (1,0) [0|250] "Hz" Vector__XXX

BO_ 2566629374 DCAC_AI3_LD: 8 Vector__XXX
SG_ DCACAccssryInvert3TtlDCInptChrg : 0|32@1+ (100,0) [0|421108121500] "Ah" Vector__XXX
SG_ DCACAccryInvert3TtlDCInptEnergy : 32|32@1+ (100,0) [0|421108121500] "Watt-hour" Vector__XXX

BO_ 2566629630 DCAC_AI4_T: 8 Vector__XXX
SG_ DCACAccssryInvert4CtrllerTemp : 0|8@1+ (1,-40) [-40|210] "deg C" Vector__XXX
SG_ DCACAccryInv4InvertElctrFlTemp : 8|8@1+ (1,-40) [-40|210] "deg C" Vector__XXX
SG_ DCACAccryInvert4PwrElctrncsTemp : 16|8@1+ (1,-40) [-40|210] "deg C" Vector__XXX
SG_ DCACAccssryInvert4CoolntTemp : 24|8@1+ (1,-40) [-40|210] "deg C" Vector__XXX
SG_ DCACAccssryInvert4CoolntOutTemp : 32|8@1+ (1,-40) [-40|210] "deg C" Vector__XXX

BO_ 2365303294 DCAC_AI4_DCL: 8 Vector__XXX
SG_ DCACAccryInv4DCSdeVltgMinLmtRq : 0|16@1+ (0.05,0) [0|3212.75] "V" Vector__XXX
SG_ DCACAccryInvert4DCSdeCurMaxLmtRq : 16|16@1+ (0.05,0) [0|3212.75] "A" Vector__XXX
SG_ DCACAccryInv4DCSdeVltgMaxLmtRq : 32|16@1+ (0.05,0) [0|3212.75] "V" Vector__XXX
SG_ DCACAccryInvert4DCSdeCurMinLmtRq : 48|16@1+ (0.05,-3212.75) [-3212.75|0] "A" Vector__XXX

BO_ 2365303550 DCAC_AI4_ACL: 8 Vector__XXX
SG_ DCACAccInv4ACSdeRMSVltgMaxLmtRq : 0|16@1+ (0.03125,0) [0|2007.96875] "Vrms" Vector__XXX
SG_ DCACAccryInv4ACSdeRMSCurMaxLmtRq : 16|16@1+ (0.03125,0) [0|2007.96875] "Arms" Vector__XXX
SG_ DCACAccryInvert4ACSdeDefltFreqRq : 32|8@1+ (1,0) [0|250] "Hz" Vector__XXX

BO_ 2566630398 DCAC_AI4_CFG1: 13 Vector__XXX
SG_ DCACAccryInv4DCSdeVltgMnLmtSttng : 0|16@1+ (0.05,0) [0|3212.75] "V" Vector__XXX
SG_ DCACAccryInv4DCSdeCurMaxLmtSttng : 16|16@1+ (0.05,0) [0|3212.75] "A" Vector__XXX
SG_ DCACAccInv4ACSdeRMSVltgMaxLmtStt : 32|16@1+ (0.03125,0) [0|2007.96875] "Vrms" Vector__XXX
SG_ DCACAccInv4ACSdeRMSCurMaxLmtStt : 48|16@1+ (0.03125,0) [0|2007.96875] "Arms" Vector__XXX
SG_ DCACAccryInv4DCSdeVltgMaxLmtStt : 64|16@1+ (0.05,0) [0|3212.75] "V" Vector__XXX
SG_ DCACAccryInv4DCSdeCurMinLmtSttng : 80|16@1+ (0.05,-3212.75) [-3212.75|0] "A" Vector__XXX
SG_ DCACAccryInv4ACSdeDefFreqCmdStt : 96|8@1+ (1,0) [0|250] "Hz" Vector__XXX

BO_ 2566630654 DCAC_AI4_LD: 8 Vector__XXX
SG_ DCACAccssryInvert4TtlDCInptChrg : 0|32@1+ (100,0) [0|421108121500] "Ah" Vector__XXX
SG_ DCACAccryInvert4TtlDCInptEnergy : 32|32@1+ (100,0) [0|421108121500] "Watt-hour" Vector__XXX

BO_ 2566630910 DCAC_AI5_T: 8 Vector__XXX
SG_ DCACAccssryInvert5CtrllerTemp : 0|8@1+ (1,-40) [-40|210] "deg C" Vector__XXX
SG_ DCACAccryInv5InvertElctrFlTemp : 8|8@1+ (1,-40) [-40|210] "deg C" Vector__XXX
SG_ DCACAccryInvert5PwrElctrncsTemp : 16|8@1+ (1,-40) [-40|210] "deg C" Vector__XXX
SG_ DCACAccssryInvert5CoolntTemp : 24|8@1+ (1,-40) [-40|210] "deg C" Vector__XXX
SG_ DCACAccssryInvert5CoolntOutTemp : 32|8@1+ (1,-40) [-40|210] "deg C" Vector__XXX

BO_ 2365304574 DCAC_AI5_DCL: 8 Vector__XXX
SG_ DCACAccryInv5DCSdeVltgMinLmtRq : 0|16@1+ (0.05,0) [0|3212.75] "V" Vector__XXX
SG_ DCACAccryInvert5DCSdeCurMaxLmtRq : 16|16@1+ (0.05,0) [0|3212.75] "A" Vector__XXX
SG_ DCACAccryInv5DCSdeVltgMaxLmtRq : 32|16@1+ (0.05,0) [0|3212.75] "V" Vector__XXX
SG_ DCACAccryInvert5DCSdeCurMinLmtRq : 48|16@1+ (0.05,-3212.75) [-3212.75|0] "A" Vector__XXX

BO_ 2365304830 DCAC_AI5_ACL: 8 Vector__XXX
SG_ DCACAccInv5ACSdeRMSVltgMaxLmtRq : 0|16@1+ (0.03125,0) [0|2007.96875] "Vrms" Vector__XXX
SG_ DCACAccryInv5ACSdeRMSCurMaxLmtRq : 16|16@1+ (0.03125,0) [0|2007.96875] "Arms" Vector__XXX
SG_ DCACAccryInvert5ACSdeDefltFreqRq : 32|8@1+ (1,0) [0|250] "Hz" Vector__XXX

BO_ 2566631678 DCAC_AI5_CFG1: 13 Vector__XXX
SG_ DCACAccryInv5DCSdeVltgMnLmtSttng : 0|16@1+ (0.05,0) [0|3212.75] "V" Vector__XXX
SG_ DCACAccryInv5DCSdeCurMaxLmtSttng : 16|16@1+ (0.05,0) [0|3212.75] "A" Vector__XXX
SG_ DCACAccInv5ACSdeRMSVltgMaxLmtStt : 32|16@1+ (0.03125,0) [0|2007.96875] "Vrms" Vector__XXX
SG_ DCACAccInv5ACSdeRMSCurMaxLmtStt : 48|16@1+ (0.03125,0) [0|2007.96875] "Arms" Vector__XXX
SG_ DCACAccryInv5DCSdeVltgMaxLmtStt : 64|16@1+ (0.05,0) [0|3212.75] "V" Vector__XXX
SG_ DCACAccryInv5DCSdeCurMinLmtSttng : 80|16@1+ (0.05,-3212.75) [-3212.75|0] "A" Vector__XXX
SG_ DCACAccryInv5ACSdeDefFreqCmdStt : 96|8@1+ (1,0) [0|250] "Hz" Vector__XXX

BO_ 2566631934 DCAC_AI5_LD: 8 Vector__XXX
SG_ DCACAccssryInvert5TtlDCInptChrg : 0|32@1+ (100,0) [0|421108121500] "Ah" Vector__XXX
SG_ DCACAccryInvert5TtlDCInptEnergy : 32|32@1+ (100,0) [0|421108121500] "Watt-hour" Vector__XXX

BO_ 2566632190 WSPSCS: 8 Vector__XXX
SG_ WllStimultnPmpSuctPrsClbrtnSetPt : 0|4@1+ (1,0) [0|15] "" Vector__XXX
SG_ WllStimuPmpSuctPrsClbrtnSetPtSt : 4|2@1+ (1,0) [0|3] "" Vector__XXX
SG_ WllStimuPmpDisChrgPrsClbrtnSetPt : 8|4@1+ (1,0) [0|15] "" Vector__XXX
SG_ WStimuPmpDisChrgPrsClbrtnSetPtSt : 12|2@1+ (1,0) [0|3] "" Vector__XXX

BO_ 2566632446 WSPFV: 8 Vector__XXX
SG_ WellStimulationPmpTotalFldPumped : 0|32@1+ (0.5,0) [0|2105540607.5] "l" Vector__XXX
SG_ WellStimulationPumpTripFldPumped : 32|32@1+ (0.5,0) [0|2105540607.5] "l" Vector__XXX

BO_ 2566632702 WSPSN: 200 Vector__XXX
SG_ WellStimulationPmpPwrEndSerialNo : 7|1600@0+ (1,0) [0|0] "ASCII" Vector__XXX
SG_ WellStimulationPmpFldEndSerialNo : 7|1600@0+ (1,0) [0|0] "ASCII" Vector__XXX

BO_ 2566632958 WSPH2: 8 Vector__XXX
SG_ WellStimulationPumpFldEndTripHrs : 0|32@1+ (1,0) [0|4211081215] "s" Vector__XXX
SG_ WellStimulationPumpPwrEndTripHrs : 32|32@1+ (1,0) [0|4211081215] "s" Vector__XXX

BO_ 2566633214 AT1OG4: 8 Vector__XXX
SG_ Afttreatment1OtltOxygnPmpingCurr : 0|16@1+ (0.001,-32.127) [-32.127|32.128] "mA" Vector__XXX

BO_ 2566633470 AT1IG4: 8 Vector__XXX
SG_ Afttreatment1IntkOxygnPmpingCurr : 0|16@1+ (0.001,-32.127) [-32.127|32.128] "mA" Vector__XXX

BO_ 2566633726 DCDC4LD: 16 Vector__XXX
SG_ DCDC4TotalHighSideEnergy : 0|32@1+ (100,0) [0|421108121500] "Watt-hour" Vector__XXX
SG_ DCDC4TotalLowSideEnergy : 32|32@1+ (100,0) [0|421108121500] "Watt-hour" Vector__XXX
SG_ DCDC4TotalHighSideCharge : 64|32@1+ (100,0) [0|421108121500] "Ah" Vector__XXX
SG_ DCDC4TotalLowSideCharge : 96|32@1+ (100,0) [0|421108121500] "Ah" Vector__XXX

BO_ 2566633982 DCDC4CFG1: 19 Vector__XXX
SG_ DCDC4HghSideVoltageMinLmtSetting : 0|16@1+ (0.05,0) [0|3212.75] "V" Vector__XXX
SG_ DCDC4HghSideVoltageMaxLmtSetting : 16|16@1+ (0.05,0) [0|3212.75] "V" Vector__XXX
SG_ DCDC4HghSideCurrMaxLmtSetting : 32|16@1+ (0.05,0) [0|3212.75] "A" Vector__XXX
SG_ DCDC4LowSideVoltageMinLmtSetting : 48|16@1+ (0.01,0) [0|642.55] "V" Vector__XXX
SG_ DCDC4LowSideVoltageMaxLmtSetting : 64|16@1+ (0.01,0) [0|642.55] "V" Vector__XXX
SG_ DCDC4LowSideCurrMaxLmtSetting : 80|16@1+ (0.05,0) [0|3212.75] "A" Vector__XXX
SG_ DCDC4SLIBattTermnlVltgMaxLmtStt : 96|16@1+ (0.01,0) [0|642.55] "V" Vector__XXX
SG_ DCDC4SLIBattTermChrgCurMaxLmtStt : 112|16@1+ (0.05,0) [0|3212.75] "A" Vector__XXX
SG_ DCDC4SLIBattryTempMaxLmtSttng : 128|8@1+ (1,-40) [-40|210] "deg C" Vector__XXX
SG_ DCDC4LowSdeVoltageBuckDefltSttng : 136|16@1+ (0.01,0) [0|642.55] "V" Vector__XXX

BO_ 2365307646 DCDC4SBL: 8 Vector__XXX
SG_ DCDC4SLIBattryTermnlVltgMaxLmtRq : 0|16@1+ (0.01,0) [0|642.55] "V" Vector__XXX
SG_ DCDC4SLIBattTermChrgCurMaxLmtRq : 16|16@1+ (0.05,0) [0|3212.75] "A" Vector__XXX
SG_ DCDC4SLIBattryTempMaxLmtRq : 32|8@1+ (1,-40) [-40|210] "deg C" Vector__XXX

BO_ 2365307902 DCDC4T: 8 Vector__XXX
SG_ DCDC4ConverterTemperature : 0|8@1+ (1,-40) [-40|210] "deg C" Vector__XXX
SG_ DCDC4CnvElctrncFilterTemperature : 8|8@1+ (1,-40) [-40|210] "deg C" Vector__XXX
SG_ DCDC4PowerElectronicsTemperature : 16|8@1+ (1,-40) [-40|210] "deg C" Vector__XXX
SG_ DCDC4CoolantInTemperature : 24|8@1+ (1,-40) [-40|210] "deg C" Vector__XXX
SG_ DCDC4CoolantOutTemperature : 32|8@1+ (1,-40) [-40|210] "deg C" Vector__XXX

BO_ 2365308158 DCDC4LL: 8 Vector__XXX
SG_ DCDC4LowSideVoltageMinLmtRequest : 0|16@1+ (0.01,0) [0|642.55] "V" Vector__XXX
SG_ DCDC4LowSideVoltageMaxLmtRequest : 16|16@1+ (0.01,0) [0|642.55] "V" Vector__XXX
SG_ DCDC4LowSideCurrMaxLmtRequest : 32|16@1+ (0.05,0) [0|3212.75] "A" Vector__XXX

BO_ 2365308414 DCDC4HL: 8 Vector__XXX
SG_ DCDC4HghSideVoltageMinLmtRequest : 0|16@1+ (0.05,0) [0|3212.75] "V" Vector__XXX
SG_ DCDC4HghSideVoltageMaxLmtRequest : 16|16@1+ (0.05,0) [0|3212.75] "V" Vector__XXX
SG_ DCDC4HghSideCurrMaxLmtRequest : 32|16@1+ (0.05,0) [0|3212.75] "A" Vector__XXX

BO_ 2566635262 DCDC3LD: 16 Vector__XXX
SG_ DCDC3TotalHighSideEnergy : 0|32@1+ (100,0) [0|421108121500] "Watt-hour" Vector__XXX
SG_ DCDC3TotalLowSideEnergy : 32|32@1+ (100,0) [0|421108121500] "Watt-hour" Vector__XXX
SG_ DCDC3TotalHighSideCharge : 64|32@1+ (100,0) [0|421108121500] "Ah" Vector__XXX
SG_ DCDC3TotalLowSideCharge : 96|32@1+ (100,0) [0|421108121500] "Ah" Vector__XXX

BO_ 2566635518 DCDC3CFG1: 19 Vector__XXX
SG_ DCDC3HghSideVoltageMinLmtSetting : 0|16@1+ (0.05,0) [0|3212.75] "V" Vector__XXX
SG_ DCDC3HghSideVoltageMaxLmtSetting : 16|16@1+ (0.05,0) [0|3212.75] "V" Vector__XXX
SG_ DCDC3HghSideCurrMaxLmtSetting : 32|16@1+ (0.05,0) [0|3212.75] "A" Vector__XXX
SG_ DCDC3LowSideVoltageMinLmtSetting : 48|16@1+ (0.01,0) [0|642.55] "V" Vector__XXX
SG_ DCDC3LowSideVoltageMaxLmtSetting : 64|16@1+ (0.01,0) [0|642.55] "V" Vector__XXX
SG_ DCDC3LowSideCurrMaxLmtSetting : 80|16@1+ (0.05,0) [0|3212.75] "A" Vector__XXX
SG_ DCDC3SLIBattTermnlVltgMaxLmtStt : 96|16@1+ (0.01,0) [0|642.55] "V" Vector__XXX
SG_ DCDC3SLIBattTermChrgCurMaxLmtStt : 112|16@1+ (0.05,0) [0|3212.75] "A" Vector__XXX
SG_ DCDC3SLIBattryTempMaxLmtSttng : 128|8@1+ (1,-40) [-40|210] "deg C" Vector__XXX
SG_ DCDC3LowSdeVoltageBuckDefltSttng : 136|16@1+ (0.01,0) [0|642.55] "V" Vector__XXX

BO_ 2365309182 DCDC3SBL: 8 Vector__XXX
SG_ DCDC3SLIBattryTermnlVltgMaxLmtRq : 0|16@1+ (0.01,0) [0|642.55] "V" Vector__XXX
SG_ DCDC3SLIBattTermChrgCurMaxLmtRq : 16|16@1+ (0.05,0) [0|3212.75] "A" Vector__XXX
SG_ DCDC3SLIBattryTempMaxLmtRq : 32|8@1+ (1,-40) [-40|210] "deg C" Vector__XXX

BO_ 2365309438 DCDC3T: 8 Vector__XXX
SG_ DCDC3ConverterTemperature : 0|8@1+ (1,-40) [-40|210] "deg C" Vector__XXX
SG_ DCDC3CnvElctrncFilterTemperature : 8|8@1+ (1,-40) [-40|210] "deg C" Vector__XXX
SG_ DCDC3PowerElectronicsTemperature : 16|8@1+ (1,-40) [-40|210] "deg C" Vector__XXX
SG_ DCDC3CoolantInTemperature : 24|8@1+ (1,-40) [-40|210] "deg C" Vector__XXX
SG_ DCDC3CoolantOutTemperature : 32|8@1+ (1,-40) [-40|210] "deg C" Vector__XXX

BO_ 2365309694 DCDC3LL: 8 Vector__XXX
SG_ DCDC3LowSideVoltageMinLmtRequest : 0|16@1+ (0.01,0) [0|642.55] "V" Vector__XXX
SG_ DCDC3LowSideVoltageMaxLmtRequest : 16|16@1+ (0.01,0) [0|642.55] "V" Vector__XXX
SG_ DCDC3LowSideCurrMaxLmtRequest : 32|16@1+ (0.05,0) [0|3212.75] "A" Vector__XXX

BO_ 2365309950 DCDC3HL: 8 Vector__XXX
SG_ DCDC3HghSideVoltageMinLmtRequest : 0|16@1+ (0.05,0) [0|3212.75] "V" Vector__XXX
SG_ DCDC3HghSideVoltageMaxLmtRequest : 16|16@1+ (0.05,0) [0|3212.75] "V" Vector__XXX
SG_ DCDC3HghSideCurrMaxLmtRequest : 32|16@1+ (0.05,0) [0|3212.75] "A" Vector__XXX

BO_ 2566636798 DCDC2LD: 16 Vector__XXX
SG_ DCDC2TotalHighSideEnergy : 0|32@1+ (100,0) [0|421108121500] "Watt-hour" Vector__XXX
SG_ DCDC2TotalLowSideEnergy : 32|32@1+ (100,0) [0|421108121500] "Watt-hour" Vector__XXX
SG_ DCDC2TotalHighSideCharge : 64|32@1+ (100,0) [0|421108121500] "Ah" Vector__XXX
SG_ DCDC2TotalLowSideCharge : 96|32@1+ (100,0) [0|421108121500] "Ah" Vector__XXX

BO_ 2566637054 DCDC2CFG1: 19 Vector__XXX
SG_ DCDC2HghSideVoltageMinLmtSetting : 0|16@1+ (0.05,0) [0|3212.75] "V" Vector__XXX
SG_ DCDC2HghSideVoltageMaxLmtSetting : 16|16@1+ (0.05,0) [0|3212.75] "V" Vector__XXX
SG_ DCDC2HghSideCurrMaxLmtSetting : 32|16@1+ (0.05,0) [0|3212.75] "A" Vector__XXX
SG_ DCDC2LowSideVoltageMinLmtSetting : 48|16@1+ (0.01,0) [0|642.55] "V" Vector__XXX
SG_ DCDC2LowSideVoltageMaxLmtSetting : 64|16@1+ (0.01,0) [0|642.55] "V" Vector__XXX
SG_ DCDC2LowSideCurrMaxLmtSetting : 80|16@1+ (0.05,0) [0|3212.75] "A" Vector__XXX
SG_ DCDC2SLIBattTermnlVltgMaxLmtStt : 96|16@1+ (0.01,0) [0|642.55] "V" Vector__XXX
SG_ DCDC2SLIBattTermChrgCurMaxLmtStt : 112|16@1+ (0.05,0) [0|3212.75] "A" Vector__XXX
SG_ DCDC2SLIBattryTempMaxLmtSttng : 128|8@1+ (1,-40) [-40|210] "deg C" Vector__XXX
SG_ DCDC2LowSdeVoltageBuckDefltSttng : 136|16@1+ (0.01,0) [0|642.55] "V" Vector__XXX

BO_ 2365310718 DCDC2SBL: 8 Vector__XXX
SG_ DCDC2SLIBattryTermnlVltgMaxLmtRq : 0|16@1+ (0.01,0) [0|642.55] "V" Vector__XXX
SG_ DCDC2SLIBattTermChrgCurMaxLmtRq : 16|16@1+ (0.05,0) [0|3212.75] "A" Vector__XXX
SG_ DCDC2SLIBattryTempMaxLmtRq : 32|8@1+ (1,-40) [-40|210] "deg C" Vector__XXX

BO_ 2365310974 DCDC2T: 8 Vector__XXX
SG_ DCDC2ConverterTemperature : 0|8@1+ (1,-40) [-40|210] "deg C" Vector__XXX
SG_ DCDC2CnvElctrncFilterTemperature : 8|8@1+ (1,-40) [-40|210] "deg C" Vector__XXX
SG_ DCDC2PowerElectronicsTemperature : 16|8@1+ (1,-40) [-40|210] "deg C" Vector__XXX
SG_ DCDC2CoolantInTemperature : 24|8@1+ (1,-40) [-40|210] "deg C" Vector__XXX
SG_ DCDC2CoolantOutTemperature : 32|8@1+ (1,-40) [-40|210] "deg C" Vector__XXX

BO_ 2365311230 DCDC2LL: 8 Vector__XXX
SG_ DCDC2LowSideVoltageMinLmtRequest : 0|16@1+ (0.01,0) [0|642.55] "V" Vector__XXX
SG_ DCDC2LowSideVoltageMaxLmtRequest : 16|16@1+ (0.01,0) [0|642.55] "V" Vector__XXX
SG_ DCDC2LowSideCurrMaxLmtRequest : 32|16@1+ (0.05,0) [0|3212.75] "A" Vector__XXX

BO_ 2365311486 DCDC2HL: 8 Vector__XXX
SG_ DCDC2HghSideVoltageMinLmtRequest : 0|16@1+ (0.05,0) [0|3212.75] "V" Vector__XXX
SG_ DCDC2HghSideVoltageMaxLmtRequest : 16|16@1+ (0.05,0) [0|3212.75] "V" Vector__XXX
SG_ DCDC2HghSideCurrMaxLmtRequest : 32|16@1+ (0.05,0) [0|3212.75] "A" Vector__XXX

BO_ 2566638590 EEPCSI: 8 Vector__XXX
SG_ ExhstPrtcltCtrlSystemDiagTime : 0|32@1+ (1,0) [0|4211081215] "s" Vector__XXX
SG_ ExhstPrtcltCtrlSystemDiagCnt : 32|32@1+ (1,0) [0|4211081215] "" Vector__XXX

BO_ 2566638846 WSPH: 16 Vector__XXX
SG_ WellStimultnPmpMaintenIntvalHrs : 0|32@1+ (1,0) [0|4211081215] "s" Vector__XXX
SG_ WellStimulationPumpValveOpHrs : 32|32@1+ (1,0) [0|4211081215] "s" Vector__XXX
SG_ WellStimulationPumpPackingOpHrs : 64|32@1+ (1,0) [0|4211081215] "s" Vector__XXX
SG_ WellStimulationPmpValveSeatOpHrs : 96|32@1+ (1,0) [0|4211081215] "s" Vector__XXX

BO_ 2566639102 WSPT2: 19 Vector__XXX
SG_ WellStimPmpGrBxOilPrsLoTrshldStt : 0|16@1+ (0.1,0) [0|6425.5] "kPa" Vector__XXX
SG_ WellStimPmpGrBxOilPrsHiTrshldStt : 16|16@1+ (0.1,0) [0|6425.5] "kPa" Vector__XXX
SG_ WellStimPmpGrBxOilTmpLoTrshldStt : 32|8@1+ (1,-40) [-40|210] "deg C" Vector__XXX
SG_ WellStimPmpGrBxOilTmpHiTrshldStt : 40|8@1+ (1,-40) [-40|210] "deg C" Vector__XXX
SG_ WellStimPmpSuctionPrsLoTrshldStt : 48|16@1+ (0.1,-3212.7) [-3212.7|3212.8] "kPa" Vector__XXX
SG_ WellStimPmpSuctionPrsHiTrshldStt : 64|16@1+ (0.1,-3212.7) [-3212.7|3212.8] "kPa" Vector__XXX
SG_ WellStimPmpDisChrgPrsHiTrshldStt : 80|16@1+ (5,0) [0|321275] "kPa" Vector__XXX
SG_ WellStimuPmpCrankSpdLoTrshldStt : 96|16@1+ (0.125,0) [0|8031.875] "rpm" Vector__XXX
SG_ WellStimuPmpCrankSpdHiTrshldStt : 112|16@1+ (0.125,0) [0|8031.875] "rpm" Vector__XXX
SG_ WellStimuPmpRodLoadHiTrshldStt : 128|16@1+ (5,0) [0|321275] "kN" Vector__XXX
SG_ WellStimPmpPlungerFiringOrderStt : 144|4@1+ (1,0) [0|15] "" Vector__XXX

BO_ 2633748222 CRSS: 8 Vector__XXX
SG_ ReceiveSPNsPort : 0|4@1+ (1,0) [0|15] "" Vector__XXX
SG_ ReceiveSPNsPortPendingChangesSt : 4|1@1+ (1,0) [0|1] "" Vector__XXX
SG_ ReceiveSPNsPortCommandStatus : 5|3@1+ (1,0) [0|7] "" Vector__XXX
SG_ ConfigurableReceiveSPN : 16|19@1+ (1,0) [0|524287] "" Vector__XXX
SG_ ConfigurableReceiveSPNDetailedSt : 32|5@1+ (1,0) [0|31] "" Vector__XXX
SG_ ConfigurableReceiveSPNSourceAddr : 40|8@1+ (1,0) [0|255] "" Vector__XXX
SG_ ConfigurableReceiveSPNModifiedSt : 48|2@1+ (1,0) [0|3] "" Vector__XXX

BO_ 2566639614 DCDC1LD: 16 Vector__XXX
SG_ DCDC1TotalHighSideEnergy : 0|32@1+ (100,0) [0|421108121500] "Watt-hour" Vector__XXX
SG_ DCDC1TotalLowSideEnergy : 32|32@1+ (100,0) [0|421108121500] "Watt-hour" Vector__XXX
SG_ DCDC1TotalHighSideCharge : 64|32@1+ (100,0) [0|421108121500] "Ah" Vector__XXX
SG_ DCDC1TotalLowSideCharge : 96|32@1+ (100,0) [0|421108121500] "Ah" Vector__XXX

BO_ 2566639870 DCDC1CFG1: 19 Vector__XXX
SG_ DCDC1HghSideVoltageMinLmtSetting : 0|16@1+ (0.05,0) [0|3212.75] "V" Vector__XXX
SG_ DCDC1HghSideVoltageMaxLmtSetting : 16|16@1+ (0.05,0) [0|3212.75] "V" Vector__XXX
SG_ DCDC1HghSideCurrMaxLmtSetting : 32|16@1+ (0.05,0) [0|3212.75] "A" Vector__XXX
SG_ DCDC1LowSideVoltageMinLmtSetting : 48|16@1+ (0.01,0) [0|642.55] "V" Vector__XXX
SG_ DCDC1LowSideVoltageMaxLmtSetting : 64|16@1+ (0.01,0) [0|642.55] "V" Vector__XXX
SG_ DCDC1LowSideCurrMaxLmtSetting : 80|16@1+ (0.05,0) [0|3212.75] "A" Vector__XXX
SG_ DCDC1SLIBattTermnlVltgMaxLmtStt : 96|16@1+ (0.01,0) [0|642.55] "V" Vector__XXX
SG_ DCDC1SLIBattTermChrgCurMaxLmtStt : 112|16@1+ (0.05,0) [0|3212.75] "A" Vector__XXX
SG_ DCDC1SLIBattryTempMaxLmtSttng : 128|8@1+ (1,-40) [-40|210] "deg C" Vector__XXX
SG_ DCDC1LowSdeVoltageBuckDefltSttng : 136|16@1+ (0.01,0) [0|642.55] "V" Vector__XXX

BO_ 2365313534 DCDC1SBL: 8 Vector__XXX
SG_ DCDC1SLIBattryTermnlVltgMaxLmtRq : 0|16@1+ (0.01,0) [0|642.55] "V" Vector__XXX
SG_ DCDC1SLIBattTermChrgCurMaxLmtRq : 16|16@1+ (0.05,0) [0|3212.75] "A" Vector__XXX
SG_ DCDC1SLIBattryTempMaxLmtRq : 32|8@1+ (1,-40) [-40|210] "deg C" Vector__XXX

BO_ 2566640382 POM: 8 Vector__XXX
SG_ WellStimulationPumpOilViscosity : 0|16@1+ (0.015625,0) [0|1003.984375] "Cp" Vector__XXX
SG_ WellStimulationPumpOilDensity : 16|16@1+ (3.052E-005,0) [0|1.961] "g/cc" Vector__XXX
SG_ WellStimuPmpOilRelDielectricity : 32|16@1+ (0.0001220703125,0) [0|7.844] "" Vector__XXX
SG_ WellStimulationPmpOilTemperature : 48|16@1+ (0.03125,-273) [-273|1734.96875] "deg C" Vector__XXX

BO_ 2633749502 WSPT: 16 Vector__XXX
SG_ WellStimultnPmpFldEndWorkingHrs : 0|32@1+ (1,0) [0|4211081215] "s" Vector__XXX
SG_ WellStimultnPmpPwrEndWorkingHrs : 32|32@1+ (1,0) [0|4211081215] "s" Vector__XXX
SG_ WellStimulationPumpWorkingHours : 64|32@1+ (1,0) [0|4211081215] "s" Vector__XXX
SG_ WellStimulationPumpCycleCount : 96|32@1+ (1,0) [0|4211081215] "" Vector__XXX

BO_ 2633749758 WSPC: 8 Vector__XXX
SG_ WellStimultnPmpPlungerDiameter : 0|16@1+ (1,0) [0|64255] "mm" Vector__XXX
SG_ WellStimulationPumpStrokeLength : 16|16@1+ (1,0) [0|64255] "mm" Vector__XXX
SG_ WellStimulationPumpGearRatio : 32|16@1+ (0.001,0) [0|64.255] "" Vector__XXX
SG_ WellStimulationPumpRatedSpeed : 48|16@1+ (0.125,0) [0|8031.875] "rpm" Vector__XXX

BO_ 2566641150 ACOCF2: 8 Vector__XXX
SG_ AltrntrBearingHeaderIntkPressure : 0|8@1+ (2,0) [0|500] "kPa" Vector__XXX
SG_ AltrntrOilCoolDisChrgPumpPress : 8|8@1+ (2,0) [0|500] "kPa" Vector__XXX
SG_ EngineOilCoolDisChrgPumpPressure : 16|8@1+ (2,0) [0|500] "kPa" Vector__XXX
SG_ EngineOilCoolerIntakeTemperature : 24|8@1+ (1,-40) [-40|210] "deg C" Vector__XXX

BO_ 2566641406 EEC21: 8 Vector__XXX
SG_ EngExhaustManifoldAbsPressure1 : 0|16@1+ (0.1,0) [0|6425.5] "kPa" Vector__XXX
SG_ EngExhaustManifoldAbsPressure2 : 16|16@1+ (0.1,0) [0|6425.5] "kPa" Vector__XXX

BO_ 2633750526 CTPS: 8 Vector__XXX
SG_ TransmitPGNsPort : 0|4@1+ (1,0) [0|15] "" Vector__XXX
SG_ TransmitPGNsPortPendingChangesSt : 4|1@1+ (1,0) [0|1] "" Vector__XXX
SG_ TransmitPGNsPortCommandStatus : 5|3@1+ (1,0) [0|7] "" Vector__XXX
SG_ ConfigurableTransmitPGN : 16|24@1+ (1,0) [0|16777215] "" Vector__XXX
SG_ ConfigurableTransPGNCurTransmtSt : 40|2@1+ (1,0) [0|3] "" Vector__XXX
SG_ ConfigurableTransPGNPendngChgSt : 42|2@1+ (1,0) [0|3] "" Vector__XXX
SG_ ConfigurableTransmtPGNModifiedSt : 44|2@1+ (1,0) [0|3] "" Vector__XXX

BO_ 2365315326 DCDC1T: 8 Vector__XXX
SG_ DCDC1ConverterTemperature : 0|8@1+ (1,-40) [-40|210] "deg C" Vector__XXX
SG_ DCDC1CnvElctrncFilterTemperature : 8|8@1+ (1,-40) [-40|210] "deg C" Vector__XXX
SG_ DCDC1PowerElectronicsTemperature : 16|8@1+ (1,-40) [-40|210] "deg C" Vector__XXX
SG_ DCDC1CoolantInTemperature : 24|8@1+ (1,-40) [-40|210] "deg C" Vector__XXX
SG_ DCDC1CoolantOutTemperature : 32|8@1+ (1,-40) [-40|210] "deg C" Vector__XXX

BO_ 2365315582 DCDC1LL: 8 Vector__XXX
SG_ DCDC1LowSideVoltageMinLmtRequest : 0|16@1+ (0.01,0) [0|642.55] "V" Vector__XXX
SG_ DCDC1LowSideVoltageMaxLmtRequest : 16|16@1+ (0.01,0) [0|642.55] "V" Vector__XXX
SG_ DCDC1LowSideCurrMaxLmtRequest : 32|16@1+ (0.05,0) [0|3212.75] "A" Vector__XXX

BO_ 2365315838 DCDC1HL: 8 Vector__XXX
SG_ DCDC1HghSideVoltageMinLmtRequest : 0|16@1+ (0.05,0) [0|3212.75] "V" Vector__XXX
SG_ DCDC1HghSideVoltageMaxLmtRequest : 16|16@1+ (0.05,0) [0|3212.75] "V" Vector__XXX
SG_ DCDC1HghSideCurrMaxLmtRequest : 32|16@1+ (0.05,0) [0|3212.75] "A" Vector__XXX

BO_ 2566642686 DM58: 8 Vector__XXX
SG_ TestIdentifier : 0|8@1+ (1,0) [0|255] "" Vector__XXX

BO_ 2566642942 DC4: 8 Vector__XXX
SG_ LockStatusOfDoor21 : 0|2@1+ (1,0) [0|3] "" Vector__XXX
SG_ OpenStatusOfDoor21 : 2|2@1+ (1,0) [0|3] "" Vector__XXX
SG_ EnableStatusOfDoor21 : 4|2@1+ (1,0) [0|3] "" Vector__XXX
SG_ LockStatusOfDoor22 : 6|2@1+ (1,0) [0|3] "" Vector__XXX
SG_ OpenStatusOfDoor22 : 8|2@1+ (1,0) [0|3] "" Vector__XXX
SG_ EnableStatusOfDoor22 : 10|2@1+ (1,0) [0|3] "" Vector__XXX
SG_ LockStatusOfDoor23 : 12|2@1+ (1,0) [0|3] "" Vector__XXX
SG_ OpenStatusOfDoor23 : 14|2@1+ (1,0) [0|3] "" Vector__XXX
SG_ EnableStatusOfDoor23 : 16|2@1+ (1,0) [0|3] "" Vector__XXX
SG_ LockStatusOfDoor24 : 18|2@1+ (1,0) [0|3] "" Vector__XXX
SG_ OpenStatusOfDoor24 : 20|2@1+ (1,0) [0|3] "" Vector__XXX
SG_ EnableStatusOfDoor24 : 22|2@1+ (1,0) [0|3] "" Vector__XXX
SG_ LockStatusOfDoor25 : 24|2@1+ (1,0) [0|3] "" Vector__XXX
SG_ OpenStatusOfDoor25 : 26|2@1+ (1,0) [0|3] "" Vector__XXX
SG_ EnableStatusOfDoor25 : 28|2@1+ (1,0) [0|3] "" Vector__XXX
SG_ LockStatusOfDoor26 : 30|2@1+ (1,0) [0|3] "" Vector__XXX
SG_ OpenStatusOfDoor26 : 32|2@1+ (1,0) [0|3] "" Vector__XXX
SG_ EnableStatusOfDoor26 : 34|2@1+ (1,0) [0|3] "" Vector__XXX
SG_ LockStatusOfDoor27 : 36|2@1+ (1,0) [0|3] "" Vector__XXX
SG_ OpenStatusOfDoor27 : 38|2@1+ (1,0) [0|3] "" Vector__XXX
SG_ EnableStatusOfDoor27 : 40|2@1+ (1,0) [0|3] "" Vector__XXX
SG_ LockStatusOfDoor28 : 42|2@1+ (1,0) [0|3] "" Vector__XXX
SG_ OpenStatusOfDoor28 : 44|2@1+ (1,0) [0|3] "" Vector__XXX
SG_ EnableStatusOfDoor28 : 46|2@1+ (1,0) [0|3] "" Vector__XXX
SG_ LockStatusOfDoor29 : 48|2@1+ (1,0) [0|3] "" Vector__XXX
SG_ OpenStatusOfDoor29 : 50|2@1+ (1,0) [0|3] "" Vector__XXX
SG_ EnableStatusOfDoor29 : 52|2@1+ (1,0) [0|3] "" Vector__XXX
SG_ LockStatusOfDoor30 : 54|2@1+ (1,0) [0|3] "" Vector__XXX
SG_ OpenStatusOfDoor30 : 56|2@1+ (1,0) [0|3] "" Vector__XXX
SG_ EnableStatusOfDoor30 : 58|2@1+ (1,0) [0|3] "" Vector__XXX

BO_ 2566643198 DC3: 8 Vector__XXX
SG_ LockStatusOfDoor11 : 0|2@1+ (1,0) [0|3] "" Vector__XXX
SG_ OpenStatusOfDoor11 : 2|2@1+ (1,0) [0|3] "" Vector__XXX
SG_ EnableStatusOfDoor11 : 4|2@1+ (1,0) [0|3] "" Vector__XXX
SG_ LockStatusOfDoor12 : 6|2@1+ (1,0) [0|3] "" Vector__XXX
SG_ OpenStatusOfDoor12 : 8|2@1+ (1,0) [0|3] "" Vector__XXX
SG_ EnableStatusOfDoor12 : 10|2@1+ (1,0) [0|3] "" Vector__XXX
SG_ LockStatusOfDoor13 : 12|2@1+ (1,0) [0|3] "" Vector__XXX
SG_ OpenStatusOfDoor13 : 14|2@1+ (1,0) [0|3] "" Vector__XXX
SG_ EnableStatusOfDoor13 : 16|2@1+ (1,0) [0|3] "" Vector__XXX
SG_ LockStatusOfDoor14 : 18|2@1+ (1,0) [0|3] "" Vector__XXX
SG_ OpenStatusOfDoor14 : 20|2@1+ (1,0) [0|3] "" Vector__XXX
SG_ EnableStatusOfDoor14 : 22|2@1+ (1,0) [0|3] "" Vector__XXX
SG_ LockStatusOfDoor15 : 24|2@1+ (1,0) [0|3] "" Vector__XXX
SG_ OpenStatusOfDoor15 : 26|2@1+ (1,0) [0|3] "" Vector__XXX
SG_ EnableStatusOfDoor15 : 28|2@1+ (1,0) [0|3] "" Vector__XXX
SG_ LockStatusOfDoor16 : 30|2@1+ (1,0) [0|3] "" Vector__XXX
SG_ OpenStatusOfDoor16 : 32|2@1+ (1,0) [0|3] "" Vector__XXX
SG_ EnableStatusOfDoor16 : 34|2@1+ (1,0) [0|3] "" Vector__XXX
SG_ LockStatusOfDoor17 : 36|2@1+ (1,0) [0|3] "" Vector__XXX
SG_ OpenStatusOfDoor17 : 38|2@1+ (1,0) [0|3] "" Vector__XXX
SG_ EnableStatusOfDoor17 : 40|2@1+ (1,0) [0|3] "" Vector__XXX
SG_ LockStatusOfDoor18 : 42|2@1+ (1,0) [0|3] "" Vector__XXX
SG_ OpenStatusOfDoor18 : 44|2@1+ (1,0) [0|3] "" Vector__XXX
SG_ EnableStatusOfDoor18 : 46|2@1+ (1,0) [0|3] "" Vector__XXX
SG_ LockStatusOfDoor19 : 48|2@1+ (1,0) [0|3] "" Vector__XXX
SG_ OpenStatusOfDoor19 : 50|2@1+ (1,0) [0|3] "" Vector__XXX
SG_ EnableStatusOfDoor19 : 52|2@1+ (1,0) [0|3] "" Vector__XXX
SG_ LockStatusOfDoor20 : 54|2@1+ (1,0) [0|3] "" Vector__XXX
SG_ OpenStatusOfDoor20 : 56|2@1+ (1,0) [0|3] "" Vector__XXX
SG_ EnableStatusOfDoor20 : 58|2@1+ (1,0) [0|3] "" Vector__XXX

BO_ 2566643454 ET6: 8 Vector__XXX
SG_ EngChrgAirCoolIntkCoolntTemp : 0|16@1+ (0.03125,-273) [-273|1734.96875] "deg C" Vector__XXX
SG_ EngChrgAirCoolOtltCoolntTemp : 16|16@1+ (0.03125,-273) [-273|1734.96875] "deg C" Vector__XXX
SG_ EngineIntakeCoolantTemperature : 32|16@1+ (0.03125,-273) [-273|1734.96875] "deg C" Vector__XXX
SG_ EgIntkMfAirSecClntCircClntDffTmp : 48|16@1+ (0.03125,-273) [-273|1734.96875] "deg C" Vector__XXX

BO_ 2566643710 IC3: 8 Vector__XXX
SG_ EngineMixerIntakePressure : 0|16@1+ (0.1,0) [0|6425.5] "kPa" Vector__XXX
SG_ EngineMixer2IntakePressure : 16|16@1+ (0.1,0) [0|6425.5] "kPa" Vector__XXX
SG_ EngineIntakeManifold2AbsPressure : 32|16@1+ (0.1,0) [0|6425.5] "kPa" Vector__XXX
SG_ DsrdEngIntkMnfldPressureHghLmt : 48|16@1+ (0.1,0) [0|6425.5] "kPa" Vector__XXX

CM_ BO_ 2566588414 "NOx Tracking Valid NOx Lifetime Engine Run Time Bins";
CM_ BO_ 2566588670 "NOx Tracking Valid NOx Lifetime Vehicle Distance Bins";
CM_ BO_ 2566588926 "NOx Tracking Valid NOx Lifetime Engine Output Energy Bins";
CM_ BO_ 2566589182 "NOx Tracking Valid NOx Lifetime Engine Out NOx Mass Bins";
CM_ BO_ 2566589438 "NOx Tracking Valid NOx Lifetime System Out NOx Mass Bins";
CM_ BO_ 2566589694 "NOx Tracking Stored 100 Hour Fuel Consumption Bins";
CM_ BO_ 2566589950 "NOx Tracking Stored 100 Hour Engine Run Time Bins";
CM_ BO_ 2566590206 "NOx Tracking Stored 100 Hour Vehicle Distance Bins";
CM_ BO_ 2566590462 "NOx Tracking Stored 100 Hour Engine Output Energy Bins";
CM_ BO_ 2566590718 "NOx Tracking Stored 100 Hour Engine Out NOx Mass Bins";
CM_ BO_ 2566590974 "NOx Tracking Stored 100 Hour System Out NOx Mass Bins";
CM_ BO_ 2566591230 "NOx Tracking Active 100 Hour Fuel Consumption Bins";
CM_ BO_ 2566591486 "NOx Tracking Active 100 Hour Engine Run Time Bins";
CM_ BO_ 2566591742 "NOx Tracking Active 100 Hour Vehicle Distance Bins";
CM_ BO_ 2566591998 "NOx Tracking Active 100 Hour Engine Output Energy Bins";
CM_ BO_ 2566592254 "NOx Tracking Active 100 Hour Engine Out NOx Mass Bins";
CM_ BO_ 2566592510 "NOx Tracking Active 100 Hour System Out NOx Mass Bins";
CM_ BO_ 2365266174 "Motor/Generator 6 Inverter Control 2";
CM_ BO_ 2566593022 "Motor/Generator 6 Inverter Limits Request Power";
CM_ BO_ 2566593278 "Motor/Generator 6 Inverter Limits Request Mechanical";
CM_ BO_ 2566593534 "Motor/Generator 6 Inverter Limits Request DC Side";
CM_ BO_ 2566593790 "Motor/Generator 6 Inverter Isolation Integrity Request";
CM_ BO_ 2365267454 "Motor/Generator 5 Inverter Control 2";
CM_ BO_ 2566594302 "Motor/Generator 5 Inverter Limits Request Power";
CM_ BO_ 2566594558 "Motor/Generator 5 Inverter Limits Request Mechanical";
CM_ BO_ 2566594814 "Motor/Generator 5 Inverter Limits Request DC Side";
CM_ BO_ 2566595070 "Motor/Generator 5 Inverter Isolation Integrity Request";
CM_ BO_ 2365268734 "Motor/Generator 4 Inverter Control 2";
CM_ BO_ 2566595582 "Motor/Generator 4 Inverter Limits Request Power";
CM_ BO_ 2566595838 "Motor/Generator 4 Inverter Limits Request Mechanical";
CM_ BO_ 2566596094 "Motor/Generator 4 Inverter Limits Request DC Side";
CM_ BO_ 2566596350 "Motor/Generator 4 Inverter Isolation Integrity Request";
CM_ BO_ 2365270014 "Motor/Generator 3 Inverter Control 2";
CM_ BO_ 2566596862 "Motor/Generator 3 Inverter Limits Request Power";
CM_ BO_ 2566597118 "Motor/Generator 3 Inverter Limits Request Mechanical";
CM_ BO_ 2566597374 "Motor/Generator 3 Inverter Limits Request DC Side";
CM_ BO_ 2566597630 "Motor/Generator 3 Inverter Isolation Integrity Request";
CM_ BO_ 2566597886 "Diagnostic Readiness 4";
CM_ BO_ 2566598142 "Turbocharger Information 8";
CM_ BO_ 2566598398 "Winch Information 2";
CM_ BO_ 2365272062 "Motor/Generator 6 Inverter Reference 1";
CM_ BO_ 2365272318 "Motor/Generator 6 Inverter Status 1";
CM_ BO_ 2365272574 "Motor/Generator 6 Inverter Reference 2";
CM_ BO_ 2566599422 "Motor/Generator 6 Inverter Temperature";
CM_ BO_ 2566599678 "Motor/Generator 6 Inverter Motor Temperature";
CM_ BO_ 2566599934 "Motor/Generator 6 Inverter Isolation Integrity";
CM_ BO_ 2566600190 "Motor/Generator 6 Inverter Active Power Limits";
CM_ BO_ 2365273854 "Motor/Generator 5 Inverter Reference 1";
CM_ BO_ 2365274110 "Motor/Generator 5 Inverter Status 1";
CM_ BO_ 2365274366 "Motor/Generator 5 Inverter Reference 2";
CM_ BO_ 2566601214 "Motor/Generator 5 Inverter Temperature";
CM_ BO_ 2566601470 "Motor/Generator 5 Inverter Motor Temperature";
CM_ BO_ 2566601726 "Motor/Generator 5 Inverter Isolation Integrity";
CM_ BO_ 2566601982 "Motor/Generator 5 Inverter Active Power Limits";
CM_ BO_ 2365275646 "Motor/Generator 4 Inverter Reference 1";
CM_ BO_ 2365275902 "Motor/Generator 4 Inverter Status 1";
CM_ BO_ 2365276158 "Motor/Generator 4 Inverter Reference 2";
CM_ BO_ 2566603006 "Motor/Generator 4 Inverter Temperature";
CM_ BO_ 2566603262 "Motor/Generator 4 Inverter Motor Temperature";
CM_ BO_ 2566603518 "Motor/Generator 4 Inverter Isolation Integrity";
CM_ BO_ 2566603774 "Motor/Generator 4 Inverter Active Power Limits";
CM_ BO_ 2365277438 "Motor/Generator 3 Inverter Reference 1";
CM_ BO_ 2365277694 "Motor/Generator 3 Inverter Status 1";
CM_ BO_ 2365277950 "Motor/Generator 3 Inverter Reference 2";
CM_ BO_ 2566604798 "Motor/Generator 3 Inverter Temperature";
CM_ BO_ 2566605054 "Motor/Generator 3 Inverter Motor Temperature";
CM_ BO_ 2566605310 "Motor/Generator 3 Inverter Isolation Integrity";
CM_ BO_ 2566605566 "Motor/Generator 3 Inverter Active Power Limits";
CM_ BO_ 2566605822 "Automated Driving System Feedback";
CM_ BO_ 2566606078 "Cab Climate System Information 2";
CM_ BO_ 2566606334 "Maintenance Information";
CM_ BO_ 2499497726 "Hoist Control Information";
CM_ BO_ 2633715710 "High Voltage Energy Storage Pack 6 History";
CM_ BO_ 2566607102 "High Voltage Energy Storage Pack 6 Configuration";
CM_ BO_ 2633716222 "High Voltage Energy Storage Pack 5 History";
CM_ BO_ 2566607614 "High Voltage Energy Storage Pack 5 Configuration";
CM_ BO_ 2633716734 "High Voltage Energy Storage Pack 4 History";
CM_ BO_ 2566608126 "High Voltage Energy Storage Pack 4 Configuration";
CM_ BO_ 2633717246 "High Voltage Energy Storage Pack 3 History";
CM_ BO_ 2566608638 "High Voltage Energy Storage Pack 3 Configuration";
CM_ BO_ 2633717758 "High Voltage Energy Storage Pack 2 History";
CM_ BO_ 2566609150 "High Voltage Energy Storage Pack 2 Configuration";
CM_ BO_ 2633718270 "High Voltage Energy Storage Pack 1 History";
CM_ BO_ 2566609662 "High Voltage Energy Storage Pack 1 Configuration";
CM_ BO_ 2633718782 "Vehicle Fire Suppression System Module 1 Detector Data";
CM_ BO_ 2633719038 "Vehicle Fire Suppression System Module 2 Detector Data";
CM_ BO_ 2633719294 "Vehicle Fire Suppression System Module 3 Detector Data";
CM_ BO_ 2633719550 "Vehicle Fire Suppression System Module 4 Detector Data";
CM_ BO_ 2633719806 "Vehicle Fire Suppression System Module 1 Auxilliary Data";
CM_ BO_ 2633720062 "Vehicle Fire Suppression System Module 2 Auxilliary Data";
CM_ BO_ 2633720318 "Vehicle Fire Suppression System Module 3 Auxilliary Data";
CM_ BO_ 2633720574 "Vehicle Fire Suppression System Module 4 Auxilliary Data";
CM_ BO_ 2633720830 "Vehicle Fire Suppression System Module 1 Names";
CM_ BO_ 2633721086 "Vehicle Fire Suppression System Module 2 Names";
CM_ BO_ 2633721342 "Vehicle Fire Suppression System Module 3 Names";
CM_ BO_ 2633721598 "Vehicle Fire Suppression System Module 4 Names";
CM_ BO_ 2566612990 "Motor/Generator 2 Inverter Active Power Limits";
CM_ BO_ 2566613246 "Motor/Generator 2 Inverter Isolation Integrity";
CM_ BO_ 2566613502 "Motor/Generator 1 Inverter Active Power Limits";
CM_ BO_ 2566613758 "Motor/Generator 1 Inverter Isolation Integrity";
CM_ BO_ 2566614014 "High Voltage Bus Information";
CM_ BO_ 2365287678 "Motor/Generator 2 Inverter Reference 1";
CM_ BO_ 2365287934 "Motor/Generator 2 Inverter Status 1";
CM_ BO_ 2365288190 "Motor/Generator 2 Inverter Reference 2";
CM_ BO_ 2566615038 "Motor/Generator 2 Inverter Temperature";
CM_ BO_ 2566615294 "Motor/Generator 2 Inverter Motor Temperature";
CM_ BO_ 2566615550 "Motor/Generator 1 Inverter Motor Temperature";
CM_ BO_ 2566615806 "Motor/Generator 1 Inverter Temperature";
CM_ BO_ 2365289470 "Motor/Generator 1 Inverter Reference 2";
CM_ BO_ 2365289726 "Motor/Generator 1 Inverter Status 1";
CM_ BO_ 2365289982 "Motor/Generator 1 Inverter Reference 1";
CM_ BO_ 2566616830 "Personnel Detect Status";
CM_ BO_ 2566617086 "Engine Cylinder Pressure Gamma 1";
CM_ BO_ 2566617342 "Engine Cylinder Pressure Gamma 2";
CM_ BO_ 2566617598 "Engine Cylinder Pressure Gamma 3";
CM_ BO_ 2566617854 "Engine Cylinder Pressure Gamma 4";
CM_ BO_ 2566618110 "Engine Cylinder Pressure Gamma 5";
CM_ BO_ 2566618366 "Reserved for Network Operation Mode";
CM_ BO_ 2566618622 "Electrified Accessory Generator Coolant Pump Status";
CM_ BO_ 2566618878 "Electrified Accessory Generator Coolant Fan Status";
CM_ BO_ 2566619134 "Well Stimulation Pump System Filter Information";
CM_ BO_ 2566619390 "PTO Governor Configuration";
CM_ BO_ 2566619646 "On Board Programming 2";
CM_ BO_ 2566619902 "ISO 11783: Primary or Rear Hitch Yaw";
CM_ BO_ 2566620158 "ISO 11783: Secondary or Front Hitch Yaw";
CM_ BO_ 2566620414 "ISO 11783-7: Operator Status";
CM_ BO_ 2566620670 "Engine Idle Management Information";
CM_ BO_ 2566621438 "Marine Control Information 3";
CM_ BO_ 2566621694 "Engine Fluid Level/Pressure 13";
CM_ BO_ 2365295358 "High Voltage Energy Storage System Data 11";
CM_ BO_ 2566622206 "Economy Mode Inactive Hours";
CM_ BO_ 2566622462 "Economy Mode Estimated Instantaneous Fuel Savings Rate";
CM_ BO_ 2566622718 "Economy Mode Active Hours";
CM_ BO_ 2566622974 "Economy Mode Fuel Used";
CM_ BO_ 2566623230 "Economy Mode Estimated Fuel Savings";
CM_ BO_ 2365296894 "DC/DC Converter 4 Voltage";
CM_ BO_ 2365297150 "DC/DC Converter 3 Voltage";
CM_ BO_ 2365297406 "DC/DC Converter 2 Voltage";
CM_ BO_ 2365297662 "DC/DC Converter 1 Voltage";
CM_ BO_ 2566624510 "Electronic Engine Controller 22";
CM_ BO_ 2566624766 "Engine Hours 2";
CM_ BO_ 2566625022 "Engine Information 3";
CM_ BO_ 2566625278 "Vehicle Electrical Power 15";
CM_ BO_ 2633734398 "Exhaust Oxygen 2";
CM_ BO_ 2566625790 "DC/AC Accessory Inverter 1 Temperatures";
CM_ BO_ 2365299454 "DC/AC Accessory Inverter 1 DC Side Limits";
CM_ BO_ 2365299710 "DC/AC Accessory Inverter 1 AC Side Limits";
CM_ BO_ 2566626558 "DC/AC Accessory Inverter 1 Configuration 1";
CM_ BO_ 2566626814 "DC/AC Accessory Inverter 1 Lifetime Data";
CM_ BO_ 2566627070 "DC/AC Accessory Inverter 2 Temperatures";
CM_ BO_ 2365300734 "DC/AC Accessory Inverter 2 DC Side Limits";
CM_ BO_ 2365300990 "DC/AC Accessory Inverter 2 AC Side Limits";
CM_ BO_ 2566627838 "DC/AC Accessory Inverter 2 Configuration 1";
CM_ BO_ 2566628094 "DC/AC Accessory Inverter 2 Lifetime Data";
CM_ BO_ 2566628350 "DC/AC Accessory Inverter 3 Temperatures";
CM_ BO_ 2365302014 "DC/AC Accessory Inverter 3 DC Side Limits";
CM_ BO_ 2365302270 "DC/AC Accessory Inverter 3 AC Side Limits";
CM_ BO_ 2566629118 "DC/AC Accessory Inverter 3 Configuration 1";
CM_ BO_ 2566629374 "DC/AC Accessory Inverter 3 Lifetime Data";
CM_ BO_ 2566629630 "DC/AC Accessory Inverter 4 Temperatures";
CM_ BO_ 2365303294 "DC/AC Accessory Inverter 4 DC Side Limits";
CM_ BO_ 2365303550 "DC/AC Accessory Inverter 4 AC Side Limits";
CM_ BO_ 2566630398 "DC/AC Accessory Inverter 4 Configuration 1";
CM_ BO_ 2566630654 "DC/AC Accessory Inverter 4 Lifetime Data";
CM_ BO_ 2566630910 "DC/AC Accessory Inverter 5 Temperatures";
CM_ BO_ 2365304574 "DC/AC Accessory Inverter 5 DC Side Limits";
CM_ BO_ 2365304830 "DC/AC Accessory Inverter 5 AC Side Limits";
CM_ BO_ 2566631678 "DC/AC Accessory Inverter 5 Configuration 1";
CM_ BO_ 2566631934 "DC/AC Accessory Inverter 5 Lifetime Data";
CM_ BO_ 2566632190 "Well Stimulation Pump Sensor Calibration Status";
CM_ BO_ 2566632446 "Well Stimulation Pump Fluid Volume";
CM_ BO_ 2566632702 "Well Stimulation Pump Serial Number";
CM_ BO_ 2566632958 "Well Stimulation Pump Trip Hours";
CM_ BO_ 2566633214 "Aftertreatment 1 Outlet Gas 4";
CM_ BO_ 2566633470 "Aftertreatment 1 Intake Gas 4";
CM_ BO_ 2566633726 "DC/DC Converter 4 Lifetime Data";
CM_ BO_ 2566633982 "DC/DC Converter 4 Configuration 1";
CM_ BO_ 2365307646 "DC/DC Converter 4 SLI Battery Limits";
CM_ BO_ 2365307902 "DC/DC Converter 4 Temperatures";
CM_ BO_ 2365308158 "DC/DC Converter 4 Low Side Limits";
CM_ BO_ 2365308414 "DC/DC Converter 4 High Side Limits";
CM_ BO_ 2566635262 "DC/DC Converter 3 Lifetime Data";
CM_ BO_ 2566635518 "DC/DC Converter 3 Configuration 1";
CM_ BO_ 2365309182 "DC/DC Converter 3 SLI Battery Limits";
CM_ BO_ 2365309438 "DC/DC Converter 3 Temperatures";
CM_ BO_ 2365309694 "DC/DC Converter 3 Low Side Limits";
CM_ BO_ 2365309950 "DC/DC Converter 3 High Side Limits";
CM_ BO_ 2566636798 "DC/DC Converter 2 Lifetime Data";
CM_ BO_ 2566637054 "DC/DC Converter 2 Configuration 1";
CM_ BO_ 2365310718 "DC/DC Converter 2 SLI Battery Limits";
CM_ BO_ 2365310974 "DC/DC Converter 2 Temperatures";
CM_ BO_ 2365311230 "DC/DC Converter 2 Low Side Limits";
CM_ BO_ 2365311486 "DC/DC Converter 2 High Side Limits";
CM_ BO_ 2566638590 "Engine Exhaust Particulate Control System Info";
CM_ BO_ 2566638846 "Well Stimulation Pump Hours";
CM_ BO_ 2566639102 "Well Stimulation Pump System Configuration Status";
CM_ BO_ 2633748222 "Configurable Receive SPNs Status";
CM_ BO_ 2566639614 "DC/DC Converter 1 Lifetime Data";
CM_ BO_ 2566639870 "DC/DC Converter 1 Configuration 1";
CM_ BO_ 2365313534 "DC/DC Converter 1 SLI Battery Limits";
CM_ BO_ 2566640382 "Pump Oil Message";
CM_ BO_ 2633749502 "Well Stimulation Pump System Lifetime Totals";
CM_ BO_ 2633749758 "Well Stimulation Pump System Configuration";
CM_ BO_ 2566641150 "Aftercooler and Oil Cooler Fluids 2";
CM_ BO_ 2566641406 "Electronic Engine Controller 21";
CM_ BO_ 2633750526 "Configurable Transmit PGNs Status";
CM_ BO_ 2365315326 "DC/DC Converter 1 Temperatures";
CM_ BO_ 2365315582 "DC/DC Converter 1 Low Side Limits";
CM_ BO_ 2365315838 "DC/DC Converter 1 High Side Limits";
CM_ BO_ 2566642686 "Reserved for Diagnostic Message";
CM_ BO_ 2566642942 "Door Control 4";
CM_ BO_ 2566643198 "Door Control 3";
CM_ BO_ 2566643454 "Engine Temperature 6";
CM_ BO_ 2566643710 "Intake/Exhaust Conditions 3";
BA_DEF_ BO_  "GenMsgCycleTime" INT 0 65535;
BA_DEF_ SG_  "SigType" ENUM "Default","Range","RangeSigned","ASCII","Discrete","Control","ReferencePGN","DTC","StringDelimiter","StringLength","StringLengthControl","MessageCounter","MessageChecksum";
BA_DEF_DEF_  "GenMsgCycleTime" 0;
BA_DEF_DEF_  "SigType" "Default";
BA_ "GenMsgCycleTime" BO_ 2365266174 100;
BA_ "GenMsgCycleTime" BO_ 2566593022 1000;
BA_ "GenMsgCycleTime" BO_ 2566593278 1000;
BA_ "GenMsgCycleTime" BO_ 2566593534 1000;
BA_ "GenMsgCycleTime" BO_ 2365267454 100;
BA_ "GenMsgCycleTime" BO_ 2566594302 1000;
BA_ "GenMsgCycleTime" BO_ 2566594558 1000;
BA_ "GenMsgCycleTime" BO_ 2566594814 1000;
BA_ "GenMsgCycleTime" BO_ 2365268734 100;
BA_ "GenMsgCycleTime" BO_ 2566595582 1000;
BA_ "GenMsgCycleTime" BO_ 2566595838 1000;
BA_ "GenMsgCycleTime" BO_ 2566596094 1000;
BA_ "GenMsgCycleTime" BO_ 2365270014 100;
BA_ "GenMsgCycleTime" BO_ 2566596862 1000;
BA_ "GenMsgCycleTime" BO_ 2566597118 1000;
BA_ "GenMsgCycleTime" BO_ 2566597374 1000;
BA_ "GenMsgCycleTime" BO_ 2566598142 1000;
BA_ "GenMsgCycleTime" BO_ 2365272062 1000;
BA_ "GenMsgCycleTime" BO_ 2365272318 10;
BA_ "GenMsgCycleTime" BO_ 2365272574 1000;
BA_ "GenMsgCycleTime" BO_ 2566599422 1000;
BA_ "GenMsgCycleTime" BO_ 2566599678 1000;
BA_ "GenMsgCycleTime" BO_ 2566599934 250;
BA_ "GenMsgCycleTime" BO_ 2566600190 1000;
BA_ "GenMsgCycleTime" BO_ 2365273854 1000;
BA_ "GenMsgCycleTime" BO_ 2365274110 10;
BA_ "GenMsgCycleTime" BO_ 2365274366 1000;
BA_ "GenMsgCycleTime" BO_ 2566601214 1000;
BA_ "GenMsgCycleTime" BO_ 2566601470 1000;
BA_ "GenMsgCycleTime" BO_ 2566601726 250;
BA_ "GenMsgCycleTime" BO_ 2566601982 1000;
BA_ "GenMsgCycleTime" BO_ 2365275646 1000;
BA_ "GenMsgCycleTime" BO_ 2365275902 10;
BA_ "GenMsgCycleTime" BO_ 2365276158 1000;
BA_ "GenMsgCycleTime" BO_ 2566603006 1000;
BA_ "GenMsgCycleTime" BO_ 2566603262 1000;
BA_ "GenMsgCycleTime" BO_ 2566603518 250;
BA_ "GenMsgCycleTime" BO_ 2566603774 1000;
BA_ "GenMsgCycleTime" BO_ 2365277438 1000;
BA_ "GenMsgCycleTime" BO_ 2365277694 10;
BA_ "GenMsgCycleTime" BO_ 2365277950 1000;
BA_ "GenMsgCycleTime" BO_ 2566604798 1000;
BA_ "GenMsgCycleTime" BO_ 2566605054 1000;
BA_ "GenMsgCycleTime" BO_ 2566605310 250;
BA_ "GenMsgCycleTime" BO_ 2566605566 1000;
BA_ "GenMsgCycleTime" BO_ 2566605822 1000;
BA_ "GenMsgCycleTime" BO_ 2566606078 1000;
BA_ "GenMsgCycleTime" BO_ 2566606334 1000;
BA_ "GenMsgCycleTime" BO_ 2499497726 250;
BA_ "GenMsgCycleTime" BO_ 2566612990 1000;
BA_ "GenMsgCycleTime" BO_ 2566613246 250;
BA_ "GenMsgCycleTime" BO_ 2566613502 1000;
BA_ "GenMsgCycleTime" BO_ 2566613758 250;
BA_ "GenMsgCycleTime" BO_ 2566614014 1000;
BA_ "GenMsgCycleTime" BO_ 2365287678 1000;
BA_ "GenMsgCycleTime" BO_ 2365287934 10;
BA_ "GenMsgCycleTime" BO_ 2365288190 1000;
BA_ "GenMsgCycleTime" BO_ 2566615038 1000;
BA_ "GenMsgCycleTime" BO_ 2566615294 1000;
BA_ "GenMsgCycleTime" BO_ 2566615550 1000;
BA_ "GenMsgCycleTime" BO_ 2566615806 1000;
BA_ "GenMsgCycleTime" BO_ 2365289470 1000;
BA_ "GenMsgCycleTime" BO_ 2365289726 10;
BA_ "GenMsgCycleTime" BO_ 2365289982 1000;
BA_ "GenMsgCycleTime" BO_ 2566616830 1000;
BA_ "GenMsgCycleTime" BO_ 2566618622 1000;
BA_ "GenMsgCycleTime" BO_ 2566618878 1000;
BA_ "GenMsgCycleTime" BO_ 2566620670 1000;
BA_ "GenMsgCycleTime" BO_ 2566621438 1000;
BA_ "GenMsgCycleTime" BO_ 2566621694 500;
BA_ "GenMsgCycleTime" BO_ 2365295358 100;
BA_ "GenMsgCycleTime" BO_ 2566622462 1000;
BA_ "GenMsgCycleTime" BO_ 2365296894 100;
BA_ "GenMsgCycleTime" BO_ 2365297150 100;
BA_ "GenMsgCycleTime" BO_ 2365297406 100;
BA_ "GenMsgCycleTime" BO_ 2365297662 100;
BA_ "GenMsgCycleTime" BO_ 2566625022 100;
BA_ "GenMsgCycleTime" BO_ 2566625790 1000;
BA_ "GenMsgCycleTime" BO_ 2365299454 1000;
BA_ "GenMsgCycleTime" BO_ 2365299710 1000;
BA_ "GenMsgCycleTime" BO_ 2566626558 5000;
BA_ "GenMsgCycleTime" BO_ 2566627070 1000;
BA_ "GenMsgCycleTime" BO_ 2365300734 1000;
BA_ "GenMsgCycleTime" BO_ 2365300990 1000;
BA_ "GenMsgCycleTime" BO_ 2566627838 5000;
BA_ "GenMsgCycleTime" BO_ 2566628350 1000;
BA_ "GenMsgCycleTime" BO_ 2365302014 1000;
BA_ "GenMsgCycleTime" BO_ 2365302270 1000;
BA_ "GenMsgCycleTime" BO_ 2566629118 5000;
BA_ "GenMsgCycleTime" BO_ 2566629630 1000;
BA_ "GenMsgCycleTime" BO_ 2365303294 1000;
BA_ "GenMsgCycleTime" BO_ 2365303550 1000;
BA_ "GenMsgCycleTime" BO_ 2566630398 5000;
BA_ "GenMsgCycleTime" BO_ 2566630910 1000;
BA_ "GenMsgCycleTime" BO_ 2365304574 1000;
BA_ "GenMsgCycleTime" BO_ 2365304830 1000;
BA_ "GenMsgCycleTime" BO_ 2566631678 5000;
BA_ "GenMsgCycleTime" BO_ 2566633214 100;
BA_ "GenMsgCycleTime" BO_ 2566633470 100;
BA_ "GenMsgCycleTime" BO_ 2566633982 5000;
BA_ "GenMsgCycleTime" BO_ 2365307646 1000;
BA_ "GenMsgCycleTime" BO_ 2365307902 1000;
BA_ "GenMsgCycleTime" BO_ 2365308158 1000;
BA_ "GenMsgCycleTime" BO_ 2365308414 1000;
BA_ "GenMsgCycleTime" BO_ 2566635518 5000;
BA_ "GenMsgCycleTime" BO_ 2365309182 1000;
BA_ "GenMsgCycleTime" BO_ 2365309438 1000;
BA_ "GenMsgCycleTime" BO_ 2365309694 1000;
BA_ "GenMsgCycleTime" BO_ 2365309950 1000;
BA_ "GenMsgCycleTime" BO_ 2566637054 5000;
BA_ "GenMsgCycleTime" BO_ 2365310718 1000;
BA_ "GenMsgCycleTime" BO_ 2365310974 1000;
BA_ "GenMsgCycleTime" BO_ 2365311230 1000;
BA_ "GenMsgCycleTime" BO_ 2365311486 1000;
BA_ "GenMsgCycleTime" BO_ 2566638590 10000;
BA_ "GenMsgCycleTime" BO_ 2566639870 5000;
BA_ "GenMsgCycleTime" BO_ 2365313534 1000;
BA_ "GenMsgCycleTime" BO_ 2566641150 1000;
BA_ "GenMsgCycleTime" BO_ 2566641406 100;
BA_ "GenMsgCycleTime" BO_ 2365315326 1000;
BA_ "GenMsgCycleTime" BO_ 2365315582 1000;
BA_ "GenMsgCycleTime" BO_ 2365315838 1000;
BA_ "GenMsgCycleTime" BO_ 2566642942 1000;
BA_ "GenMsgCycleTime" BO_ 2566643198 1000;
BA_ "GenMsgCycleTime" BO_ 2566643454 1000;
BA_ "GenMsgCycleTime" BO_ 2566643710 500;
BA_ "SigType" SG_ 2633720830 VFSSModule1Name 3;
BA_ "SigType" SG_ 2633720830 VFSSModule1DetectorZone1Name 3;
BA_ "SigType" SG_ 2633720830 VFSSModule1DetectorZone2Name 3;
BA_ "SigType" SG_ 2633720830 VFSSModule1DetectorZone3Name 3;
BA_ "SigType" SG_ 2633720830 VFSSModule1DetectorZone4Name 3;
BA_ "SigType" SG_ 2633720830 VFSSModule1DetectorZone5Name 3;
BA_ "SigType" SG_ 2633720830 VFSSModule1DetectorZone6Name 3;
BA_ "SigType" SG_ 2633720830 VFSSModule1DetectorZone7Name 3;
BA_ "SigType" SG_ 2633720830 VFSSModule1DetectorZone8Name 3;
BA_ "SigType" SG_ 2633720830 VFSSModule1HeatZone1Name 3;
BA_ "SigType" SG_ 2633720830 VFSSModule1HeatZone2Name 3;
BA_ "SigType" SG_ 2633720830 VFSSModule1ReleaseZone1Name 3;
BA_ "SigType" SG_ 2633720830 VFSSModule1ReleaseZone2Name 3;
BA_ "SigType" SG_ 2633721086 VFSSModule2Name 3;
BA_ "SigType" SG_ 2633721086 VFSSModule2DetectorZone1Name 3;
BA_ "SigType" SG_ 2633721086 VFSSModule2DetectorZone2Name 3;
BA_ "SigType" SG_ 2633721086 VFSSModule2DetectorZone3Name 3;
BA_ "SigType" SG_ 2633721086 VFSSModule2DetectorZone4Name 3;
BA_ "SigType" SG_ 2633721086 VFSSModule2DetectorZone5Name 3;
BA_ "SigType" SG_ 2633721086 VFSSModule2DetectorZone6Name 3;
BA_ "SigType" SG_ 2633721086 VFSSModule2DetectorZone7Name 3;
BA_ "SigType" SG_ 2633721086 VFSSModule2DetectorZone8Name 3;
BA_ "SigType" SG_ 2633721086 VFSSModule2HeatZone1Name 3;
BA_ "SigType" SG_ 2633721086 VFSSModule2HeatZone2Name 3;
BA_ "SigType" SG_ 2633721086 VFSSModule2ReleaseZone1Name 3;
BA_ "SigType" SG_ 2633721086 VFSSModule2ReleaseZone2Name 3;
BA_ "SigType" SG_ 2633721342 VFSSModule3Name 3;
BA_ "SigType" SG_ 2633721342 VFSSModule3DetectorZone1Name 3;
BA_ "SigType" SG_ 2633721342 VFSSModule3DetectorZone2Name 3;
BA_ "SigType" SG_ 2633721342 VFSSModule3DetectorZone3Name 3;
BA_ "SigType" SG_ 2633721342 VFSSModule3DetectorZone4Name 3;
BA_ "SigType" SG_ 2633721342 VFSSModule3DetectorZone5Name 3;
BA_ "SigType" SG_ 2633721342 VFSSModule3DetectorZone6Name 3;
BA_ "SigType" SG_ 2633721342 VFSSModule3DetectorZone7Name 3;
BA_ "SigType" SG_ 2633721342 VFSSModule3DetectorZone8Name 3;
BA_ "SigType" SG_ 2633721342 VFSSModule3HeatZone1Name 3;
BA_ "SigType" SG_ 2633721342 VFSSModule3HeatZone2Name 3;
BA_ "SigType" SG_ 2633721342 VFSSModule3ReleaseZone1Name 3;
BA_ "SigType" SG_ 2633721342 VFSSModule3ReleaseZone2Name 3;
BA_ "SigType" SG_ 2633721598 VFSSModule4Name 3;
BA_ "SigType" SG_ 2633721598 VFSSModule4DetectorZone1Name 3;
BA_ "SigType" SG_ 2633721598 VFSSModule4DetectorZone2Name 3;
BA_ "SigType" SG_ 2633721598 VFSSModule4DetectorZone3Name 3;
BA_ "SigType" SG_ 2633721598 VFSSModule4DetectorZone4Name 3;
BA_ "SigType" SG_ 2633721598 VFSSModule4DetectorZone5Name 3;
BA_ "SigType" SG_ 2633721598 VFSSModule4DetectorZone6Name 3;
BA_ "SigType" SG_ 2633721598 VFSSModule4DetectorZone7Name 3;
BA_ "SigType" SG_ 2633721598 VFSSModule4DetectorZone8Name 3;
BA_ "SigType" SG_ 2633721598 VFSSModule4HeatZone1Name 3;
BA_ "SigType" SG_ 2633721598 VFSSModule4HeatZone2Name 3;
BA_ "SigType" SG_ 2633721598 VFSSModule4ReleaseZone1Name 3;
BA_ "SigType" SG_ 2633721598 VFSSModule4ReleaseZone2Name 3;
BA_ "SigType" SG_ 2566632702 WellStimulationPmpPwrEndSerialNo 3;
BA_ "SigType" SG_ 2566632702 WellStimulationPmpFldEndSerialNo 3;
VAL_ 2365266174 MtrGen6InvPIDCtrlApplicableMde 0 "Speed Control Mode" 1 "DC Side Voltage Mode" 2 "DC Side Current Mode" 3 "DC Power Control Mode" 4 "Mechanical Power Control Mode" 5 "SAE Reserved" 15 "Don't Care/Take No Action" ;
VAL_ 2566593790 MtrGen6InvHiVBusActIsoltnTtCmd 0 "Active Isolation Test not requested" 1 "Active Isolation Test request" 2 "Inhibit Active Isolation Test" 3 "Don't care/Take no action" ;
VAL_ 2566593790 MtrGen6InvHiVBusPassIsoltnTtCmd 0 "Passive Isolation Test not requested" 1 "Passive Isolation Test request" 2 "Inhibit Passive Isolation Test" 3 "Don't care/Take no action" ;
VAL_ 2566593790 MtrGen6InvHVBusHiSdeRsstrCnnctRq 0 "Connection not Requested" 1 "Connection Requested" 2 "Reserved" 3 "Don't care/take no action" ;
VAL_ 2566593790 MtrGen6InvHVBusLoSdeRsstrCnnctRq 0 "Connection not Requested" 1 "Connection Requested" 2 "Reserved" 3 "Don't care/take no action" ;
VAL_ 2365267454 MtrGen5InvPIDCtrlApplicableMde 0 "Speed Control Mode" 1 "DC Side Voltage Mode" 2 "DC Side Current Mode" 3 "DC Power Control Mode" 4 "Mechanical Power Control Mode" 5 "SAE Reserved" 15 "Don't Care/Take No Action" ;
VAL_ 2566595070 MtrGen5InvHiVBusActIsoltnTtCmd 0 "Active Isolation Test not requested" 1 "Active Isolation Test request" 2 "Inhibit Active Isolation Test" 3 "Don't care/Take no action" ;
VAL_ 2566595070 MtrGen5InvHiVBusPassIsoltnTtCmd 0 "Passive Isolation Test not requested" 1 "Passive Isolation Test request" 2 "Inhibit Passive Isolation Test" 3 "Don't care/Take no action" ;
VAL_ 2566595070 MtrGen5InvHVBusHiSdeRsstrCnnctRq 0 "Connection not Requested" 1 "Connection Requested" 2 "Reserved" 3 "Don't care/take no action" ;
VAL_ 2566595070 MtrGen5InvHVBusLoSdeRsstrCnnctRq 0 "Connection not Requested" 1 "Connection Requested" 2 "Reserved" 3 "Don't care/take no action" ;
VAL_ 2365268734 MtrGen4InvPIDCtrlApplicableMde 0 "Speed Control Mode" 1 "DC Side Voltage Mode" 2 "DC Side Current Mode" 3 "DC Power Control Mode" 4 "Mechanical Power Control Mode" 5 "SAE Reserved" 15 "Don't Care/Take No Action" ;
VAL_ 2566596350 MtrGen4InvHiVBusActIsoltnTtCmd 0 "Active Isolation Test not requested" 1 "Active Isolation Test request" 2 "Inhibit Active Isolation Test" 3 "Don't care/Take no action" ;
VAL_ 2566596350 MtrGen4InvHiVBusPassIsoltnTtCmd 0 "Passive Isolation Test not requested" 1 "Passive Isolation Test request" 2 "Inhibit Passive Isolation Test" 3 "Don't care/Take no action" ;
VAL_ 2566596350 MtrGen4InvHVBusHiSdeRsstrCnnctRq 0 "Connection not Requested" 1 "Connection Requested" 2 "Reserved" 3 "Don't care/take no action" ;
VAL_ 2566596350 MtrGen4InvHVBusLoSdeRsstrCnnctRq 0 "Connection not Requested" 1 "Connection Requested" 2 "Reserved" 3 "Don't care/take no action" ;
VAL_ 2365270014 MtrGen3InvPIDCtrlApplicableMde 0 "Speed Control Mode" 1 "DC Side Voltage Mode" 2 "DC Side Current Mode" 3 "DC Power Control Mode" 4 "Mechanical Power Control Mode" 5 "SAE Reserved" 15 "Don't Care/Take No Action" ;
VAL_ 2566597630 MtrGen3InvHiVBusActIsoltnTtCmd 0 "Active Isolation Test not requested" 1 "Active Isolation Test request" 2 "Inhibit Active Isolation Test" 3 "Don't care/Take no action" ;
VAL_ 2566597630 MtrGen3InvHiVBusPassIsoltnTtCmd 0 "Passive Isolation Test not requested" 1 "Passive Isolation Test request" 2 "Inhibit Passive Isolation Test" 3 "Don't care/Take no action" ;
VAL_ 2566597630 MtrGen3InvHVBusHiSdeRsstrCnnctRq 0 "Connection not Requested" 1 "Connection Requested" 2 "Reserved" 3 "Don't care/take no action" ;
VAL_ 2566597630 MtrGen3InvHVBusLoSdeRsstrCnnctRq 0 "Connection not Requested" 1 "Connection Requested" 2 "Reserved" 3 "Don't care/take no action" ;
VAL_ 2566599934 MtrGen6InvHiVltgBusActIsoltnTtSt 0 "No test requested / No test in process" 1 "Test requested but not yet in process" 2 "Test in process" 3 "Test complete - isolation acceptable" 4 "Test complete - isolation marginal" 5 "Test complete - isolation fault" 6 "Active Isolation Test Inhibited" 7 "Reserved" 14 "Error" 15 "Not available" ;
VAL_ 2566599934 MtrGen6InvHiVBusPassIsoltnTtSt 0 "No test requested / No test in process" 1 "Test requested but not yet in process" 2 "Test in process" 3 "Test complete - isolation acceptable" 4 "Test complete - isolation marginal" 5 "Test complete - isolation fault" 6 "Passive Isolation Test Inhibited" 7 "Reserved" 14 "Error" 15 "Not available" ;
VAL_ 2566600190 MtrGen6InvPwrLmtedDTUndefndRsn 0 "No power limit for this reason" 1 "Power limited for this reason" 2 "Error" 3 "Not Available" ;
VAL_ 2566600190 MtrGen6InvPwrLmtedDTDCSdeCurMax 0 "No power limit for this reason" 1 "Power limited for this reason" 2 "Error" 3 "Not Available" ;
VAL_ 2566600190 MtrGen6InvPwrLmtedDTDCSdeCurMin 0 "No power limit for this reason" 1 "Power limited for this reason" 2 "Error" 3 "Not Available" ;
VAL_ 2566600190 MtrGen6InvPwrLmtedDTDCSdeVltgMax 0 "No power limit for this reason" 1 "Power limited for this reason" 2 "Error" 3 "Not Available" ;
VAL_ 2566600190 MtrGen6InvPwrLmtedDTDCSdeVltgMin 0 "No power limit for this reason" 1 "Power limited for this reason" 2 "Error" 3 "Not Available" ;
VAL_ 2566600190 MtrGen6InvPwrLmtDTMechnclPwrMax 0 "No power limit for this reason" 1 "Power limited for this reason" 2 "Error" 3 "Not Available" ;
VAL_ 2566600190 MtrGen6InvPwrLmtDTMechnclPwrMin 0 "No power limit for this reason" 1 "Power limited for this reason" 2 "Error" 3 "Not Available" ;
VAL_ 2566600190 MtrGen6InvPwrLmtedDTDCSdePwrMax 0 "No power limit for this reason" 1 "Power limited for this reason" 2 "Error" 3 "Not Available" ;
VAL_ 2566600190 MtrGen6InvPwrLmtedDTDCSdePwrMin 0 "No power limit for this reason" 1 "Power limited for this reason" 2 "Error" 3 "Not Available" ;
VAL_ 2566600190 MtrGen6InvertPwrLmtedDTTorqueMax 0 "No power limit for this reason" 1 "Power limited for this reason" 2 "Error" 3 "Not Available" ;
VAL_ 2566600190 MtrGen6InvertPwrLmtedDTTorqueMin 0 "No power limit for this reason" 1 "Power limited for this reason" 2 "Error" 3 "Not Available" ;
VAL_ 2566600190 MtrGen6InvertPwrLmtedDTSpeedMax 0 "No power limit for this reason" 1 "Power limited for this reason" 2 "Error" 3 "Not Available" ;
VAL_ 2566600190 MtrGen6InvertPwrLmtedDTSpeedMin 0 "No power limit for this reason" 1 "Power limited for this reason" 2 "Error" 3 "Not Available" ;
VAL_ 2566600190 MtrGen6InvPwrLmtedDTInvertTemp 0 "No power limit for this reason" 1 "Power limited for this reason" 2 "Error" 3 "Not Available" ;
VAL_ 2566600190 MtrGen6InvertPwrLmtedDTMtrTemp 0 "No power limit for this reason" 1 "Power limited for this reason" 2 "Error" 3 "Not Available" ;
VAL_ 2566601726 MtrGen5InvHiVltgBusActIsoltnTtSt 0 "No test requested / No test in process" 1 "Test requested but not yet in process" 2 "Test in process" 3 "Test complete - isolation acceptable" 4 "Test complete - isolation marginal" 5 "Test complete - isolation fault" 6 "Active Isolation Test Inhibited" 7 "Reserved" 14 "Error" 15 "Not available" ;
VAL_ 2566601726 MtrGen5InvHiVBusPassIsoltnTtSt 0 "No test requested / No test in process" 1 "Test requested but not yet in process" 2 "Test in process" 3 "Test complete - isolation acceptable" 4 "Test complete - isolation marginal" 5 "Test complete - isolation fault" 6 "Passive Isolation Test Inhibited" 7 "Reserved" 14 "Error" 15 "Not available" ;
VAL_ 2566601982 MtrGen5InvPwrLmtedDTUndefndRsn 0 "No power limit for this reason" 1 "Power limited for this reason" 2 "Error" 3 "Not Available" ;
VAL_ 2566601982 MtrGen5InvPwrLmtedDTDCSdeCurMax 0 "No power limit for this reason" 1 "Power limited for this reason" 2 "Error" 3 "Not Available" ;
VAL_ 2566601982 MtrGen5InvPwrLmtedDTDCSdeCurMin 0 "No power limit for this reason" 1 "Power limited for this reason" 2 "Error" 3 "Not Available" ;
VAL_ 2566601982 MtrGen5InvPwrLmtedDTDCSdeVltgMax 0 "No power limit for this reason" 1 "Power limited for this reason" 2 "Error" 3 "Not Available" ;
VAL_ 2566601982 MtrGen5InvPwrLmtedDTDCSdeVltgMin 0 "No power limit for this reason" 1 "Power limited for this reason" 2 "Error" 3 "Not Available" ;
VAL_ 2566601982 MtrGen5InvPwrLmtDTMechnclPwrMax 0 "No power limit for this reason" 1 "Power limited for this reason" 2 "Error" 3 "Not Available" ;
VAL_ 2566601982 MtrGen5InvPwrLmtDTMechnclPwrMin 0 "No power limit for this reason" 1 "Power limited for this reason" 2 "Error" 3 "Not Available" ;
VAL_ 2566601982 MtrGen5InvPwrLmtedDTDCSdePwrMax 0 "No power limit for this reason" 1 "Power limited for this reason" 2 "Error" 3 "Not Available" ;
VAL_ 2566601982 MtrGen5InvPwrLmtedDTDCSdePwrMin 0 "No power limit for this reason" 1 "Power limited for this reason" 2 "Error" 3 "Not Available" ;
VAL_ 2566601982 MtrGen5InvertPwrLmtedDTTorqueMax 0 "No power limit for this reason" 1 "Power limited for this reason" 2 "Error" 3 "Not Available" ;
VAL_ 2566601982 MtrGen5InvertPwrLmtedDTTorqueMin 0 "No power limit for this reason" 1 "Power limited for this reason" 2 "Error" 3 "Not Available" ;
VAL_ 2566601982 MtrGen5InvertPwrLmtedDTSpeedMax 0 "No power limit for this reason" 1 "Power limited for this reason" 2 "Error" 3 "Not Available" ;
VAL_ 2566601982 MtrGen5InvertPwrLmtedDTSpeedMin 0 "No power limit for this reason" 1 "Power limited for this reason" 2 "Error" 3 "Not Available" ;
VAL_ 2566601982 MtrGen5InvPwrLmtedDTInvertTemp 0 "No power limit for this reason" 1 "Power limited for this reason" 2 "Error" 3 "Not Available" ;
VAL_ 2566601982 MtrGen5InvertPwrLmtedDTMtrTemp 0 "No power limit for this reason" 1 "Power limited for this reason" 2 "Error" 3 "Not Available" ;
VAL_ 2566603518 MtrGen4InvHiVltgBusActIsoltnTtSt 0 "No test requested / No test in process" 1 "Test requested but not yet in process" 2 "Test in process" 3 "Test complete - isolation acceptable" 4 "Test complete - isolation marginal" 5 "Test complete - isolation fault" 6 "Active Isolation Test Inhibited" 7 "Reserved" 14 "Error" 15 "Not available" ;
VAL_ 2566603518 MtrGen4InvHiVBusPassIsoltnTtSt 0 "No test requested / No test in process" 1 "Test requested but not yet in process" 2 "Test in process" 3 "Test complete - isolation acceptable" 4 "Test complete - isolation marginal" 5 "Test complete - isolation fault" 6 "Passive Isolation Test Inhibited" 7 "Reserved" 14 "Error" 15 "Not available" ;
VAL_ 2566603774 MtrGen4InvPwrLmtedDTUndefndRsn 0 "No power limit for this reason" 1 "Power limited for this reason" 2 "Error" 3 "Not Available" ;
VAL_ 2566603774 MtrGen4InvPwrLmtedDTDCSdeCurMax 0 "No power limit for this reason" 1 "Power limited for this reason" 2 "Error" 3 "Not Available" ;
VAL_ 2566603774 MtrGen4InvPwrLmtedDTDCSdeCurMin 0 "No power limit for this reason" 1 "Power limited for this reason" 2 "Error" 3 "Not Available" ;
VAL_ 2566603774 MtrGen4InvPwrLmtedDTDCSdeVltgMax 0 "No power limit for this reason" 1 "Power limited for this reason" 2 "Error" 3 "Not Available" ;
VAL_ 2566603774 MtrGen4InvPwrLmtedDTDCSdeVltgMin 0 "No power limit for this reason" 1 "Power limited for this reason" 2 "Error" 3 "Not Available" ;
VAL_ 2566603774 MtrGen4InvPwrLmtDTMechnclPwrMax 0 "No power limit for this reason" 1 "Power limited for this reason" 2 "Error" 3 "Not Available" ;
VAL_ 2566603774 MtrGen4InvPwrLmtDTMechnclPwrMin 0 "No power limit for this reason" 1 "Power limited for this reason" 2 "Error" 3 "Not Available" ;
VAL_ 2566603774 MtrGen4InvPwrLmtedDTDCSdePwrMax 0 "No power limit for this reason" 1 "Power limited for this reason" 2 "Error" 3 "Not Available" ;
VAL_ 2566603774 MtrGen4InvPwrLmtedDTDCSdePwrMin 0 "No power limit for this reason" 1 "Power limited for this reason" 2 "Error" 3 "Not Available" ;
VAL_ 2566603774 MtrGen4InvertPwrLmtedDTTorqueMax 0 "No power limit for this reason" 1 "Power limited for this reason" 2 "Error" 3 "Not Available" ;
VAL_ 2566603774 MtrGen4InvertPwrLmtedDTTorqueMin 0 "No power limit for this reason" 1 "Power limited for this reason" 2 "Error" 3 "Not Available" ;
VAL_ 2566603774 MtrGen4InvertPwrLmtedDTSpeedMax 0 "No power limit for this reason" 1 "Power limited for this reason" 2 "Error" 3 "Not Available" ;
VAL_ 2566603774 MtrGen4InvertPwrLmtedDTSpeedMin 0 "No power limit for this reason" 1 "Power limited for this reason" 2 "Error" 3 "Not Available" ;
VAL_ 2566603774 MtrGen4InvPwrLmtedDTInvertTemp 0 "No power limit for this reason" 1 "Power limited for this reason" 2 "Error" 3 "Not Available" ;
VAL_ 2566603774 MtrGen4InvertPwrLmtedDTMtrTemp 0 "No power limit for this reason" 1 "Power limited for this reason" 2 "Error" 3 "Not Available" ;
VAL_ 2566605310 MtrGen3InvHiVltgBusActIsoltnTtSt 0 "No test requested / No test in process" 1 "Test requested but not yet in process" 2 "Test in process" 3 "Test complete - isolation acceptable" 4 "Test complete - isolation marginal" 5 "Test complete - isolation fault" 6 "Active Isolation Test Inhibited" 7 "Reserved" 14 "Error" 15 "Not available" ;
VAL_ 2566605310 MtrGen3InvHiVBusPassIsoltnTtSt 0 "No test requested / No test in process" 1 "Test requested but not yet in process" 2 "Test in process" 3 "Test complete - isolation acceptable" 4 "Test complete - isolation marginal" 5 "Test complete - isolation fault" 6 "Passive Isolation Test Inhibited" 7 "Reserved" 14 "Error" 15 "Not available" ;
VAL_ 2566605566 MtrGen3InvPwrLmtedDTUndefndRsn 0 "No power limit for this reason" 1 "Power limited for this reason" 2 "Error" 3 "Not Available" ;
VAL_ 2566605566 MtrGen3InvPwrLmtedDTDCSdeCurMax 0 "No power limit for this reason" 1 "Power limited for this reason" 2 "Error" 3 "Not Available" ;
VAL_ 2566605566 MtrGen3InvPwrLmtedDTDCSdeCurMin 0 "No power limit for this reason" 1 "Power limited for this reason" 2 "Error" 3 "Not Available" ;
VAL_ 2566605566 MtrGen3InvPwrLmtedDTDCSdeVltgMax 0 "No power limit for this reason" 1 "Power limited for this reason" 2 "Error" 3 "Not Available" ;
VAL_ 2566605566 MtrGen3InvPwrLmtedDTDCSdeVltgMin 0 "No power limit for this reason" 1 "Power limited for this reason" 2 "Error" 3 "Not Available" ;
VAL_ 2566605566 MtrGen3InvPwrLmtDTMechnclPwrMax 0 "No power limit for this reason" 1 "Power limited for this reason" 2 "Error" 3 "Not Available" ;
VAL_ 2566605566 MtrGen3InvPwrLmtDTMechnclPwrMin 0 "No power limit for this reason" 1 "Power limited for this reason" 2 "Error" 3 "Not Available" ;
VAL_ 2566605566 MtrGen3InvPwrLmtedDTDCSdePwrMax 0 "No power limit for this reason" 1 "Power limited for this reason" 2 "Error" 3 "Not Available" ;
VAL_ 2566605566 MtrGen3InvPwrLmtedDTDCSdePwrMin 0 "No power limit for this reason" 1 "Power limited for this reason" 2 "Error" 3 "Not Available" ;
VAL_ 2566605566 MtrGen3InvertPwrLmtedDTTorqueMax 0 "No power limit for this reason" 1 "Power limited for this reason" 2 "Error" 3 "Not Available" ;
VAL_ 2566605566 MtrGen3InvertPwrLmtedDTTorqueMin 0 "No power limit for this reason" 1 "Power limited for this reason" 2 "Error" 3 "Not Available" ;
VAL_ 2566605566 MtrGen3InvertPwrLmtedDTSpeedMax 0 "No power limit for this reason" 1 "Power limited for this reason" 2 "Error" 3 "Not Available" ;
VAL_ 2566605566 MtrGen3InvertPwrLmtedDTSpeedMin 0 "No power limit for this reason" 1 "Power limited for this reason" 2 "Error" 3 "Not Available" ;
VAL_ 2566605566 MtrGen3InvPwrLmtedDTInvertTemp 0 "No power limit for this reason" 1 "Power limited for this reason" 2 "Error" 3 "Not Available" ;
VAL_ 2566605566 MtrGen3InvertPwrLmtedDTMtrTemp 0 "No power limit for this reason" 1 "Power limited for this reason" 2 "Error" 3 "Not Available" ;
VAL_ 2566605822 TSC1CtrlPurposeP7ReadinessStatus 0 "Not Ready" 1 "Ready" 2 "Error" 3 "Not Available/Not Supported." ;
VAL_ 2499497726 HoistLeverDetentPositionStatus 0 "Not in the Detent Position" 1 "In the Detent Position" 2 "Error Indicator" 3 "Not Available" ;
VAL_ 2633718782 VFSSModule1Detector1DetectorType 0 "Analog thermal sensor" 1 "Analog gas sensor" 2 "Analog optical sensor" 3 "Heat detector" 4 "Manual release switch" 5 "SAE Reserved" 15 "Not available or not installed" ;
VAL_ 2633718782 VFSSModule1Detctr1DetctrDatSLOT 0 "SAEev03 (voltage)" 1 "SAEpc07 (percent)" 2 "SAEtp02 (temperature)" 3 "SAEpr12 (pressure)" 4 "SAE reserved" 15 "Not available or not installed" ;
VAL_ 2633718782 VFSSModule1Detector2DetectorType 0 "Analog thermal sensor" 1 "Analog gas sensor" 2 "Analog optical sensor" 3 "Heat detector" 4 "Manual release switch" 5 "SAE Reserved" 15 "Not available or not installed" ;
VAL_ 2633718782 VFSSModule1Detctr2DetctrDatSLOT 0 "SAEev03 (voltage)" 1 "SAEpc07 (percent)" 2 "SAEtp02 (temperature)" 3 "SAEpr12 (pressure)" 4 "SAE reserved" 15 "Not available or not installed" ;
VAL_ 2633718782 VFSSModule1Detector3DetectorType 0 "Analog thermal sensor" 1 "Analog gas sensor" 2 "Analog optical sensor" 3 "Heat detector" 4 "Manual release switch" 5 "SAE Reserved" 15 "Not available or not installed" ;
VAL_ 2633718782 VFSSModule1Detctr3DetctrDatSLOT 0 "SAEev03 (voltage)" 1 "SAEpc07 (percent)" 2 "SAEtp02 (temperature)" 3 "SAEpr12 (pressure)" 4 "SAE reserved" 15 "Not available or not installed" ;
VAL_ 2633718782 VFSSModule1Detector4DetectorType 0 "Analog thermal sensor" 1 "Analog gas sensor" 2 "Analog optical sensor" 3 "Heat detector" 4 "Manual release switch" 5 "SAE Reserved" 15 "Not available or not installed" ;
VAL_ 2633718782 VFSSModule1Detctr4DetctrDatSLOT 0 "SAEev03 (voltage)" 1 "SAEpc07 (percent)" 2 "SAEtp02 (temperature)" 3 "SAEpr12 (pressure)" 4 "SAE reserved" 15 "Not available or not installed" ;
VAL_ 2633718782 VFSSModule1Detector5DetectorType 0 "Analog thermal sensor" 1 "Analog gas sensor" 2 "Analog optical sensor" 3 "Heat detector" 4 "Manual release switch" 5 "SAE Reserved" 15 "Not available or not installed" ;
VAL_ 2633718782 VFSSModule1Detctr5DetctrDatSLOT 0 "SAEev03 (voltage)" 1 "SAEpc07 (percent)" 2 "SAEtp02 (temperature)" 3 "SAEpr12 (pressure)" 4 "SAE reserved" 15 "Not available or not installed" ;
VAL_ 2633718782 VFSSModule1Detector6DetectorType 0 "Analog thermal sensor" 1 "Analog gas sensor" 2 "Analog optical sensor" 3 "Heat detector" 4 "Manual release switch" 5 "SAE Reserved" 15 "Not available or not installed" ;
VAL_ 2633718782 VFSSModule1Detctr6DetctrDatSLOT 0 "SAEev03 (voltage)" 1 "SAEpc07 (percent)" 2 "SAEtp02 (temperature)" 3 "SAEpr12 (pressure)" 4 "SAE reserved" 15 "Not available or not installed" ;
VAL_ 2633718782 VFSSModule1Detector7DetectorType 0 "Analog thermal sensor" 1 "Analog gas sensor" 2 "Analog optical sensor" 3 "Heat detector" 4 "Manual release switch" 5 "SAE Reserved" 15 "Not available or not installed" ;
VAL_ 2633718782 VFSSModule1Detctr7DetctrDatSLOT 0 "SAEev03 (voltage)" 1 "SAEpc07 (percent)" 2 "SAEtp02 (temperature)" 3 "SAEpr12 (pressure)" 4 "SAE reserved" 15 "Not available or not installed" ;
VAL_ 2633718782 VFSSModule1Detector8DetectorType 0 "Analog thermal sensor" 1 "Analog gas sensor" 2 "Analog optical sensor" 3 "Heat detector" 4 "Manual release switch" 5 "SAE Reserved" 15 "Not available or not installed" ;
VAL_ 2633718782 VFSSModule1Detctr8DetctrDatSLOT 0 "SAEev03 (voltage)" 1 "SAEpc07 (percent)" 2 "SAEtp02 (temperature)" 3 "SAEpr12 (pressure)" 4 "SAE reserved" 15 "Not available or not installed" ;
VAL_ 2633719038 VFSSModule2Detector1DetectorType 0 "Analog thermal sensor" 1 "Analog gas sensor" 2 "Analog optical sensor" 3 "Heat detector" 4 "Manual release switch" 5 "SAE Reserved" 15 "Not available or not installed" ;
VAL_ 2633719038 VFSSModule2Detctr1DetctrDatSLOT 0 "SAEev03 (voltage)" 1 "SAEpc07 (percent)" 2 "SAEtp02 (temperature)" 3 "SAEpr12 (pressure)" 4 "SAE reserved" 15 "Not available or not installed" ;
VAL_ 2633719038 VFSSModule2Detector2DetectorType 0 "Analog thermal sensor" 1 "Analog gas sensor" 2 "Analog optical sensor" 3 "Heat detector" 4 "Manual release switch" 5 "SAE Reserved" 15 "Not available or not installed" ;
VAL_ 2633719038 VFSSModule2Detctr2DetctrDatSLOT 0 "SAEev03 (voltage)" 1 "SAEpc07 (percent)" 2 "SAEtp02 (temperature)" 3 "SAEpr12 (pressure)" 4 "SAE reserved" 15 "Not available or not installed" ;
VAL_ 2633719038 VFSSModule2Detector3DetectorType 0 "Analog thermal sensor" 1 "Analog gas sensor" 2 "Analog optical sensor" 3 "Heat detector" 4 "Manual release switch" 5 "SAE Reserved" 15 "Not available or not installed" ;
VAL_ 2633719038 VFSSModule2Detctr3DetctrDatSLOT 0 "SAEev03 (voltage)" 1 "SAEpc07 (percent)" 2 "SAEtp02 (temperature)" 3 "SAEpr12 (pressure)" 4 "SAE reserved" 15 "Not available or not installed" ;
VAL_ 2633719038 VFSSModule2Detector4DetectorType 0 "Analog thermal sensor" 1 "Analog gas sensor" 2 "Analog optical sensor" 3 "Heat detector" 4 "Manual release switch" 5 "SAE Reserved" 15 "Not available or not installed" ;
VAL_ 2633719038 VFSSModule2Detctr4DetctrDatSLOT 0 "SAEev03 (voltage)" 1 "SAEpc07 (percent)" 2 "SAEtp02 (temperature)" 3 "SAEpr12 (pressure)" 4 "SAE reserved" 15 "Not available or not installed" ;
VAL_ 2633719038 VFSSModule2Detector5DetectorType 0 "Analog thermal sensor" 1 "Analog gas sensor" 2 "Analog optical sensor" 3 "Heat detector" 4 "Manual release switch" 5 "SAE Reserved" 15 "Not available or not installed" ;
VAL_ 2633719038 VFSSModule2Detctr5DetctrDatSLOT 0 "SAEev03 (voltage)" 1 "SAEpc07 (percent)" 2 "SAEtp02 (temperature)" 3 "SAEpr12 (pressure)" 4 "SAE reserved" 15 "Not available or not installed" ;
VAL_ 2633719038 VFSSModule2Detector6DetectorType 0 "Analog thermal sensor" 1 "Analog gas sensor" 2 "Analog optical sensor" 3 "Heat detector" 4 "Manual release switch" 5 "SAE Reserved" 15 "Not available or not installed" ;
VAL_ 2633719038 VFSSModule2Detctr6DetctrDatSLOT 0 "SAEev03 (voltage)" 1 "SAEpc07 (percent)" 2 "SAEtp02 (temperature)" 3 "SAEpr12 (pressure)" 4 "SAE reserved" 15 "Not available or not installed" ;
VAL_ 2633719038 VFSSModule2Detector7DetectorType 0 "Analog thermal sensor" 1 "Analog gas sensor" 2 "Analog optical sensor" 3 "Heat detector" 4 "Manual release switch" 5 "SAE Reserved" 15 "Not available or not installed" ;
VAL_ 2633719038 VFSSModule2Detctr7DetctrDatSLOT 0 "SAEev03 (voltage)" 1 "SAEpc07 (percent)" 2 "SAEtp02 (temperature)" 3 "SAEpr12 (pressure)" 4 "SAE reserved" 15 "Not available or not installed" ;
VAL_ 2633719038 VFSSModule2Detector8DetectorType 0 "Analog thermal sensor" 1 "Analog gas sensor" 2 "Analog optical sensor" 3 "Heat detector" 4 "Manual release switch" 5 "SAE Reserved" 15 "Not available or not installed" ;
VAL_ 2633719038 VFSSModule2Detctr8DetctrDatSLOT 0 "SAEev03 (voltage)" 1 "SAEpc07 (percent)" 2 "SAEtp02 (temperature)" 3 "SAEpr12 (pressure)" 4 "SAE reserved" 15 "Not available or not installed" ;
VAL_ 2633719294 VFSSModule3Detector1DetectorType 0 "Analog thermal sensor" 1 "Analog gas sensor" 2 "Analog optical sensor" 3 "Heat detector" 4 "Manual release switch" 5 "SAE Reserved" 15 "Not available or not installed" ;
VAL_ 2633719294 VFSSModule3Detctr1DetctrDatSLOT 0 "SAEev03 (voltage)" 1 "SAEpc07 (percent)" 2 "SAEtp02 (temperature)" 3 "SAEpr12 (pressure)" 4 "SAE reserved" 15 "Not available or not installed" ;
VAL_ 2633719294 VFSSModule3Detector2DetectorType 0 "Analog thermal sensor" 1 "Analog gas sensor" 2 "Analog optical sensor" 3 "Heat detector" 4 "Manual release switch" 5 "SAE Reserved" 15 "Not available or not installed" ;
VAL_ 2633719294 VFSSModule3Detctr2DetctrDatSLOT 0 "SAEev03 (voltage)" 1 "SAEpc07 (percent)" 2 "SAEtp02 (temperature)" 3 "SAEpr12 (pressure)" 4 "SAE reserved" 15 "Not available or not installed" ;
VAL_ 2633719294 VFSSModule3Detector3DetectorType 0 "Analog thermal sensor" 1 "Analog gas sensor" 2 "Analog optical sensor" 3 "Heat detector" 4 "Manual release switch" 5 "SAE Reserved" 15 "Not available or not installed" ;
VAL_ 2633719294 VFSSModule3Detctr3DetctrDatSLOT 0 "SAEev03 (voltage)" 1 "SAEpc07 (percent)" 2 "SAEtp02 (temperature)" 3 "SAEpr12 (pressure)" 4 "SAE reserved" 15 "Not available or not installed" ;
VAL_ 2633719294 VFSSModule3Detector4DetectorType 0 "Analog thermal sensor" 1 "Analog gas sensor" 2 "Analog optical sensor" 3 "Heat detector" 4 "Manual release switch" 5 "SAE Reserved" 15 "Not available or not installed" ;
VAL_ 2633719294 VFSSModule3Detctr4DetctrDatSLOT 0 "SAEev03 (voltage)" 1 "SAEpc07 (percent)" 2 "SAEtp02 (temperature)" 3 "SAEpr12 (pressure)" 4 "SAE reserved" 15 "Not available or not installed" ;
VAL_ 2633719294 VFSSModule3Detector5DetectorType 0 "Analog thermal sensor" 1 "Analog gas sensor" 2 "Analog optical sensor" 3 "Heat detector" 4 "Manual release switch" 5 "SAE Reserved" 15 "Not available or not installed" ;
VAL_ 2633719294 VFSSModule3Detctr5DetctrDatSLOT 0 "SAEev03 (voltage)" 1 "SAEpc07 (percent)" 2 "SAEtp02 (temperature)" 3 "SAEpr12 (pressure)" 4 "SAE reserved" 15 "Not available or not installed" ;
VAL_ 2633719294 VFSSModule3Detector6DetectorType 0 "Analog thermal sensor" 1 "Analog gas sensor" 2 "Analog optical sensor" 3 "Heat detector" 4 "Manual release switch" 5 "SAE Reserved" 15 "Not available or not installed" ;
VAL_ 2633719294 VFSSModule3Detctr6DetctrDatSLOT 0 "SAEev03 (voltage)" 1 "SAEpc07 (percent)" 2 "SAEtp02 (temperature)" 3 "SAEpr12 (pressure)" 4 "SAE reserved" 15 "Not available or not installed" ;
VAL_ 2633719294 VFSSModule3Detector7DetectorType 0 "Analog thermal sensor" 1 "Analog gas sensor" 2 "Analog optical sensor" 3 "Heat detector" 4 "Manual release switch" 5 "SAE Reserved" 15 "Not available or not installed" ;
VAL_ 2633719294 VFSSModule3Detctr7DetctrDatSLOT 0 "SAEev03 (voltage)" 1 "SAEpc07 (percent)" 2 "SAEtp02 (temperature)" 3 "SAEpr12 (pressure)" 4 "SAE reserved" 15 "Not available or not installed" ;
VAL_ 2633719294 VFSSModule3Detector8DetectorType 0 "Analog thermal sensor" 1 "Analog gas sensor" 2 "Analog optical sensor" 3 "Heat detector" 4 "Manual release switch" 5 "SAE Reserved" 15 "Not available or not installed" ;
VAL_ 2633719294 VFSSModule3Detctr8DetctrDatSLOT 0 "SAEev03 (voltage)" 1 "SAEpc07 (percent)" 2 "SAEtp02 (temperature)" 3 "SAEpr12 (pressure)" 4 "SAE reserved" 15 "Not available or not installed" ;
VAL_ 2633719550 VFSSModule4Detector1DetectorType 0 "Analog thermal sensor" 1 "Analog gas sensor" 2 "Analog optical sensor" 3 "Heat detector" 4 "Manual release switch" 5 "SAE Reserved" 15 "Not available or not installed" ;
VAL_ 2633719550 VFSSModule4Detctr1DetctrDatSLOT 0 "SAEev03 (voltage)" 1 "SAEpc07 (percent)" 2 "SAEtp02 (temperature)" 3 "SAEpr12 (pressure)" 4 "SAE reserved" 15 "Not available or not installed" ;
VAL_ 2633719550 VFSSModule4Detector2DetectorType 0 "Analog thermal sensor" 1 "Analog gas sensor" 2 "Analog optical sensor" 3 "Heat detector" 4 "Manual release switch" 5 "SAE Reserved" 15 "Not available or not installed" ;
VAL_ 2633719550 VFSSModule4Detctr2DetctrDatSLOT 0 "SAEev03 (voltage)" 1 "SAEpc07 (percent)" 2 "SAEtp02 (temperature)" 3 "SAEpr12 (pressure)" 4 "SAE reserved" 15 "Not available or not installed" ;
VAL_ 2633719550 VFSSModule4Detector3DetectorType 0 "Analog thermal sensor" 1 "Analog gas sensor" 2 "Analog optical sensor" 3 "Heat detector" 4 "Manual release switch" 5 "SAE Reserved" 15 "Not available or not installed" ;
VAL_ 2633719550 VFSSModule4Detctr3DetctrDatSLOT 0 "SAEev03 (voltage)" 1 "SAEpc07 (percent)" 2 "SAEtp02 (temperature)" 3 "SAEpr12 (pressure)" 4 "SAE reserved" 15 "Not available or not installed" ;
VAL_ 2633719550 VFSSModule4Detector4DetectorType 0 "Analog thermal sensor" 1 "Analog gas sensor" 2 "Analog optical sensor" 3 "Heat detector" 4 "Manual release switch" 5 "SAE Reserved" 15 "Not available or not installed" ;
VAL_ 2633719550 VFSSModule4Detctr4DetctrDatSLOT 0 "SAEev03 (voltage)" 1 "SAEpc07 (percent)" 2 "SAEtp02 (temperature)" 3 "SAEpr12 (pressure)" 4 "SAE reserved" 15 "Not available or not installed" ;
VAL_ 2633719550 VFSSModule4Detector5DetectorType 0 "Analog thermal sensor" 1 "Analog gas sensor" 2 "Analog optical sensor" 3 "Heat detector" 4 "Manual release switch" 5 "SAE Reserved" 15 "Not available or not installed" ;
VAL_ 2633719550 VFSSModule4Detctr5DetctrDatSLOT 0 "SAEev03 (voltage)" 1 "SAEpc07 (percent)" 2 "SAEtp02 (temperature)" 3 "SAEpr12 (pressure)" 4 "SAE reserved" 15 "Not available or not installed" ;
VAL_ 2633719550 VFSSModule4Detector6DetectorType 0 "Analog thermal sensor" 1 "Analog gas sensor" 2 "Analog optical sensor" 3 "Heat detector" 4 "Manual release switch" 5 "SAE Reserved" 15 "Not available or not installed" ;
VAL_ 2633719550 VFSSModule4Detctr6DetctrDatSLOT 0 "SAEev03 (voltage)" 1 "SAEpc07 (percent)" 2 "SAEtp02 (temperature)" 3 "SAEpr12 (pressure)" 4 "SAE reserved" 15 "Not available or not installed" ;
VAL_ 2633719550 VFSSModule4Detector7DetectorType 0 "Analog thermal sensor" 1 "Analog gas sensor" 2 "Analog optical sensor" 3 "Heat detector" 4 "Manual release switch" 5 "SAE Reserved" 15 "Not available or not installed" ;
VAL_ 2633719550 VFSSModule4Detctr7DetctrDatSLOT 0 "SAEev03 (voltage)" 1 "SAEpc07 (percent)" 2 "SAEtp02 (temperature)" 3 "SAEpr12 (pressure)" 4 "SAE reserved" 15 "Not available or not installed" ;
VAL_ 2633719550 VFSSModule4Detector8DetectorType 0 "Analog thermal sensor" 1 "Analog gas sensor" 2 "Analog optical sensor" 3 "Heat detector" 4 "Manual release switch" 5 "SAE Reserved" 15 "Not available or not installed" ;
VAL_ 2633719550 VFSSModule4Detctr8DetctrDatSLOT 0 "SAEev03 (voltage)" 1 "SAEpc07 (percent)" 2 "SAEtp02 (temperature)" 3 "SAEpr12 (pressure)" 4 "SAE reserved" 15 "Not available or not installed" ;
VAL_ 2566612990 MtrGen2InvPwrLmtedDTUndefndRsn 0 "No power limit for this reason" 1 "Power limited for this reason" 2 "Error" 3 "Not Available" ;
VAL_ 2566612990 MtrGen2InvPwrLmtedDTDCSdeCurMax 0 "No power limit for this reason" 1 "Power limited for this reason" 2 "Error" 3 "Not Available" ;
VAL_ 2566612990 MtrGen2InvPwrLmtedDTDCSdeCurMin 0 "No power limit for this reason" 1 "Power limited for this reason" 2 "Error" 3 "Not Available" ;
VAL_ 2566612990 MtrGen2InvPwrLmtedDTDCSdeVltgMax 0 "No power limit for this reason" 1 "Power limited for this reason" 2 "Error" 3 "Not Available" ;
VAL_ 2566612990 MtrGen2InvPwrLmtedDTDCSdeVltgMin 0 "No power limit for this reason" 1 "Power limited for this reason" 2 "Error" 3 "Not Available" ;
VAL_ 2566612990 MtrGen2InvPwrLmtDTMechnclPwrMax 0 "No power limit for this reason" 1 "Power limited for this reason" 2 "Error" 3 "Not Available" ;
VAL_ 2566612990 MtrGen2InvPwrLmtDTMechnclPwrMin 0 "No power limit for this reason" 1 "Power limited for this reason" 2 "Error" 3 "Not Available" ;
VAL_ 2566612990 MtrGen2InvPwrLmtedDTDCSdePwrMax 0 "No power limit for this reason" 1 "Power limited for this reason" 2 "Error" 3 "Not Available" ;
VAL_ 2566612990 MtrGen2InvPwrLmtedDTDCSdePwrMin 0 "No power limit for this reason" 1 "Power limited for this reason" 2 "Error" 3 "Not Available" ;
VAL_ 2566612990 MtrGen2InvertPwrLmtedDTTorqueMax 0 "No power limit for this reason" 1 "Power limited for this reason" 2 "Error" 3 "Not Available" ;
VAL_ 2566612990 MtrGen2InvertPwrLmtedDTTorqueMin 0 "No power limit for this reason" 1 "Power limited for this reason" 2 "Error" 3 "Not Available" ;
VAL_ 2566612990 MtrGen2InvertPwrLmtedDTSpeedMax 0 "No power limit for this reason" 1 "Power limited for this reason" 2 "Error" 3 "Not Available" ;
VAL_ 2566612990 MtrGen2InvertPwrLmtedDTSpeedMin 0 "No power limit for this reason" 1 "Power limited for this reason" 2 "Error" 3 "Not Available" ;
VAL_ 2566612990 MtrGen2InvPwrLmtedDTInvertTemp 0 "No power limit for this reason" 1 "Power limited for this reason" 2 "Error" 3 "Not Available" ;
VAL_ 2566612990 MtrGen2InvertPwrLmtedDTMtrTemp 0 "No power limit for this reason" 1 "Power limited for this reason" 2 "Error" 3 "Not Available" ;
VAL_ 2566613246 MtrGen2InvHiVltgBusActIsoltnTtSt 0 "No test requested / No test in process" 1 "Test requested but not yet in process" 2 "Test in process" 3 "Test complete - isolation acceptable" 4 "Test complete - isolation marginal" 5 "Test complete - isolation fault" 6 "Active Isolation Test Inhibited" 7 "Reserved" 14 "Error" 15 "Not available" ;
VAL_ 2566613246 MtrGen2InvHiVBusPassIsoltnTtSt 0 "No test requested / No test in process" 1 "Test requested but not yet in process" 2 "Test in process" 3 "Test complete - isolation acceptable" 4 "Test complete - isolation marginal" 5 "Test complete - isolation fault" 6 "Passive Isolation Test Inhibited" 7 "Reserved" 14 "Error" 15 "Not available" ;
VAL_ 2566613502 MtrGen1InvPwrLmtedDTUndefndRsn 0 "No power limit for this reason" 1 "Power limited for this reason" 2 "Error" 3 "Not Available" ;
VAL_ 2566613502 MtrGen1InvPwrLmtedDTDCSdeCurMax 0 "No power limit for this reason" 1 "Power limited for this reason" 2 "Error" 3 "Not Available" ;
VAL_ 2566613502 MtrGen1InvPwrLmtedDTDCSdeCurMin 0 "No power limit for this reason" 1 "Power limited for this reason" 2 "Error" 3 "Not Available" ;
VAL_ 2566613502 MtrGen1InvPwrLmtedDTDCSdeVltgMax 0 "No power limit for this reason" 1 "Power limited for this reason" 2 "Error" 3 "Not Available" ;
VAL_ 2566613502 MtrGen1InvPwrLmtedDTDCSdeVltgMin 0 "No power limit for this reason" 1 "Power limited for this reason" 2 "Error" 3 "Not Available" ;
VAL_ 2566613502 MtrGen1InvPwrLmtDTMechnclPwrMax 0 "No power limit for this reason" 1 "Power limited for this reason" 2 "Error" 3 "Not Available" ;
VAL_ 2566613502 MtrGen1InvPwrLmtDTMechnclPwrMin 0 "No power limit for this reason" 1 "Power limited for this reason" 2 "Error" 3 "Not Available" ;
VAL_ 2566613502 MtrGen1InvPwrLmtedDTDCSdePwrMax 0 "No power limit for this reason" 1 "Power limited for this reason" 2 "Error" 3 "Not Available" ;
VAL_ 2566613502 MtrGen1InvPwrLmtedDTDCSdePwrMin 0 "No power limit for this reason" 1 "Power limited for this reason" 2 "Error" 3 "Not Available" ;
VAL_ 2566613502 MtrGen1InvertPwrLmtedDTTorqueMax 0 "No power limit for this reason" 1 "Power limited for this reason" 2 "Error" 3 "Not Available" ;
VAL_ 2566613502 MtrGen1InvertPwrLmtedDTTorqueMin 0 "No power limit for this reason" 1 "Power limited for this reason" 2 "Error" 3 "Not Available" ;
VAL_ 2566613502 MtrGen1InvertPwrLmtedDTSpeedMax 0 "No power limit for this reason" 1 "Power limited for this reason" 2 "Error" 3 "Not Available" ;
VAL_ 2566613502 MtrGen1InvertPwrLmtedDTSpeedMin 0 "No power limit for this reason" 1 "Power limited for this reason" 2 "Error" 3 "Not Available" ;
VAL_ 2566613502 MtrGen1InvPwrLmtedDTInvertTemp 0 "No power limit for this reason" 1 "Power limited for this reason" 2 "Error" 3 "Not Available" ;
VAL_ 2566613502 MtrGen1InvertPwrLmtedDTMtrTemp 0 "No power limit for this reason" 1 "Power limited for this reason" 2 "Error" 3 "Not Available" ;
VAL_ 2566613758 MtrGen1InvHiVltgBusActIsoltnTtSt 0 "No test requested / No test in process" 1 "Test requested but not yet in process" 2 "Test in process" 3 "Test complete - isolation acceptable" 4 "Test complete - isolation marginal" 5 "Test complete - isolation fault" 6 "Active Isolation Test Inhibited" 7 "Reserved" 14 "Error" 15 "Not available" ;
VAL_ 2566613758 MtrGen1InvHiVBusPassIsoltnTtSt 0 "No test requested / No test in process" 1 "Test requested but not yet in process" 2 "Test in process" 3 "Test complete - isolation acceptable" 4 "Test complete - isolation marginal" 5 "Test complete - isolation fault" 6 "Passive Isolation Test Inhibited" 7 "Reserved" 14 "Error" 15 "Not available" ;
VAL_ 2566614014 HighVoltageDCBusAvailability 0 "High voltage DC bus is not connected to any power source." 1 "High voltage DC bus is connected to at least one power source." 2 "High voltage DC bus connection is in process of being connected to at least one power source." 3 "High voltage DC bus disconnection is in process." 4 "SAE Reserved" 5 "High voltage DC bus disconnect forewarning." 6 "SAE Reserved" 14 "Error" 15 "Not Available" ;
VAL_ 2566616830 ZoneAlarmStatus1 0 "No Alarm Active" 1 "Alarm Active" 2 "Reserved for SAE assignment" 3 "Reserved for SAE assignment" 4 "Reserved for SAE assignment" 5 "Reserved for SAE assignment" 6 "Reserved for SAE assignment" 7 "Reserved for SAE assignment" 8 "Reserved for SAE assignment" 9 "Reserved for SAE assignment" 10 "Reserved for SAE assignment" 11 "Reserved for SAE assignment" 12 "Reserved for SAE assignment" 13 "Reserved for SAE assignment" 14 "Error Indicator" 15 "Not Available or Not Installed" ;
VAL_ 2566616830 ZoneAlarmStatus2 0 "No Alarm Active" 1 "Alarm Active" 2 "Reserved for SAE assignment" 3 "Reserved for SAE assignment" 4 "Reserved for SAE assignment" 5 "Reserved for SAE assignment" 6 "Reserved for SAE assignment" 7 "Reserved for SAE assignment" 8 "Reserved for SAE assignment" 9 "Reserved for SAE assignment" 10 "Reserved for SAE assignment" 11 "Reserved for SAE assignment" 12 "Reserved for SAE assignment" 13 "Reserved for SAE assignment" 14 "Error Indicator" 15 "Not Available or Not Installed" ;
VAL_ 2566616830 ZoneAlarmStatus3 0 "No Alarm Active" 1 "Alarm Active" 2 "Reserved for SAE assignment" 3 "Reserved for SAE assignment" 4 "Reserved for SAE assignment" 5 "Reserved for SAE assignment" 6 "Reserved for SAE assignment" 7 "Reserved for SAE assignment" 8 "Reserved for SAE assignment" 9 "Reserved for SAE assignment" 10 "Reserved for SAE assignment" 11 "Reserved for SAE assignment" 12 "Reserved for SAE assignment" 13 "Reserved for SAE assignment" 14 "Error Indicator" 15 "Not Available or Not Installed" ;
VAL_ 2566618622 GeneratorCoolantPumpEnableStatus 0 "Accessory Motor Off" 1 "Accessory Motor On" 2 "Accessory Motor On" 3 "Not available" ;
VAL_ 2566618622 GenCoolntPmpCtrllerStatusRsnCd 0 "Normal Operation" 1 "Unable to Start" 2 "Over-Voltage Protection Shutdown" 3 "Under-Voltage Protection Shutdown" 4 "Over-Temperature Protection Shutdown" 5 "Speed Limited due to current protection limit" 6 "Speed limited due to maximum system design capability" 7 "Speed limited due to torque limit" 8 "Speed limited due to over-temperature protection" 9 "Reserved" 10 "Reserved" 11 "Reserved" 12 "Reserved" 13 "Reserved" 14 "Reserved" 15 "Not Available" ;
VAL_ 2566618622 GenCoolntPumpCtrllerCmdStatus 0 "Internal Command" 1 "External Command" 2 "Default Command" 3 "Not Available" ;
VAL_ 2566618622 GenCoolntPumpServiceIndicator 0 "Service Not Required" 1 "Service Required" 2 "Reserved" 3 "Not Available" ;
VAL_ 2566618622 GenCoolntPumpOperatingStatus 0 "Normal Operation" 1 "Derated Operation" 2 "Not Operable" 3 "Not Available" ;
VAL_ 2566618878 GeneratorCoolantFanEnableStatus 0 "Accessory Motor Off" 1 "Accessory Motor On" 2 "Accessory Motor On" 3 "Not available" ;
VAL_ 2566618878 GenCoolntFnCtrllerStatusReasonCd 0 "Normal Operation" 1 "Unable to Start" 2 "Over-Voltage Protection Shutdown" 3 "Under-Voltage Protection Shutdown" 4 "Over-Temperature Protection Shutdown" 5 "Speed Limited due to current protection limit" 6 "Speed limited due to maximum system design capability" 7 "Speed limited due to torque limit" 8 "Speed limited due to over-temperature protection" 9 "Reserved" 10 "Reserved" 11 "Reserved" 12 "Reserved" 13 "Reserved" 14 "Reserved" 15 "Not Available" ;
VAL_ 2566618878 GenCoolntFnCtrllerCmdStatus 0 "Internal Command" 1 "External Command" 2 "Default Command" 3 "Not Available" ;
VAL_ 2566618878 GenCoolntFnServiceIndicator 0 "Service Not Required" 1 "Service Required" 2 "Reserved" 3 "Not Available" ;
VAL_ 2566618878 GeneratorCoolntFnOperatingStatus 0 "Normal Operation" 1 "Derated Operation" 2 "Not Operable" 3 "Not Available" ;
VAL_ 2566619134 WllStimultnPmpOilFltrBypssSwStat 0 "Not bypassing" 1 "Bypassing" 2 "Error" 3 "Not available" ;
VAL_ 2566619646 OnBoardProgrammingInitRequest 0 "On board programming not requested" 1 "Initiation of on board programming is requested" 2 "Reserved" 3 "Don't care/take no action" ;
VAL_ 2566619646 OnBoardProgrammingInitiateInhbt 0 "Programming is not inhibited" 1 "Programming is inhibited" 2 "Reserved" 3 "Don't care/take no action" ;
VAL_ 2566620670 EngineIdleManagementStatus 0 "Off" 1 "Locked" 2 "Disabled" 3 "Activation conditions not met" 4 "Shutdown conditions not met" 5 "Shutdown conditions pending" 6 "Shutdown" 7 "Restart conditions not met" 8 "Restart conditions pending" 9 "Auto start inhibited" 10 "Reserved" 11 "Reserved" 12 "Reserved" 13 "Reserved" 14 "Error" 15 "Not Available" ;
VAL_ 2566620670 EngIdleManagementRestartReason 0 "Operator input request" 1 "Low engine coolant temperature" 2 "Low SLI battery voltage" 3 "Low transmission oil temperature" 4 "Low power end lube oil temperature" 5 "Low SLI battery pack #1 state of charge" 6 "Low SLI battery pack #2 state of charge" 7 "Failure of one or more components" 8 "Reserved" 9 "Reserved" 10 "Reserved" 11 "Reserved" 12 "Reserved" 13 "Reserved" 14 "Error" 15 "Not available" ;
VAL_ 2566620670 EngIdleManagementShutdownReason 0 "Operator input request" 1 "Engine coolant temperature" 2 "SLI Battery voltage" 3 "Transmission oil temperature" 4 "Power end lube oil temperature" 5 "SLI Battery pack #1 state of charge" 6 "SLI Battery pack #2 state of charge" 7 "Engine exhaust temperature" 8 "Ambient temperature" 9 "Engine idle reduction system failure" 10 "Reserved" 11 "Reserved" 12 "Reserved" 13 "Reserved" 14 "Error" 15 "Not available" ;
VAL_ 2566621438 StationThrottlePositionMatch 0 "Throttle positions do not match" 1 "Throttle positions match" 2 "Error" 3 "Not Available or Not Installed" ;
VAL_ 2566621438 StationGearPositionMatch 0 "Neutral" 1 "Not in neutral" 2 "Error" 3 "Not Available or Not Installed" ;
VAL_ 2566621438 OperatorStationActvButtonStatus 0 "Button not pressed" 1 "Button pressed" 2 "Error" 3 "Not Available" ;
VAL_ 2566621438 TrollingModeButtonStatus 0 "Button not pressed" 1 "Button pressed" 2 "Error" 3 "Not Available" ;
VAL_ 2566621438 EngThrottleLvrSyncButtonStat 0 "Button not pressed" 1 "Button pressed" 2 "Error" 3 "Not Available" ;
VAL_ 2566621438 GearLockoutButtonStatus 0 "Button not pressed" 1 "Button pressed" 2 "Error" 3 "Not Available" ;
VAL_ 2566621438 SlowVesselModeButtonStatus 0 "Button not pressed" 1 "Button pressed" 2 "Error" 3 "Not Available" ;
VAL_ 2566621438 OperatorStationActiveLampStatus 0 "Off" 1 "On" 2 "Error" 3 "Not available" ;
VAL_ 2566621438 TrollingModeLampStatus 0 "Off" 1 "On" 2 "Error" 3 "Not available" ;
VAL_ 2566621438 EngThrottleLvrSyncLampStat 0 "Off" 1 "On" 2 "Error" 3 "Not available" ;
VAL_ 2566621438 GearLockoutLampStatus 0 "Off" 1 "On" 2 "Error" 3 "Not available" ;
VAL_ 2566621438 SlowVesselModeLampStatus 0 "Off" 1 "On" 2 "Error" 3 "Not available" ;
VAL_ 2566621438 MarineHeavySeaModeEnable 0 "Marine heavy sea mode is disabled" 1 "Marine heavy sea mode is enabled" 2 "Reserved" 3 "Take no action" ;
VAL_ 2566632190 WllStimultnPmpSuctPrsClbrtnSetPt 0 "Zero Point" 1 "Calibration Reference Point 1" 2 "Calibration Reference Point 2" 3 "Calibration Reference Point 3" 4 "Calibration Reference Point 4" 5 "Calibration Reference Point 5" 6 "Calibration Reference Point 6" 7 "Calibration Reference Point 7" 8 "Calibration Reference Point 8" 9 "Calibration Reference Point 9" 10 "End Point" 11 "Correction Point" 12 "Reset Calibration" 13 "Reserved" 14 "Error" 15 "Not Available" ;
VAL_ 2566632190 WllStimuPmpSuctPrsClbrtnSetPtSt 0 "Not OK" 1 "OK" 2 "Error" 3 "Not available" ;
VAL_ 2566632190 WllStimuPmpDisChrgPrsClbrtnSetPt 0 "Zero Point" 1 "Calibration Reference Point 1" 2 "Calibration Reference Point 2" 3 "Calibration Reference Point 3" 4 "Calibration Reference Point 4" 5 "Calibration Reference Point 5" 6 "Calibration Reference Point 6" 7 "Calibration Reference Point 7" 8 "Calibration Reference Point 8" 9 "Calibration Reference Point 9" 10 "End Point" 11 "Correction Point" 12 "Reset Calibration" 13 "Reserved" 14 "Error" 15 "Not Available" ;
VAL_ 2566632190 WStimuPmpDisChrgPrsClbrtnSetPtSt 0 "Not OK" 1 "OK" 2 "Error" 3 "Not available" ;
VAL_ 2566639102 WellStimPmpPlungerFiringOrderStt 0 "Firing order 1-2-3" 1 "Firing order 1-5-2-3-4" 2 "Reserved" 14 "Error" 15 "Not available" ;
VAL_ 2633748222 ReceiveSPNsPort 0 "Current port" 1 "Port 1" 2 "Port 2" 3 "Port 3" 4 "Port 4" 5 "Port 5" 6 "Port 6" 7 "Port 7" 8 "Port 8" 9 "Port 9" 10 "Port 10" 11 "SAE Reserved" ;
VAL_ 2633748222 ReceiveSPNsPortPendingChangesSt 0 "No pending changes" 1 "Receive changes are pending" ;
VAL_ 2633748222 ReceiveSPNsPortCommandStatus 0 "Positive Acknowledgment" 1 "Negative Acknowledgment" 2 "No Configurable SPNs exist" 3 "SAE Reserved" 7 "Not available" ;
VAL_ 2633748222 ConfigurableReceiveSPNModifiedSt 0 "SPN's receive status could not be modified." 1 "SPN's receive status was not requested to be modified." 2 "SPN's receive status could be modified as requested." 3 "Not available" ;
VAL_ 2633750526 TransmitPGNsPort 0 "Current port" 1 "Port 1" 2 "Port 2" 3 "Port 3" 4 "Port 4" 5 "Port 5" 6 "Port 6" 7 "Port 7" 8 "Port 8" 9 "Port 9" 10 "Port 10" 11 "SAE Reserved" ;
VAL_ 2633750526 TransmitPGNsPortPendingChangesSt 0 "No pending changes" 1 "Transmit changes are pending" ;
VAL_ 2633750526 TransmitPGNsPortCommandStatus 0 "Positive Acknowledgment" 1 "Negative Acknowledgment" 2 "No Configurable PGNs exist" 3 "SAE Reserved" 7 "Not Available" ;
VAL_ 2633750526 ConfigurableTransPGNCurTransmtSt 0 "PGN is currently configured for transmit" 1 "PGN is not currently configured for transmit" 2 "The PGN transmit capability cannot be modified" 3 "Not Available" ;
VAL_ 2633750526 ConfigurableTransPGNPendngChgSt 0 "Pending transmit change to disable" 1 "Pending transmit change to enable" 2 "No pending transmit change" 3 "Not Available" ;
VAL_ 2633750526 ConfigurableTransmtPGNModifiedSt 0 "PGN's transmit status could not be modified" 1 "PGN's transmit status was not requested to be modified" 2 "PGN's transmit status could be modified as requested" 3 "Not Available" ;
VAL_ 2566642686 TestIdentifier 0 "Reserved for SAE Assignment" 1 "Command Manufacturer Specific Test" 65 "Reserved for SAE Assignment" 245 "Return rationality fault SPN data value" 246 "Return all scaled test results for all SPNs" 247 "Return all scaled test results for one SPN" 248 "Command Manufacturer Specific Test" 249 "Command Standard Test" 250 "Return Last Measured Scaled Results" ;
VAL_ 2566642942 LockStatusOfDoor21 0 "Unlocked" 1 "Locked" 2 "Error" 3 "Not available" ;
VAL_ 2566642942 OpenStatusOfDoor21 0 "Door closed" 1 "Door opened" 2 "Error" 3 "Not available" ;
VAL_ 2566642942 EnableStatusOfDoor21 0 "Door disabled" 1 "Door enabled" 2 "Error" 3 "Not available" ;
VAL_ 2566642942 LockStatusOfDoor22 0 "Unlocked" 1 "Locked" 2 "Error" 3 "Not available" ;
VAL_ 2566642942 OpenStatusOfDoor22 0 "Door closed" 1 "Door opened" 2 "Error" 3 "Not available" ;
VAL_ 2566642942 EnableStatusOfDoor22 0 "Door disabled" 1 "Door enabled" 2 "Error" 3 "Not available" ;
VAL_ 2566642942 LockStatusOfDoor23 0 "Unlocked" 1 "Locked" 2 "Error" 3 "Not available" ;
VAL_ 2566642942 OpenStatusOfDoor23 0 "Door closed" 1 "Door opened" 2 "Error" 3 "Not available" ;
VAL_ 2566642942 EnableStatusOfDoor23 0 "Door disabled" 1 "Door enabled" 2 "Error" 3 "Not available" ;
VAL_ 2566642942 LockStatusOfDoor24 0 "Unlocked" 1 "Locked" 2 "Error" 3 "Not available" ;
VAL_ 2566642942 OpenStatusOfDoor24 0 "Door closed" 1 "Door opened" 2 "Error" 3 "Not available" ;
VAL_ 2566642942 EnableStatusOfDoor24 0 "Door disabled" 1 "Door enabled" 2 "Error" 3 "Not available" ;
VAL_ 2566642942 LockStatusOfDoor25 0 "Unlocked" 1 "Locked" 2 "Error" 3 "Not available" ;
VAL_ 2566642942 OpenStatusOfDoor25 0 "Door closed" 1 "Door opened" 2 "Error" 3 "Not available" ;
VAL_ 2566642942 EnableStatusOfDoor25 0 "Door disabled" 1 "Door enabled" 2 "Error" 3 "Not available" ;
VAL_ 2566642942 LockStatusOfDoor26 0 "Unlocked" 1 "Locked" 2 "Error" 3 "Not available" ;
VAL_ 2566642942 OpenStatusOfDoor26 0 "Door closed" 1 "Door opened" 2 "Error" 3 "Not available" ;
VAL_ 2566642942 EnableStatusOfDoor26 0 "Door disabled" 1 "Door enabled" 2 "Error" 3 "Not available" ;
VAL_ 2566642942 LockStatusOfDoor27 0 "Unlocked" 1 "Locked" 2 "Error" 3 "Not available" ;
VAL_ 2566642942 OpenStatusOfDoor27 0 "Door closed" 1 "Door opened" 2 "Error" 3 "Not available" ;
VAL_ 2566642942 EnableStatusOfDoor27 0 "Door disabled" 1 "Door enabled" 2 "Error" 3 "Not available" ;
VAL_ 2566642942 LockStatusOfDoor28 0 "Unlocked" 1 "Locked" 2 "Error" 3 "Not available" ;
VAL_ 2566642942 OpenStatusOfDoor28 0 "Door closed" 1 "Door opened" 2 "Error" 3 "Not available" ;
VAL_ 2566642942 EnableStatusOfDoor28 0 "Door disabled" 1 "Door enabled" 2 "Error" 3 "Not available" ;
VAL_ 2566642942 LockStatusOfDoor29 0 "Unlocked" 1 "Locked" 2 "Error" 3 "Not available" ;
VAL_ 2566642942 OpenStatusOfDoor29 0 "Door closed" 1 "Door opened" 2 "Error" 3 "Not available" ;
VAL_ 2566642942 EnableStatusOfDoor29 0 "Door disabled" 1 "Door enabled" 2 "Error" 3 "Not available" ;
VAL_ 2566642942 LockStatusOfDoor30 0 "Unlocked" 1 "Locked" 2 "Error" 3 "Not available" ;
VAL_ 2566642942 OpenStatusOfDoor30 0 "Door closed" 1 "Door opened" 2 "Error" 3 "Not available" ;
VAL_ 2566642942 EnableStatusOfDoor30 0 "Door disabled" 1 "Door enabled" 2 "Error" 3 "Not available" ;
VAL_ 2566643198 LockStatusOfDoor11 0 "Unlocked" 1 "Locked" 2 "Error" 3 "Not available" ;
VAL_ 2566643198 OpenStatusOfDoor11 0 "Door closed" 1 "Door opened" 2 "Error" 3 "Not available" ;
VAL_ 2566643198 EnableStatusOfDoor11 0 "Door disabled" 1 "Door enabled" 2 "Error" 3 "Not available" ;
VAL_ 2566643198 LockStatusOfDoor12 0 "Unlocked" 1 "Locked" 2 "Error" 3 "Not available" ;
VAL_ 2566643198 OpenStatusOfDoor12 0 "Door closed" 1 "Door opened" 2 "Error" 3 "Not available" ;
VAL_ 2566643198 EnableStatusOfDoor12 0 "Door disabled" 1 "Door enabled" 2 "Error" 3 "Not available" ;
VAL_ 2566643198 LockStatusOfDoor13 0 "Unlocked" 1 "Locked" 2 "Error" 3 "Not available" ;
VAL_ 2566643198 OpenStatusOfDoor13 0 "Door closed" 1 "Door opened" 2 "Error" 3 "Not available" ;
VAL_ 2566643198 EnableStatusOfDoor13 0 "Door disabled" 1 "Door enabled" 2 "Error" 3 "Not available" ;
VAL_ 2566643198 LockStatusOfDoor14 0 "Unlocked" 1 "Locked" 2 "Error" 3 "Not available" ;
VAL_ 2566643198 OpenStatusOfDoor14 0 "Door closed" 1 "Door opened" 2 "Error" 3 "Not available" ;
VAL_ 2566643198 EnableStatusOfDoor14 0 "Door disabled" 1 "Door enabled" 2 "Error" 3 "Not available" ;
VAL_ 2566643198 LockStatusOfDoor15 0 "Unlocked" 1 "Locked" 2 "Error" 3 "Not available" ;
VAL_ 2566643198 OpenStatusOfDoor15 0 "Door closed" 1 "Door opened" 2 "Error" 3 "Not available" ;
VAL_ 2566643198 EnableStatusOfDoor15 0 "Door disabled" 1 "Door enabled" 2 "Error" 3 "Not available" ;
VAL_ 2566643198 LockStatusOfDoor16 0 "Unlocked" 1 "Locked" 2 "Error" 3 "Not available" ;
VAL_ 2566643198 OpenStatusOfDoor16 0 "Door closed" 1 "Door opened" 2 "Error" 3 "Not available" ;
VAL_ 2566643198 EnableStatusOfDoor16 0 "Door disabled" 1 "Door enabled" 2 "Error" 3 "Not available" ;
VAL_ 2566643198 LockStatusOfDoor17 0 "Unlocked" 1 "Locked" 2 "Error" 3 "Not available" ;
VAL_ 2566643198 OpenStatusOfDoor17 0 "Door closed" 1 "Door opened" 2 "Error" 3 "Not available" ;
VAL_ 2566643198 EnableStatusOfDoor17 0 "Door disabled" 1 "Door enabled" 2 "Error" 3 "Not available" ;
VAL_ 2566643198 LockStatusOfDoor18 0 "Unlocked" 1 "Locked" 2 "Error" 3 "Not available" ;
VAL_ 2566643198 OpenStatusOfDoor18 0 "Door closed" 1 "Door opened" 2 "Error" 3 "Not available" ;
VAL_ 2566643198 EnableStatusOfDoor18 0 "Door disabled" 1 "Door enabled" 2 "Error" 3 "Not available" ;
VAL_ 2566643198 LockStatusOfDoor19 0 "Unlocked" 1 "Locked" 2 "Error" 3 "Not available" ;
VAL_ 2566643198 OpenStatusOfDoor19 0 "Door closed" 1 "Door opened" 2 "Error" 3 "Not available" ;
VAL_ 2566643198 EnableStatusOfDoor19 0 "Door disabled" 1 "Door enabled" 2 "Error" 3 "Not available" ;
VAL_ 2566643198 LockStatusOfDoor20 0 "Unlocked" 1 "Locked" 2 "Error" 3 "Not available" ;
VAL_ 2566643198 OpenStatusOfDoor20 0 "Door closed" 1 "Door opened" 2 "Error" 3 "Not available" ;
VAL_ 2566643198 EnableStatusOfDoor20 0 "Door disabled" 1 "Door enabled" 2 "Error" 3 "Not available" ;
